[part 13 of 22: package /Cluster]
AUTOSAR XML (schema 4-3-0)
package /Cluster  (continued)
  9 x lin cluster, all with baudrate=19200, protocol-name=LIN, protocol-version=2.0:  (continued)
    E3V_SAM_LIN3
      lin physical channel CHNL: comm-connectors=CN_E3V_SAM_LIN3
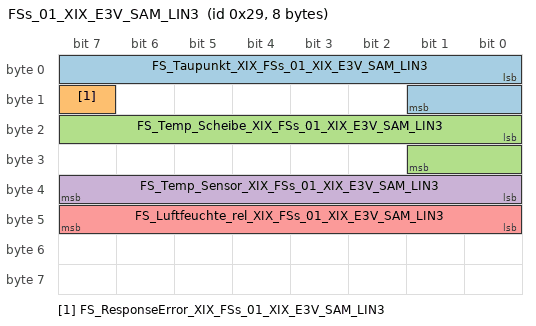
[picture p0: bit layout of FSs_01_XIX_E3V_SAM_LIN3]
        frame FSs_01_XIX_E3V_SAM_LIN3: id 0x29, to SAM, frame-length=8, lin-checksum=ENHANCED
          pdu FSs_01_XIX_E3V_SAM_LIN3: length=8, unused-bit-pattern=0
            signal FS_Taupunkt_XIX_FSs_01_XIX_E3V_SAM_LIN3: start 0, 10 bit, little-endian, data-type-policy=OVERRIDE, i-signal-type=PRIMITIVE, init-value=0, base-type=BT_FS_Taupunkt, invalid-value=Invalid_FS_Taupunkt_XIX_FSs_01_XIX_E3V_SAM_LIN3:1023, compu {0=Cx0_nicht_verfuegbar (CM_FS_Taupunkt_Cx0_nicht_verfuegbar) (nicht verfuegbar), phys=raw*0.1-39.6 for raw 1..1000, 1023=Cx3ff_Fehler (CM_FS_Taupunkt_Cx3ff_Fehler); unit Unit_DegreCelsi}, range phys -39.5..60.4 Unit_DegreCelsi, raw 0..1023, unit=Unit_DegreCelsi, transfer-property=PENDING, to SAM(timeout 3.5 s)  # berechneter Taupunkt
            signal FS_ResponseError_XIX_FSs_01_XIX_E3V_SAM_LIN3: start 15, 1 bit, little-endian, data-type-policy=OVERRIDE, i-signal-type=PRIMITIVE, init-value=0, base-type=BT_FS_ResponseError, invalid-value=Invalid_FS_ResponseError_XIX_FSs_01_XIX_E3V_SAM_LIN3:1, compu {0=Cx0_normal (CM_FS_ResponseError_Cx0_normal), 1=Cx1_Fehler (CM_FS_ResponseError_Cx1_Fehler)}, range raw 0..1, transfer-property=PENDING, to SAM(timeout 3.5 s)  # siehe LIN2.0-Specification (Darf nicht über ein Fehlergueltigkeitsbit abgesichtert werden!)
            signal FS_Temp_Scheibe_XIX_FSs_01_XIX_E3V_SAM_LIN3: start 16, 10 bit, little-endian, data-type-policy=OVERRIDE, i-signal-type=PRIMITIVE, init-value=0, base-type=BT_FS_Temp_Scheibe, invalid-value=Invalid_FS_Temp_Scheibe_XIX_FSs_01_XIX_E3V_SAM_LIN3:1023, compu {0=Cx0_nicht_verfuegbar (CM_FS_Temp_Scheibe_Cx0_nicht_verfuegbar) (nicht verfuegbar), phys=raw*0.1-39.6 for raw 1..1000, 1023=Cx3ff_Fehler (CM_FS_Temp_Scheibe_Cx3ff_Fehler); unit Unit_DegreCelsi}, range phys -39.5..60.4 Unit_DegreCelsi, raw 0..1023, unit=Unit_DegreCelsi, transfer-property=PENDING, to SAM(timeout 3.5 s)  # gemessene Frontscheibentemperatur
            signal FS_Temp_Sensor_XIX_FSs_01_XIX_E3V_SAM_LIN3: start 32, 8 bit, little-endian, data-type-policy=OVERRIDE, i-signal-type=PRIMITIVE, init-value=0, base-type=BT_FS_Temp_Sensor, invalid-value=Invalid_FS_Temp_Sensor_XIX_FSs_01_XIX_E3V_SAM_LIN3:255, compu {0=Cx0_nicht_verfuegbar (CM_FS_Temp_Sensor_Cx0_nicht_verfuegbar) (nicht verfuegbar), phys=raw*0.5-40 for raw 1..254, 255=Cxff_Fehler (CM_FS_Temp_Sensor_Cxff_Fehler); unit Unit_DegreCelsi}, range phys -39.5..87 Unit_DegreCelsi, raw 0..255, unit=Unit_DegreCelsi, transfer-property=PENDING, to SAM(timeout 3.5 s)  # gemessene Sensortemperatur
            signal FS_Luftfeuchte_rel_XIX_FSs_01_XIX_E3V_SAM_LIN3: start 40, 8 bit, little-endian, data-type-policy=OVERRIDE, i-signal-type=PRIMITIVE, init-value=0, base-type=BT_FS_Luftfeuchte_rel, invalid-value=Invalid_FS_Luftfeuchte_rel_XIX_FSs_01_XIX_E3V_SAM_LIN3:255, compu {0=Cx0_nicht_verfuegbar (CM_FS_Luftfeuchte_rel_Cx0_nicht_verfuegbar) (nicht verfuegbar), phys=raw*0.5-0.5 for raw 1..201, 255=Cxff_Fehler (CM_FS_Luftfeuchte_rel_Cxff_Fehler); unit Unit_PerCent}, range phys 0..100 Unit_PerCent, raw 0..255, unit=Unit_PerCent, transfer-property=PENDING, to SAM(timeout 3.5 s)  # gemessene relative Luftfeuchte
        frame LINDae_01_XIX_E3V_SAM_LIN3: id 0x1A, from SAM, frame-length=8, lin-checksum=ENHANCED
          pdu LINDae_01_XIX_E3V_SAM_LIN3: length=8, unused-bit-pattern=0
            signal LIM_P_Mode_XIX_LINDae_01_XIX_E3V_SAM_LIN3: start 3, 1 bit, little-endian, data-type-policy=OVERRIDE, i-signal-type=PRIMITIVE, init-value=0, base-type=BT_LIM_P_Mode, compu {0=Cx0_P_Mode_inaktiv (CM_LIM_P_Mode_Cx0_P_Mode_inaktiv), 1=Cx1_P_Mode_aktiv (CM_LIM_P_Mode_Cx1_P_Mode_aktiv)}, range raw 0..1, transfer-property=PENDING  # P-Mode für LIN-Dachkonsole. Bei aktivem P-Mode sind alle Bedien- und Innenlichtfunktionen der Dachkonsole unterdrückt.
            signal IL_Dachkonsole_Dimmzeit_XIX_LINDae_01_XIX_E3V_SAM_LIN3: start 4, 4 bit, little-endian, data-type-policy=OVERRIDE, i-signal-type=PRIMITIVE, init-value=0, base-type=BT_IL_Dachkonsole_Dimmzeit, compu {phys=raw for raw 0..15; unit Unit_None}, range phys 0..15 Unit_None, raw 0..15, unit=Unit_None, transfer-property=PENDING  # Gibt die Zeit an, in der die Zielhelligkeit des Ausgangs gedimmt erreicht werden soll. Diese sind als Multiplikator der Zeitbasis 250 ms oder 50 ms aufzufassen.
            signal IL_Dachkonsole_Zielhelligkeit_XIX_LINDae_01_XIX_E3V_SAM_LIN3: start 8, 7 bit, little-endian, data-type-policy=OVERRIDE, i-signal-type=PRIMITIVE, init-value=126, base-type=BT_IL_Dachkonsole_Zielhelligkeit, invalid-value=Invalid_IL_Dachkonsole_Zielhelligkeit_XIX_LINDae_01_XIX_E3V_SAM_LIN3:127, compu {phys=raw for raw 0..100, 126=Cx7e_Init (CM_IL_Dachkonsole_Zielhelligkeit_Cx7e_Init), 127=Cx7f_Fehler (CM_IL_Dachkonsole_Zielhelligkeit_Cx7f_Fehler); unit Unit_PerCent}, range phys 0..100 Unit_PerCent, raw 0..127, unit=Unit_PerCent, transfer-property=PENDING  # Gibt den Helligkeits-Sollwert in Prozent an. Zulässig sind Werte zwischen 0 und 100.
            signal IL_Dachkonsole_Zeitbasis_XIX_LINDae_01_XIX_E3V_SAM_LIN3: start 15, 1 bit, little-endian, data-type-policy=OVERRIDE, i-signal-type=PRIMITIVE, init-value=0, base-type=BT_IL_Dachkonsole_Zeitbasis, compu {0=Cx0_Zeitbasis_50_ms (CM_IL_Dachkonsole_Zeitbasis_Cx0_Zeitbasis_50_ms), 1=Cx1_Zeitbasis_250_ms (CM_IL_Dachkonsole_Zeitbasis_Cx1_Zeitbasis_250_ms)}, range raw 0..1, transfer-property=PENDING  # Schaltet zwischen den beiden Zeitbasen für die Dimmung der Innenleuchten um.
            signal IL_Dachkonsole_Adressat_XIX_LINDae_01_XIX_E3V_SAM_LIN3: start 16, 6 bit, little-endian, data-type-policy=OVERRIDE, i-signal-type=PRIMITIVE, init-value=0, base-type=BT_IL_Dachkonsole_Adressat, compu {phys=raw for raw 0..63; unit Unit_None}, range phys 0..63 Unit_None, raw 0..63, unit=Unit_None, transfer-property=PENDING  # Das Signal ist bitcodiert und gibt an, welche Leuchte Empfänger der Helligkeits- und Dimmzeit ist und die gesendeten Informationen umsetzt. Durch die Bitcodierung können null bis sechs Leuchten in einer Botschaft adressiert werden.
            signal bCall_active_XIX_LINDae_01_XIX_E3V_SAM_LIN3: start 22, 1 bit, little-endian, data-type-policy=OVERRIDE, i-signal-type=PRIMITIVE, base-type=BT_bCall_active, compu {0=Cx0_bcall_inactive (CM_bCall_active_Cx0_bcall_inactive), 1=Cx1_bcall_active (CM_bCall_active_Cx1_bcall_active)}, range raw 0..1, transfer-property=PENDING  # 1: Breakdown call is active 0: BreakdownCall is inactive
            signal iCall_active_XIX_LINDae_01_XIX_E3V_SAM_LIN3: start 23, 1 bit, little-endian, data-type-policy=OVERRIDE, i-signal-type=PRIMITIVE, init-value=0, base-type=BT_iCall_active, compu {0=Cx0_inaktiv (CM_iCall_active_Cx0_inaktiv), 1=Cx1_aktiv (CM_iCall_active_Cx1_aktiv)}, range raw 0..1, transfer-property=PENDING  # Statusrückmeldung von OCU über Infocall aktiv/inaktiv
            signal Tuerkontakt_Innenlicht_Status_XIX_LINDae_01_XIX_E3V_SAM_LIN3: start 24, 1 bit, little-endian, data-type-policy=OVERRIDE, i-signal-type=PRIMITIVE, init-value=1, base-type=BT_Tuerkontakt_Innenlicht_Status, compu {0=Cx0_Tuerkontakt_nicht_gesetzt (CM_Tuerkontakt_Innenlicht_Status_Cx0_Tuerkontakt_nicht_gesetzt), 1=Cx1_Tuerkontakt_gesetzt (CM_Tuerkontakt_Innenlicht_Status_Cx1_Tuerkontakt_gesetzt)}, range raw 0..1, transfer-property=PENDING  # Gibt den im BCM gespeicherten Wert über den Kundenwunsch der Türkontakt-Lichtfunktion an. Kann über Dachkonsole oder Personalisierung geändert werden.
            signal MF_Innenraumbel_XIX_LINDae_01_XIX_E3V_SAM_LIN3: start 25, 1 bit, little-endian, data-type-policy=OVERRIDE, i-signal-type=PRIMITIVE, init-value=0, base-type=BT_MF_Innenraumbel, compu {0=Cx0_inaktiv (CM_MF_Innenraumbel_Cx0_inaktiv), 1=Cx1_aktiv (CM_MF_Innenraumbel_Cx1_aktiv)}, range raw 0..1, transfer-property=PENDING  # sämtliche Beleuchtungen akitivieren (Fussraum, Tür u.a.)
            signal MF_Innenraumbel_Unterdrueck_XIX_LINDae_01_XIX_E3V_SAM_LIN3: start 26, 1 bit, little-endian, data-type-policy=OVERRIDE, i-signal-type=PRIMITIVE, init-value=0, base-type=BT_MF_Innenraumbel_Unterdrueck, compu {0=Cx0_inaktiv (CM_MF_Innenraumbel_Unterdrueck_Cx0_inaktiv), 1=Cx1_aktiv (CM_MF_Innenraumbel_Unterdrueck_Cx1_aktiv)}, range raw 0..1, transfer-property=PENDING  # Unterdrückung des Innenlichts/Fussraumbeleuchtung, sowie Schließblinken
            signal SI_QRS_Mode_XIX_LINDae_01_XIX_E3V_SAM_LIN3: start 27, 1 bit, little-endian, data-type-policy=OVERRIDE, i-signal-type=PRIMITIVE, init-value=0, base-type=BT_SI_QRS_Mode, compu {0=Cx0_QRS_Messmodus_nicht_aktiv (CM_SI_QRS_Mode_Cx0_QRS_Messmodus_nicht_aktiv), 1=Cx1_QRS_Messmodus_aktiv (CM_SI_QRS_Mode_Cx1_QRS_Messmodus_aktiv)}, range raw 0..1, transfer-property=PENDING  # Messmodus Quick-Ruhestrom
            signal SI_T_Mode_XIX_LINDae_01_XIX_E3V_SAM_LIN3: start 28, 1 bit, little-endian, data-type-policy=OVERRIDE, i-signal-type=PRIMITIVE, init-value=0, base-type=BT_SI_T_Mode, compu {0=Cx0_Transportmodus_nicht_aktiv (CM_SI_T_Mode_Cx0_Transportmodus_nicht_aktiv), 1=Cx1_Transportmodus_aktiv (CM_SI_T_Mode_Cx1_Transportmodus_aktiv)}, range raw 0..1, transfer-property=PENDING  # 0x0: Transportmodus nicht aktiv 0x1: Transportmodus aktiv
            signal NVEM_Abschaltstufe_XIX_LINDae_01_XIX_E3V_SAM_LIN3: start 29, 2 bit, little-endian, data-type-policy=OVERRIDE, i-signal-type=PRIMITIVE, base-type=BT_NVEM_Abschaltstufe, compu {0=Cx0_Stufe_0_keine_Einschraenkung (CM_NVEM_Abschaltstufe_Cx0_Stufe_0_keine_Einschraenkung), 1=Cx1_Stufe_1 (CM_NVEM_Abschaltstufe_Cx1_Stufe_1), 2=Cx2_Stufe_2 (CM_NVEM_Abschaltstufe_Cx2_Stufe_2), 3=Cx3_Stufe_3 (CM_NVEM_Abschaltstufe_Cx3_Stufe_3)}, range raw 0..3, transfer-property=PENDING  # Abschaltstufe aus dem Ruheenergiemanagement Maßnahmen des Empfängers werden im QLAH Ruhestrommanagement definiert
            signal LINDae_Dummy_4_7_XIX_LINDae_01_XIX_E3V_SAM_LIN3: start 31, 1 bit, little-endian, data-type-policy=OVERRIDE, i-signal-type=PRIMITIVE, init-value=0, base-type=BT_LINDae_Dummy_4_7, compu {phys=raw for raw 0..1; unit Unit_None}, range phys 0..1 Unit_None, raw 0..1, unit=Unit_None, transfer-property=PENDING  # Signal muss dauerhaft mit dem Wert '0' gesendet werden, um Rückwärtskompatibilität beim Empfänger zu gewährleisten.
            signal MD1_Position_XIX_LINDae_01_XIX_E3V_SAM_LIN3: start 32, 7 bit, little-endian, data-type-policy=OVERRIDE, i-signal-type=PRIMITIVE, init-value=126, base-type=BT_MD1_Position, compu {phys=raw for raw 0..100, 126=Cx7e_Init (CM_MD1_Position_Cx7e_Init), 127=Cx7f_nicht_normiert (CM_MD1_Position_Cx7f_nicht_normiert); unit Unit_PerCent}, range phys 0..100 Unit_PerCent, raw 0..127, unit=Unit_PerCent, transfer-property=PENDING  # Aktuelle Öffnungsweite Schiebedach.
            signal MD1_Lage_XIX_LINDae_01_XIX_E3V_SAM_LIN3: start 39, 1 bit, little-endian, data-type-policy=OVERRIDE, i-signal-type=PRIMITIVE, init-value=0, base-type=BT_MD1_Lage, compu {0=Cx0_Ausstelllage (CM_MD1_Lage_Cx0_Ausstelllage), 1=Cx1_Schiebelage (CM_MD1_Lage_Cx1_Schiebelage)}, range raw 0..1, transfer-property=PENDING  # Lage Schiebedachstellung 1 (Signal wird 1:1 vom BCM2 geroutet; ursprünglicher Sender: SAD = LIN-Slave vom BCM2)
            signal DI_KL_58xd_XIX_LINDae_01_XIX_E3V_SAM_LIN3: start 40, 8 bit, little-endian, data-type-policy=OVERRIDE, i-signal-type=PRIMITIVE, init-value=254, base-type=BT_DI_KL_58xd, invalid-value=Invalid_DI_KL_58xd_XIX_LINDae_01_XIX_E3V_SAM_LIN3:255, compu {phys=raw for raw 0..253, 254=Cxfe_Init (CM_DI_KL_58xd_Cxfe_Init), 255=Cxff_Fehler (CM_DI_KL_58xd_Cxff_Fehler)}, range phys 0..253, raw 0..255, transfer-property=PENDING  # Klemme 58xd Display- und Funktionsbeleuchtung Mit der Klemme 58xd wird die Helligkeit der Display- und der Funktionsbeleuchtungen der Schalter gesteuert. Im Detail beschrieben im 'Funktionslastenheft Dimmung MQB'.
            signal DI_KL_58xs_XIX_LINDae_01_XIX_E3V_SAM_LIN3: start 48, 7 bit, little-endian, data-type-policy=OVERRIDE, i-signal-type=PRIMITIVE, init-value=126, base-type=BT_DI_KL_58xs, invalid-value=Invalid_DI_KL_58xs_XIX_LINDae_01_XIX_E3V_SAM_LIN3:127, compu {phys=raw for raw 0..100, 126=Cx7e_Init (CM_DI_KL_58xs_Cx7e_Init), 127=Cx7f_Fehler (CM_DI_KL_58xs_Cx7f_Fehler); unit Unit_PerCent}, range phys 0..100 Unit_PerCent, raw 0..127, unit=Unit_PerCent, transfer-property=PENDING  # Suchbeleuchtung Schalter EIN-AUS-Schaltalgorithmus der allgemeinen Schaltersuchbeleuchtung. Im Detail beschrieben im 'Funktionslastenheft Dimmung MQB'.
            signal IL_Klemme_30G_aktiv_XIX_LINDae_01_XIX_E3V_SAM_LIN3: start 55, 1 bit, little-endian, data-type-policy=OVERRIDE, i-signal-type=PRIMITIVE, init-value=0, base-type=BT_IL_Klemme_30G_aktiv, compu {0=Cx0_Kl_30G_abgeschaltet (CM_IL_Klemme_30G_aktiv_Cx0_Kl_30G_abgeschaltet), 1=Cx1_eingeschaltet (CM_IL_Klemme_30G_aktiv_Cx1_eingeschaltet)}, range raw 0..1, transfer-property=PENDING  # Synchrones Abschalten
            signal DI_KL_58xt_XIX_LINDae_01_XIX_E3V_SAM_LIN3: start 56, 7 bit, little-endian, data-type-policy=OVERRIDE, i-signal-type=PRIMITIVE, init-value=126, base-type=BT_DI_KL_58xt, invalid-value=Invalid_DI_KL_58xt_XIX_LINDae_01_XIX_E3V_SAM_LIN3:127, compu {phys=raw for raw 0..100, 126=Cx7e_Init (CM_DI_KL_58xt_Cx7e_Init), 127=Cx7f_Fehler (CM_DI_KL_58xt_Cx7f_Fehler); unit Unit_PerCent}, range phys 0..100 Unit_PerCent, raw 0..127, unit=Unit_PerCent, transfer-property=PENDING  # Timergesteuerte Suchbeleuchtung Der EIN-AUS-Schaltalgorithmus für die vor- und nachlaufende Schaltersuchbeleuchtungen beim Ein- & Aussteigen; z.B.: Start/Stop-Taster. Im Detail beschrieben im 'Funktionslastenheft Dimmung MQB'.
            signal Klemme_15_XIX_LINDae_01_XIX_E3V_SAM_LIN3: start 63, 1 bit, little-endian, data-type-policy=OVERRIDE, i-signal-type=PRIMITIVE, init-value=0, base-type=BT_Klemme_15, compu {0=Cx0_Aus (CM_Klemme_15_Cx0_Aus), 1=Cx1_Ein (CM_Klemme_15_Cx1_Ein)}, range raw 0..1, transfer-property=PENDING
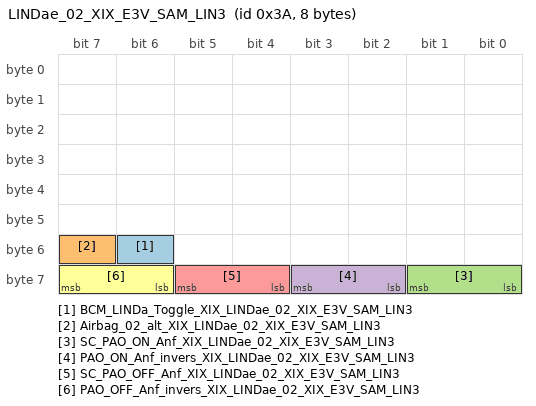
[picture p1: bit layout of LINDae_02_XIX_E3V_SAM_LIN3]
        frame LINDae_02_XIX_E3V_SAM_LIN3: id 0x3A, from SAM, frame-length=8, lin-checksum=ENHANCED
          pdu LINDae_02_XIX_E3V_SAM_LIN3: length=8, unused-bit-pattern=0
            signal BCM_LINDa_Toggle_XIX_LINDae_02_XIX_E3V_SAM_LIN3: start 54, 1 bit, little-endian, data-type-policy=OVERRIDE, i-signal-type=PRIMITIVE, base-type=BT_BCM_LINDa_Toggle, compu {phys=raw for raw 0..1; unit Unit_None}, range phys 0..1 Unit_None, raw 0..1, unit=Unit_None, transfer-property=PENDING  # Togglebit zur Kommunikationsabsicherung (ASIL A). Wert wird mit jedem Senden der Botschaft getoggelt.
            signal Airbag_02_alt_XIX_LINDae_02_XIX_E3V_SAM_LIN3: start 55, 1 bit, little-endian, data-type-policy=OVERRIDE, i-signal-type=PRIMITIVE, init-value=1, base-type=BT_Airbag_02_alt, compu {0=Cx0_aktuell (CM_Airbag_02_alt_Cx0_aktuell), 1=Cx1_veraltet (CM_Airbag_02_alt_Cx1_veraltet)}, range raw 0..1, transfer-property=PENDING
            signal SC_PAO_ON_Anf_XIX_LINDae_02_XIX_E3V_SAM_LIN3: start 56, 2 bit, little-endian, data-type-policy=OVERRIDE, i-signal-type=PRIMITIVE, init-value=0, base-type=BT_SC_PAO_ON_Anf, compu {0=Cx0_LED_aus (CM_SC_PAO_ON_Anf_Cx0_LED_aus) (LED aus), 1=Cx1_LED_an (CM_SC_PAO_ON_Anf_Cx1_LED_an) (LED an), 2=Cx2_LED_blinken (CM_SC_PAO_ON_Anf_Cx2_LED_blinken) (LED blinken), 3=Cx3_reserviert (CM_SC_PAO_ON_Anf_Cx3_reserviert)}, range raw 0..3, transfer-property=PENDING  # Sollwert für LED "ON" in Anzeige Passenger Airbag On/Off
            signal PAO_ON_Anf_invers_XIX_LINDae_02_XIX_E3V_SAM_LIN3: start 58, 2 bit, little-endian, data-type-policy=OVERRIDE, i-signal-type=PRIMITIVE, init-value=3, base-type=BT_PAO_ON_Anf_invers, compu {0=Cx0_reserviert (CM_PAO_ON_Anf_invers_Cx0_reserviert), 1=Cx1_LED_blinken (CM_PAO_ON_Anf_invers_Cx1_LED_blinken), 2=Cx2_LED_an (CM_PAO_ON_Anf_invers_Cx2_LED_an), 3=Cx3_LED_aus (CM_PAO_ON_Anf_invers_Cx3_LED_aus)}, range raw 0..3, transfer-property=PENDING  # Inverssignal Sollwert für LED "ON" in Anzeige Passenger Airbag On/Off
            signal SC_PAO_OFF_Anf_XIX_LINDae_02_XIX_E3V_SAM_LIN3: start 60, 2 bit, little-endian, data-type-policy=OVERRIDE, i-signal-type=PRIMITIVE, init-value=0, base-type=BT_SC_PAO_OFF_Anf, compu {0=Cx0_LED_aus (CM_SC_PAO_OFF_Anf_Cx0_LED_aus) (LED aus), 1=Cx1_LED_an (CM_SC_PAO_OFF_Anf_Cx1_LED_an) (LED an), 2=Cx2_LED_blinken (CM_SC_PAO_OFF_Anf_Cx2_LED_blinken) (LED blinken), 3=Cx3_reserviert (CM_SC_PAO_OFF_Anf_Cx3_reserviert)}, range raw 0..3, transfer-property=PENDING  # Sollwert für LED "OFF" in Anzeige Passenger Airbag On/Off
            signal PAO_OFF_Anf_invers_XIX_LINDae_02_XIX_E3V_SAM_LIN3: start 62, 2 bit, little-endian, data-type-policy=OVERRIDE, i-signal-type=PRIMITIVE, init-value=3, base-type=BT_PAO_OFF_Anf_invers, compu {0=Cx0_reserviert (CM_PAO_OFF_Anf_invers_Cx0_reserviert), 1=Cx1_LED_blinken (CM_PAO_OFF_Anf_invers_Cx1_LED_blinken), 2=Cx2_LED_an (CM_PAO_OFF_Anf_invers_Cx2_LED_an), 3=Cx3_LED_aus (CM_PAO_OFF_Anf_invers_Cx3_LED_aus)}, range raw 0..3, transfer-property=PENDING  # Inverssignal Sollwert für LED "OFF" in Anzeige Passenger Airbag On/Off
        frame LINDas_01_XIX_E3V_SAM_LIN3: id 0xF, to SAM, frame-length=8, lin-checksum=ENHANCED
          pdu LINDas_01_XIX_E3V_SAM_LIN3: length=8, unused-bit-pattern=0
            signal LINDa_reserveByte1_XIX_LINDas_01_XIX_E3V_SAM_LIN3: start 0, 8 bit, little-endian, data-type-policy=OVERRIDE, i-signal-type=PRIMITIVE, init-value=0, base-type=BT_LINDa_reserveByte1, transfer-property=PENDING  # Zweck: Befüllen der reservierten Bitpositionen mit 0
            signal LINDa_reserveByte2_XIX_LINDas_01_XIX_E3V_SAM_LIN3: start 8, 8 bit, little-endian, data-type-policy=OVERRIDE, i-signal-type=PRIMITIVE, init-value=0, base-type=BT_LINDa_reserveByte2, transfer-property=PENDING  # Zweck: Befüllen der reservierten Bitpositionen mit 0
            signal LINDa_reserveByte3_XIX_LINDas_01_XIX_E3V_SAM_LIN3: start 16, 4 bit, little-endian, data-type-policy=OVERRIDE, i-signal-type=PRIMITIVE, init-value=0, base-type=BT_LINDa_reserveByte3, transfer-property=PENDING  # Zweck: Befüllen der reservierten Bitpositionen mit 0
            signal LINDa_HL_Touch_Event_XIX_LINDas_01_XIX_E3V_SAM_LIN3: start 20, 4 bit, little-endian, data-type-policy=OVERRIDE, i-signal-type=PRIMITIVE, init-value=0, base-type=BT_LINDa_HL_Touch_Event, invalid-value=Invalid_LINDa_HL_Touch_Event_XIX_LINDas_01_XIX_E3V_SAM_LIN3:15, compu {0=Cx0_nicht_betaetigt (CM_LINDa_HL_Touch_Event_Cx0_nicht_betaetigt), 1=Cx1_Tippen (CM_LINDa_HL_Touch_Event_Cx1_Tippen), 2=Cx2_Wischen_Slide (CM_LINDa_HL_Touch_Event_Cx2_Wischen_Slide), 3=Cx3_Geste (CM_LINDa_HL_Touch_Event_Cx3_Geste), 4=Cx4_Doppeltippen (CM_LINDa_HL_Touch_Event_Cx4_Doppeltippen), 5=Cx5_Longpress_1 (CM_LINDa_HL_Touch_Event_Cx5_Longpress_1), 6=Cx6_Longpress_2 (CM_LINDa_HL_Touch_Event_Cx6_Longpress_2), 7=Cx7_Longpress_3 (CM_LINDa_HL_Touch_Event_Cx7_Longpress_3), 8=Cx8_Press (CM_LINDa_HL_Touch_Event_Cx8_Press), 9=Cx9_Strongpress (CM_LINDa_HL_Touch_Event_Cx9_Strongpress), 10=Cxa_reserviert (CM_LINDa_HL_Touch_Event_Cxa_reserviert), 11=Cxb_reserviert (CM_LINDa_HL_Touch_Event_Cxb_reserviert), 12=Cxc_reserviert (CM_LINDa_HL_Touch_Event_Cxc_reserviert), 13=Cxd_reserviert (CM_LINDa_HL_Touch_Event_Cxd_reserviert), 14=Cxe_Taktgeber_Inkrement (CM_LINDa_HL_Touch_Event_Cxe_Taktgeber_Inkrement), 15=Cxf_Fehler (CM_LINDa_HL_Touch_Event_Cxf_Fehler)}, range raw 0..15, transfer-property=PENDING, to SAM  # Touch_Events für Informationen einer Funktionsauslösung auf dem LINDa, welches dann für bspw. ein akustisches Signal zentral umgesetzt werden können.
            signal LINDa_HR_Touch_Event_XIX_LINDas_01_XIX_E3V_SAM_LIN3: start 24, 4 bit, little-endian, data-type-policy=OVERRIDE, i-signal-type=PRIMITIVE, init-value=0, base-type=BT_LINDa_HR_Touch_Event, invalid-value=Invalid_LINDa_HR_Touch_Event_XIX_LINDas_01_XIX_E3V_SAM_LIN3:15, compu {0=Cx0_nicht_betaetigt (CM_LINDa_HR_Touch_Event_Cx0_nicht_betaetigt), 1=Cx1_Tippen (CM_LINDa_HR_Touch_Event_Cx1_Tippen), 2=Cx2_Wischen_Slide (CM_LINDa_HR_Touch_Event_Cx2_Wischen_Slide), 3=Cx3_Geste (CM_LINDa_HR_Touch_Event_Cx3_Geste), 4=Cx4_Doppeltippen (CM_LINDa_HR_Touch_Event_Cx4_Doppeltippen), 5=Cx5_Longpress_1 (CM_LINDa_HR_Touch_Event_Cx5_Longpress_1), 6=Cx6_Longpress_2 (CM_LINDa_HR_Touch_Event_Cx6_Longpress_2), 7=Cx7_Longpress_3 (CM_LINDa_HR_Touch_Event_Cx7_Longpress_3), 8=Cx8_Press (CM_LINDa_HR_Touch_Event_Cx8_Press), 9=Cx9_Strongpress (CM_LINDa_HR_Touch_Event_Cx9_Strongpress), 10=Cxa_reserviert (CM_LINDa_HR_Touch_Event_Cxa_reserviert), 11=Cxb_reserviert (CM_LINDa_HR_Touch_Event_Cxb_reserviert), 12=Cxc_reserviert (CM_LINDa_HR_Touch_Event_Cxc_reserviert), 13=Cxd_reserviert (CM_LINDa_HR_Touch_Event_Cxd_reserviert), 14=Cxe_Taktgeber_Inkrement (CM_LINDa_HR_Touch_Event_Cxe_Taktgeber_Inkrement), 15=Cxf_Fehler (CM_LINDa_HR_Touch_Event_Cxf_Fehler)}, range raw 0..15, transfer-property=PENDING, to SAM  # Touch_Events für Informationen einer Funktionsauslösung auf dem LINDa, welches dann für bspw. ein akustisches Signal zentral umgesetzt werden können.
            signal LINDa_HL_SR3_Touch_Event_XIX_LINDas_01_XIX_E3V_SAM_LIN3: start 28, 4 bit, little-endian, data-type-policy=OVERRIDE, i-signal-type=PRIMITIVE, init-value=0, base-type=BT_LINDa_HL_SR3_Touch_Event, invalid-value=Invalid_LINDa_HL_SR3_Touch_Event_XIX_LINDas_01_XIX_E3V_SAM_LIN3:15, compu {0=Cx0_nicht_betaetigt (CM_LINDa_HL_SR3_Touch_Event_Cx0_nicht_betaetigt), 1=Cx1_Tippen (CM_LINDa_HL_SR3_Touch_Event_Cx1_Tippen), 2=Cx2_Wischen_Slide (CM_LINDa_HL_SR3_Touch_Event_Cx2_Wischen_Slide), 3=Cx3_Geste (CM_LINDa_HL_SR3_Touch_Event_Cx3_Geste), 4=Cx4_Doppeltippen (CM_LINDa_HL_SR3_Touch_Event_Cx4_Doppeltippen), 5=Cx5_Longpress_1 (CM_LINDa_HL_SR3_Touch_Event_Cx5_Longpress_1), 6=Cx6_Longpress_2 (CM_LINDa_HL_SR3_Touch_Event_Cx6_Longpress_2), 7=Cx7_Longpress_3 (CM_LINDa_HL_SR3_Touch_Event_Cx7_Longpress_3), 8=Cx8_Press (CM_LINDa_HL_SR3_Touch_Event_Cx8_Press), 9=Cx9_Strongpress (CM_LINDa_HL_SR3_Touch_Event_Cx9_Strongpress), 10=Cxa_reserviert (CM_LINDa_HL_SR3_Touch_Event_Cxa_reserviert), 11=Cxb_reserviert (CM_LINDa_HL_SR3_Touch_Event_Cxb_reserviert), 12=Cxc_reserviert (CM_LINDa_HL_SR3_Touch_Event_Cxc_reserviert), 13=Cxd_reserviert (CM_LINDa_HL_SR3_Touch_Event_Cxd_reserviert), 14=Cxe_Taktgeber_Inkrement (CM_LINDa_HL_SR3_Touch_Event_Cxe_Taktgeber_Inkrement), 15=Cxf_Fehler (CM_LINDa_HL_SR3_Touch_Event_Cxf_Fehler)}, range raw 0..15, transfer-property=PENDING, to SAM  # Touch_Events für Informationen einer Funktionsauslösung auf dem LINDa (hinten links SR3) , welches dann für bspw. ein akustisches Signal zentral umgesetzt werden können.
            signal LINDa_HR_SR3_Touch_Event_XIX_LINDas_01_XIX_E3V_SAM_LIN3: start 32, 4 bit, little-endian, data-type-policy=OVERRIDE, i-signal-type=PRIMITIVE, init-value=0, base-type=BT_LINDa_HR_SR3_Touch_Event, invalid-value=Invalid_LINDa_HR_SR3_Touch_Event_XIX_LINDas_01_XIX_E3V_SAM_LIN3:15, compu {0=Cx0_nicht_betaetigt (CM_LINDa_HR_SR3_Touch_Event_Cx0_nicht_betaetigt), 1=Cx1_Tippen (CM_LINDa_HR_SR3_Touch_Event_Cx1_Tippen), 2=Cx2_Wischen_Slide (CM_LINDa_HR_SR3_Touch_Event_Cx2_Wischen_Slide), 3=Cx3_Geste (CM_LINDa_HR_SR3_Touch_Event_Cx3_Geste), 4=Cx4_Doppeltippen (CM_LINDa_HR_SR3_Touch_Event_Cx4_Doppeltippen), 5=Cx5_Longpress_1 (CM_LINDa_HR_SR3_Touch_Event_Cx5_Longpress_1), 6=Cx6_Longpress_2 (CM_LINDa_HR_SR3_Touch_Event_Cx6_Longpress_2), 7=Cx7_Longpress_3 (CM_LINDa_HR_SR3_Touch_Event_Cx7_Longpress_3), 8=Cx8_Press (CM_LINDa_HR_SR3_Touch_Event_Cx8_Press), 9=Cx9_Strongpress (CM_LINDa_HR_SR3_Touch_Event_Cx9_Strongpress), 10=Cxa_reserviert (CM_LINDa_HR_SR3_Touch_Event_Cxa_reserviert), 11=Cxb_reserviert (CM_LINDa_HR_SR3_Touch_Event_Cxb_reserviert), 12=Cxc_reserviert (CM_LINDa_HR_SR3_Touch_Event_Cxc_reserviert), 13=Cxd_reserviert (CM_LINDa_HR_SR3_Touch_Event_Cxd_reserviert), 14=Cxe_Taktgeber_Inkrement (CM_LINDa_HR_SR3_Touch_Event_Cxe_Taktgeber_Inkrement), 15=Cxf_Fehler (CM_LINDa_HR_SR3_Touch_Event_Cxf_Fehler)}, range raw 0..15, transfer-property=PENDING, to SAM  # Touch_Events für Informationen einer Funktionsauslösung auf dem LINDa (hinten rechts SR3), welches dann für bspw. ein akustisches Signal zentral umgesetzt werden können.
            signal LINDa_reserveByte5_4_XIX_LINDas_01_XIX_E3V_SAM_LIN3: start 36, 2 bit, little-endian, data-type-policy=OVERRIDE, i-signal-type=PRIMITIVE, init-value=0, base-type=BT_LINDa_reserveByte5_4, transfer-property=PENDING  # Zweck: Befüllen der reservierten Bitpositionen mit 0
            signal Leselicht_hi_li_SR3_LED_defekt_XIX_LINDas_01_XIX_E3V_SAM_LIN3: start 38, 1 bit, little-endian, data-type-policy=OVERRIDE, i-signal-type=PRIMITIVE, init-value=0, base-type=BT_Leselicht_hi_li_SR3_LED_defekt, compu {0=Cx0_Leselicht_hi_li_SR3_iO (CM_Leselicht_hi_li_SR3_LED_defekt_Cx0_Leselicht_hi_li_SR3_iO), 1=Cx1_Leselicht_hi_li_SR3_defekt (CM_Leselicht_hi_li_SR3_LED_defekt_Cx1_Leselicht_hi_li_SR3_defekt)}, range raw 0..1, transfer-property=PENDING, to SAM(timeout 3.5 s)  # Funktionszustand Leselicht-LED der dritten Sitzreihe hinten links
            signal Leselicht_hi_li_SR3_Taste_defekt_XIX_LINDas_01_XIX_E3V_SAM_LIN3: start 39, 1 bit, little-endian, data-type-policy=OVERRIDE, i-signal-type=PRIMITIVE, init-value=0, base-type=BT_Leselicht_hi_li_SR3_Taste_defekt, compu {0=Cx0_Leselicht_hi_li_SR3_Taste_iO (CM_Leselicht_hi_li_SR3_Taste_defekt_Cx0_Leselicht_hi_li_SR3_Taste_iO), 1=Cx1_Leselicht_hi_li_SR3_Taste_defekt (CM_Leselicht_hi_li_SR3_Taste_defekt_Cx1_Leselicht_hi_li_SR3_Taste_defekt)}, range raw 0..1, transfer-property=PENDING, to SAM(timeout 3.5 s)  # Funktionszustand Leselicht-Taste der dritten Sitzreihe hinten links
            signal Leselicht_hi_re_SR3_LED_defekt_XIX_LINDas_01_XIX_E3V_SAM_LIN3: start 40, 1 bit, little-endian, data-type-policy=OVERRIDE, i-signal-type=PRIMITIVE, init-value=0, base-type=BT_Leselicht_hi_re_SR3_LED_defekt, compu {0=Cx0_Leselicht_hi_re_SR3_iO (CM_Leselicht_hi_re_SR3_LED_defekt_Cx0_Leselicht_hi_re_SR3_iO), 1=Cx1_Leselicht_hi_re_SR3_defekt (CM_Leselicht_hi_re_SR3_LED_defekt_Cx1_Leselicht_hi_re_SR3_defekt)}, range raw 0..1, transfer-property=PENDING, to SAM(timeout 3.5 s)  # Funktionszustand Leselicht-LED der dritten Sitzreihe hinten rechts
            signal Leselicht_hi_re_SR3_Taste_defekt_XIX_LINDas_01_XIX_E3V_SAM_LIN3: start 41, 1 bit, little-endian, data-type-policy=OVERRIDE, i-signal-type=PRIMITIVE, init-value=0, base-type=BT_Leselicht_hi_re_SR3_Taste_defekt, compu {0=Cx0_Leselicht_hi_re_SR3_Taste_iO (CM_Leselicht_hi_re_SR3_Taste_defekt_Cx0_Leselicht_hi_re_SR3_Taste_iO), 1=Cx1_Leselicht_hi_re_SR3_Taste_defekt (CM_Leselicht_hi_re_SR3_Taste_defekt_Cx1_Leselicht_hi_re_SR3_Taste_defekt)}, range raw 0..1, transfer-property=PENDING, to SAM(timeout 3.5 s)  # Funktionszustand Leselicht-Taste der dritten Sitzreihe hinten rechts
            signal LINDa_Touch_Event_XIX_LINDas_01_XIX_E3V_SAM_LIN3: start 42, 4 bit, little-endian, data-type-policy=OVERRIDE, i-signal-type=PRIMITIVE, init-value=0, base-type=BT_LINDa_Touch_Event, invalid-value=Invalid_LINDa_Touch_Event_XIX_LINDas_01_XIX_E3V_SAM_LIN3:15, compu {0=Cx0_nicht_betaetigt (CM_LINDa_Touch_Event_Cx0_nicht_betaetigt), 1=Cx1_Tippen (CM_LINDa_Touch_Event_Cx1_Tippen), 2=Cx2_Wischen_Slide (CM_LINDa_Touch_Event_Cx2_Wischen_Slide), 3=Cx3_Geste (CM_LINDa_Touch_Event_Cx3_Geste), 4=Cx4_Doppeltippen (CM_LINDa_Touch_Event_Cx4_Doppeltippen), 5=Cx5_Longpress_1 (CM_LINDa_Touch_Event_Cx5_Longpress_1), 6=Cx6_Longpress_2 (CM_LINDa_Touch_Event_Cx6_Longpress_2), 7=Cx7_Longpress_3 (CM_LINDa_Touch_Event_Cx7_Longpress_3), 8=Cx8_Press (CM_LINDa_Touch_Event_Cx8_Press), 9=Cx9_Strongpress (CM_LINDa_Touch_Event_Cx9_Strongpress), 10=Cxa_reserviert (CM_LINDa_Touch_Event_Cxa_reserviert), 11=Cxb_reserviert (CM_LINDa_Touch_Event_Cxb_reserviert), 12=Cxc_reserviert (CM_LINDa_Touch_Event_Cxc_reserviert), 13=Cxd_reserviert (CM_LINDa_Touch_Event_Cxd_reserviert), 14=Cxe_Taktgeber_Inkrement (CM_LINDa_Touch_Event_Cxe_Taktgeber_Inkrement), 15=Cxf_Fehler (CM_LINDa_Touch_Event_Cxf_Fehler)}, range raw 0..15, transfer-property=PENDING, to SAM  # Touch_Events für Informationen einer Funktionsauslösung auf dem LINDa, welches dann für bspw. ein akustisches Signal zentral umgesetzt werden können.
            signal Tuerkontakt_Innenlicht_Taste_XIX_LINDas_01_XIX_E3V_SAM_LIN3: start 46, 1 bit, little-endian, data-type-policy=OVERRIDE, i-signal-type=PRIMITIVE, init-value=0, base-type=BT_Tuerkontakt_Innenlicht_Taste, compu {0=Cx0_Taste_unbetaetigt (CM_Tuerkontakt_Innenlicht_Taste_Cx0_Taste_unbetaetigt), 1=Cx1_Taste_betaetigt (CM_Tuerkontakt_Innenlicht_Taste_Cx1_Taste_betaetigt)}, range raw 0..1, transfer-property=PENDING, to SAM(timeout 3.5 s)  # Taste zum Ändern des Türkontakt-Lichtfunktionszustandes.
            signal LIM_iCall_Taster_XIX_LINDas_01_XIX_E3V_SAM_LIN3: start 47, 1 bit, little-endian, data-type-policy=OVERRIDE, i-signal-type=PRIMITIVE, init-value=0, base-type=BT_LIM_iCall_Taster, compu {0=Cx0_nicht_betaetigt (CM_LIM_iCall_Taster_Cx0_nicht_betaetigt), 1=Cx1_betaetigt (CM_LIM_iCall_Taster_Cx1_betaetigt)}, range raw 0..1, transfer-property=PENDING, to SAM  # Betätigungsstatus des Info Call Tasters im Dachmodul
            signal LIM_S_SAD_Vo_XIX_LINDas_01_XIX_E3V_SAM_LIN3: start 48, 4 bit, little-endian, data-type-policy=OVERRIDE, i-signal-type=PRIMITIVE, init-value=0, base-type=BT_LIM_S_SAD_Vo, compu {0=Cx0_nicht_betaetigt (CM_LIM_S_SAD_Vo_Cx0_nicht_betaetigt), 1=Cx1_man_sl_zu (CM_LIM_S_SAD_Vo_Cx1_man_sl_zu), 2=Cx2_auto_sl_zu (CM_LIM_S_SAD_Vo_Cx2_auto_sl_zu), 3=Cx3_man_sl_auf (CM_LIM_S_SAD_Vo_Cx3_man_sl_auf), 4=Cx4_auto_sl_auf (CM_LIM_S_SAD_Vo_Cx4_auto_sl_auf), 5=Cx5_man_al_auf (CM_LIM_S_SAD_Vo_Cx5_man_al_auf), 6=Cx6_auto_al_auf (CM_LIM_S_SAD_Vo_Cx6_auto_al_auf), 7=Cx7_man_al_zu (CM_LIM_S_SAD_Vo_Cx7_man_al_zu), 8=Cx8_auto_al_zu (CM_LIM_S_SAD_Vo_Cx8_auto_al_zu), 9=Cx9_stop (CM_LIM_S_SAD_Vo_Cx9_stop), 10=Cxa_Toggle_Taster_AL_betaetigt (CM_LIM_S_SAD_Vo_Cxa_Toggle_Taster_AL_betaetigt), 14=Cxe_fehler_schalter_haengt (CM_LIM_S_SAD_Vo_Cxe_fehler_schalter_haengt), 15=Cxf_fehler_schalter_unplausibel (CM_LIM_S_SAD_Vo_Cxf_fehler_schalter_unplausibel)}, range raw 0..15, transfer-property=PENDING, to SAM  # Schalterfeld LIM für SAD vorne
            signal LINDa_S_Rollo_vo_XIX_LINDas_01_XIX_E3V_SAM_LIN3: start 52, 3 bit, little-endian, data-type-policy=OVERRIDE, i-signal-type=PRIMITIVE, init-value=0, base-type=BT_LINDa_S_Rollo_vo, compu {0=Cx0_nicht_betaetigt (CM_LINDa_S_Rollo_vo_Cx0_nicht_betaetigt), 1=Cx1_man_betaetigung_nach_fzg_vorne (CM_LINDa_S_Rollo_vo_Cx1_man_betaetigung_nach_fzg_vorne), 2=Cx2_auto_betaetigung_nach_fzg_vorne (CM_LINDa_S_Rollo_vo_Cx2_auto_betaetigung_nach_fzg_vorne), 3=Cx3_man_betaetigung_nach_fzg_hinten (CM_LINDa_S_Rollo_vo_Cx3_man_betaetigung_nach_fzg_hinten), 4=Cx4_auto_betaetigung_nach_fzg_hinten (CM_LINDa_S_Rollo_vo_Cx4_auto_betaetigung_nach_fzg_hinten), 5=Cx5_stopp (CM_LINDa_S_Rollo_vo_Cx5_stopp), 6=Cx6_fehler_bedienteil_haengt (CM_LINDa_S_Rollo_vo_Cx6_fehler_bedienteil_haengt), 7=Cx7_fehler_bedienteil_unplausibel (CM_LINDa_S_Rollo_vo_Cx7_fehler_bedienteil_unplausibel)}, range raw 0..7, transfer-property=PENDING, to SAM(timeout 3.5 s)  # Zur Ansteuerung des Panorama-(Schiebe-)Dach Sonnenrollos. Die uneinheitliche Verbauposition des Sonnenrollos in verschiedenen Fahrzeughüten bedingt ein Signal, in dem nur die Fahrtrichtung des Rollos vorgegeben ist, aber nicht öffnen/schließen.
            signal LIM_bCall_Taster_XIX_LINDas_01_XIX_E3V_SAM_LIN3: start 55, 1 bit, little-endian, data-type-policy=OVERRIDE, i-signal-type=PRIMITIVE, init-value=0, base-type=BT_LIM_bCall_Taster, compu {0=Cx0_nicht_betaetigt (CM_LIM_bCall_Taster_Cx0_nicht_betaetigt), 1=Cx1_betaetigt (CM_LIM_bCall_Taster_Cx1_betaetigt)}, range raw 0..1, transfer-property=PENDING, to SAM  # Statusinformation des Service Call Tasters im Dachmodul
            signal Leselicht_hi_li_LED_defekt_XIX_LINDas_01_XIX_E3V_SAM_LIN3: start 56, 1 bit, little-endian, data-type-policy=OVERRIDE, i-signal-type=PRIMITIVE, init-value=0, base-type=BT_Leselicht_hi_li_LED_defekt, compu {0=Cx0_Leselicht_hi_li_iO (CM_Leselicht_hi_li_LED_defekt_Cx0_Leselicht_hi_li_iO), 1=Cx1_Leselicht_hi_li_defekt (CM_Leselicht_hi_li_LED_defekt_Cx1_Leselicht_hi_li_defekt)}, range raw 0..1, transfer-property=PENDING, to SAM(timeout 3.5 s)  # Funktionszustand Leselicht-LED hinten links
            signal Leselicht_hi_li_Taste_defekt_XIX_LINDas_01_XIX_E3V_SAM_LIN3: start 57, 1 bit, little-endian, data-type-policy=OVERRIDE, i-signal-type=PRIMITIVE, init-value=0, base-type=BT_Leselicht_hi_li_Taste_defekt, compu {0=Cx0_Leselicht_hi_li_Taste_iO (CM_Leselicht_hi_li_Taste_defekt_Cx0_Leselicht_hi_li_Taste_iO), 1=Cx1_Leselicht_hi_li_Taste_defekt (CM_Leselicht_hi_li_Taste_defekt_Cx1_Leselicht_hi_li_Taste_defekt)}, range raw 0..1, transfer-property=PENDING, to SAM(timeout 3.5 s)  # Funktionszustand Leselicht-Taste hinten links
            signal Leselicht_hi_re_LED_defekt_XIX_LINDas_01_XIX_E3V_SAM_LIN3: start 58, 1 bit, little-endian, data-type-policy=OVERRIDE, i-signal-type=PRIMITIVE, init-value=0, base-type=BT_Leselicht_hi_re_LED_defekt, compu {0=Cx0_Leselicht_hi_re_iO (CM_Leselicht_hi_re_LED_defekt_Cx0_Leselicht_hi_re_iO), 1=Cx1_Leselicht_hi_re_defekt (CM_Leselicht_hi_re_LED_defekt_Cx1_Leselicht_hi_re_defekt)}, range raw 0..1, transfer-property=PENDING, to SAM(timeout 3.5 s)  # Funktionszustand Leselicht-LED hinten rechts
            signal Leselicht_hi_re_Taste_defekt_XIX_LINDas_01_XIX_E3V_SAM_LIN3: start 59, 1 bit, little-endian, data-type-policy=OVERRIDE, i-signal-type=PRIMITIVE, init-value=0, base-type=BT_Leselicht_hi_re_Taste_defekt, compu {0=Cx0_Leselicht_hi_re_Taste_iO (CM_Leselicht_hi_re_Taste_defekt_Cx0_Leselicht_hi_re_Taste_iO), 1=Cx1_Leselicht_hi_re_Taste_defekt (CM_Leselicht_hi_re_Taste_defekt_Cx1_Leselicht_hi_re_Taste_defekt)}, range raw 0..1, transfer-property=PENDING, to SAM(timeout 3.5 s)  # Funktionszustand Leselicht-Taste hinten rechts
            signal Leselicht_vo_defekt_XIX_LINDas_01_XIX_E3V_SAM_LIN3: start 60, 1 bit, little-endian, data-type-policy=OVERRIDE, i-signal-type=PRIMITIVE, init-value=0, base-type=BT_Leselicht_vo_defekt, compu {0=Cx0_Leselicht_iO (CM_Leselicht_vo_defekt_Cx0_Leselicht_iO), 1=Cx1_Leselicht_defekt (CM_Leselicht_vo_defekt_Cx1_Leselicht_defekt)}, range raw 0..1, transfer-property=PENDING, to SAM(timeout 3.5 s)  # Funktionszustand vorderes Leselicht (Fahrer/Beifahrer)
            signal LIM_Tasten_Innenlicht_V_def_XIX_LINDas_01_XIX_E3V_SAM_LIN3: start 61, 1 bit, little-endian, data-type-policy=OVERRIDE, i-signal-type=PRIMITIVE, init-value=0, base-type=BT_LIM_Tasten_Innenlicht_V_def, invalid-value=Invalid_LIM_Tasten_Innenlicht_V_def_XIX_LINDas_01_XIX_E3V_SAM_LIN3:1, compu {0=Cx0_normal (CM_LIM_Tasten_Innenlicht_V_def_Cx0_normal), 1=Cx1_Fehler (CM_LIM_Tasten_Innenlicht_V_def_Cx1_Fehler)}, range raw 0..1, transfer-property=PENDING, to SAM(timeout 3.5 s)  # Tasten vorne für Innenlicht vorne defekt
            signal LINDa_defekt_XIX_LINDas_01_XIX_E3V_SAM_LIN3: start 62, 1 bit, little-endian, data-type-policy=OVERRIDE, i-signal-type=PRIMITIVE, init-value=0, base-type=BT_LINDa_defekt, invalid-value=Invalid_LINDa_defekt_XIX_LINDas_01_XIX_E3V_SAM_LIN3:1, compu {0=Cx0_normal (CM_LINDa_defekt_Cx0_normal), 1=Cx1_Fehler (CM_LINDa_defekt_Cx1_Fehler)}, range raw 0..1, transfer-property=PENDING, to SAM(timeout 3.5 s)  # Dachkonsole defekt
            signal LINDa_ResponseError_XIX_LINDas_01_XIX_E3V_SAM_LIN3: start 63, 1 bit, little-endian, data-type-policy=OVERRIDE, i-signal-type=PRIMITIVE, init-value=0, base-type=BT_LINDa_ResponseError, invalid-value=Invalid_LINDa_ResponseError_XIX_LINDas_01_XIX_E3V_SAM_LIN3:1, compu {0=Cx0_normal (CM_LINDa_ResponseError_Cx0_normal), 1=Cx1_Fehler (CM_LINDa_ResponseError_Cx1_Fehler)}, range raw 0..1, transfer-property=PENDING, to SAM(timeout 3.5 s)  # siehe LIN2.0-Specification (Darf nicht über ein Fehlergueltigkeitsbit abgesichtert werden!)
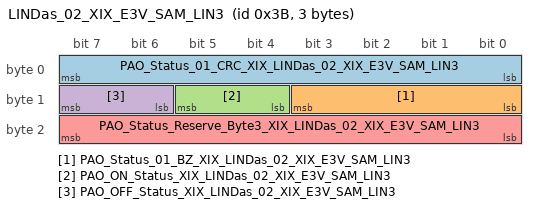
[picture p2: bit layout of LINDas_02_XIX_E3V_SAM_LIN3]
        frame LINDas_02_XIX_E3V_SAM_LIN3: id 0x3B, to SAM, frame-length=3, lin-checksum=ENHANCED
          pdu LINDas_02_XIX_E3V_SAM_LIN3: length=3, unused-bit-pattern=0
            signal PAO_Status_01_CRC_XIX_LINDas_02_XIX_E3V_SAM_LIN3: start 0, 8 bit, little-endian, data-type-policy=OVERRIDE, i-signal-type=PRIMITIVE, base-type=BT_PAO_Status_01_CRC, compu {phys=raw for raw 0..255}, range phys 0..255, raw 0..255, transfer-property=PENDING  # Für MLB: Berechnung siehe Lastenheft "Kommunikationsabsicherung für FlexRay und CAN" Ab MQB und MLBevo: Berechnung siehe Lastenheft "End-to-End Kommunikationsabsicherung" Endwerte siehe Begleitdokument "S-PDU Kennungsfolgen"
            signal PAO_Status_01_BZ_XIX_LINDas_02_XIX_E3V_SAM_LIN3: start 8, 4 bit, little-endian, data-type-policy=OVERRIDE, i-signal-type=PRIMITIVE, base-type=BT_PAO_Status_01_BZ, compu {phys=raw for raw 0..15}, range phys 0..15, raw 0..15, transfer-property=PENDING  # 4bit Botschaftszähler, wird mit jeder Sendebotschaft inkrementiert
            signal PAO_ON_Status_XIX_LINDas_02_XIX_E3V_SAM_LIN3: start 12, 2 bit, little-endian, data-type-policy=OVERRIDE, i-signal-type=PRIMITIVE, init-value=0, base-type=BT_PAO_ON_Status, compu {0=Cx0_LED_aus (CM_PAO_ON_Status_Cx0_LED_aus), 1=Cx1_LED_an (CM_PAO_ON_Status_Cx1_LED_an), 2=Cx2_LED_blinkt (CM_PAO_ON_Status_Cx2_LED_blinkt), 3=Cx3_LED_defekt (CM_PAO_ON_Status_Cx3_LED_defekt)}, range raw 0..3, transfer-property=PENDING  # Istwert für LED "ON" in Anzeige Passenger Airbag On/Off
            signal PAO_OFF_Status_XIX_LINDas_02_XIX_E3V_SAM_LIN3: start 14, 2 bit, little-endian, data-type-policy=OVERRIDE, i-signal-type=PRIMITIVE, init-value=0, base-type=BT_PAO_OFF_Status, compu {0=Cx0_LED_aus (CM_PAO_OFF_Status_Cx0_LED_aus), 1=Cx1_LED_an (CM_PAO_OFF_Status_Cx1_LED_an), 2=Cx2_LED_blinkt (CM_PAO_OFF_Status_Cx2_LED_blinkt), 3=Cx3_LED_defekt (CM_PAO_OFF_Status_Cx3_LED_defekt)}, range raw 0..3, transfer-property=PENDING  # Istwert für LED "OFF" in Anzeige Passenger Airbag On/Off
            signal PAO_Status_Reserve_Byte3_XIX_LINDas_02_XIX_E3V_SAM_LIN3: start 16, 8 bit, little-endian, data-type-policy=OVERRIDE, i-signal-type=PRIMITIVE, init-value=0, base-type=BT_PAO_Status_Reserve_Byte3, transfer-property=PENDING  # Zweck: Befüllen der reservierten Bitpositionen mit 0 (wg. LIN-Teilnehmer)
        frame MasterReq_XIX_E3V_SAM_LIN3: id 0x3C, from SAM, frame-length=8, lin-checksum=CLASSIC
          n pdu MasterReq_XIX_E3V_SAM_LIN3: length=8
        frame SlaveResp_XIX_E3V_SAM_LIN3: id 0x3D, to SAM, frame-length=8, lin-checksum=CLASSIC
          n pdu SlaveResp_XIX_E3V_SAM_LIN3: length=8
        pdu triggering PT_E3V_SAM_LIN3_XIX_TPCHType_LIN_Diagnose_XIX_0x0_XIX_0x1E_XIX_Physical: pdu=DCM_E3V_SAM_LIN3_XIX_TPCHType_LIN_Diagnose_XIX_0x0_XIX_0x1E_XIX_Physical, from SAM
        pdu triggering PT_E3V_SAM_LIN3_XIX_TPCHType_LIN_Diagnose_XIX_0x0_XIX_0x5E_XIX_Physical: pdu=DCM_E3V_SAM_LIN3_XIX_TPCHType_LIN_Diagnose_XIX_0x0_XIX_0x5E_XIX_Physical, from SAM
        pdu triggering PT_E3V_SAM_LIN3_XIX_TPCHType_LIN_Diagnose_XIX_0x1E_XIX_0x0_XIX_Physical: pdu=DCM_E3V_SAM_LIN3_XIX_TPCHType_LIN_Diagnose_XIX_0x1E_XIX_0x0_XIX_Physical, to SAM
        pdu triggering PT_E3V_SAM_LIN3_XIX_TPCHType_LIN_Diagnose_XIX_0x5E_XIX_0x0_XIX_Physical: pdu=DCM_E3V_SAM_LIN3_XIX_TPCHType_LIN_Diagnose_XIX_0x5E_XIX_0x0_XIX_Physical, to SAM
        lin schedule table DiagRequest: resume-position=CONTINUE-AT-IT-POSITION, run-mode=RUN-ONCE, application-entry{delay=0.01, position-in-table=0, frame-triggering=CHNL/FT_MasterReq}
        lin schedule table DiagResponse: resume-position=CONTINUE-AT-IT-POSITION, run-mode=RUN-ONCE, application-entry{delay=0.01, position-in-table=0, frame-triggering=CHNL/FT_SlaveResp}
        lin schedule table st_main: resume-position=CONTINUE-AT-IT-POSITION, run-mode=RUN-CONTINUOUS
          table-entrys:
            delay=0.02, position-in-table=0, frame-triggering=FT_LINDae_01
            delay=0.02, position-in-table=1, frame-triggering=FT_LINDas_01
            delay=0.02, position-in-table=2, frame-triggering=FT_LINDae_01
            delay=0.01, position-in-table=3, frame-triggering=FT_LINDas_01
            delay=0.01, position-in-table=4, frame-triggering=CHNL/FT_FSs_01
            delay=0.02, position-in-table=5, frame-triggering=FT_LINDae_01
            delay=0.02, position-in-table=6, frame-triggering=FT_LINDas_01
            delay=0.02, position-in-table=7, frame-triggering=FT_LINDae_01
            delay=0.01, position-in-table=8, frame-triggering=FT_LINDas_01
            delay=0.01, position-in-table=9, frame-triggering=FT_LINDae_02
            delay=0.02, position-in-table=10, frame-triggering=FT_LINDae_01
            delay=0.02, position-in-table=11, frame-triggering=FT_LINDas_01
            delay=0.02, position-in-table=12, frame-triggering=FT_LINDae_01
            delay=0.01, position-in-table=13, frame-triggering=FT_LINDas_01
            delay=0.01, position-in-table=14, frame-triggering=FT_LINDas_02
    E3V_SAM_LIN5
      lin physical channel CHNL: comm-connectors=CN_E3V_SAM_LIN5
        frame MasterReq_XIX_E3V_SAM_LIN5: id 0x3C, from SAM, frame-length=8, lin-checksum=CLASSIC
          n pdu MasterReq_XIX_E3V_SAM_LIN5: length=8
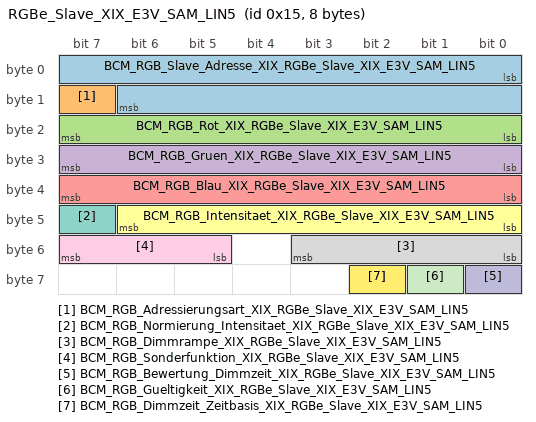
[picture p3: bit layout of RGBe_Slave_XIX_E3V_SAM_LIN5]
        frame RGBe_Slave_XIX_E3V_SAM_LIN5: id 0x15, from SAM, frame-length=8, lin-checksum=ENHANCED
          pdu RGBe_Slave_XIX_E3V_SAM_LIN5: length=8, unused-bit-pattern=0
            signal BCM_RGB_Slave_Adresse_XIX_RGBe_Slave_XIX_E3V_SAM_LIN5: start 0, 15 bit, little-endian, data-type-policy=OVERRIDE, i-signal-type=PRIMITIVE, base-type=BT_BCM_RGB_Slave_Adresse, compu {phys=raw for raw 0..32767; unit Unit_None}, range phys 0..32767 Unit_None, raw 0..32767, unit=Unit_None, transfer-property=PENDING  # Auswahl der Adresse für die RGB-Slaves (Hinweis: Adressierungsart beachten)
            signal BCM_RGB_Adressierungsart_XIX_RGBe_Slave_XIX_E3V_SAM_LIN5: start 15, 1 bit, little-endian, data-type-policy=OVERRIDE, i-signal-type=PRIMITIVE, base-type=BT_BCM_RGB_Adressierungsart, compu {0=Cx0_Einzeladresse (CM_BCM_RGB_Adressierungsart_Cx0_Einzeladresse), 1=Cx1_Gruppenadresse (CM_BCM_RGB_Adressierungsart_Cx1_Gruppenadresse)}, range raw 0..1, transfer-property=PENDING  # Auswahl der Adressierungsart für die RGB-Slaves: 0 = Einzeladadresse (Wertecodierung) 1 = Gruppenadresse
            signal BCM_RGB_Rot_XIX_RGBe_Slave_XIX_E3V_SAM_LIN5: start 16, 8 bit, little-endian, data-type-policy=OVERRIDE, i-signal-type=PRIMITIVE, base-type=BT_BCM_RGB_Rot, compu {phys=raw for raw 0..255}, range phys 0..255, raw 0..255, transfer-property=PENDING  # Farbanteil "Rot"
            signal BCM_RGB_Gruen_XIX_RGBe_Slave_XIX_E3V_SAM_LIN5: start 24, 8 bit, little-endian, data-type-policy=OVERRIDE, i-signal-type=PRIMITIVE, base-type=BT_BCM_RGB_Gruen, compu {phys=raw for raw 0..255}, range phys 0..255, raw 0..255, transfer-property=PENDING  # Farbanteil "Grün"
            signal BCM_RGB_Blau_XIX_RGBe_Slave_XIX_E3V_SAM_LIN5: start 32, 8 bit, little-endian, data-type-policy=OVERRIDE, i-signal-type=PRIMITIVE, base-type=BT_BCM_RGB_Blau, compu {phys=raw for raw 0..255}, range phys 0..255, raw 0..255, transfer-property=PENDING  # Farbanteil "Blau"
            signal BCM_RGB_Intensitaet_XIX_RGBe_Slave_XIX_E3V_SAM_LIN5: start 40, 7 bit, little-endian, data-type-policy=OVERRIDE, i-signal-type=PRIMITIVE, init-value=126, base-type=BT_BCM_RGB_Intensitaet, invalid-value=Invalid_BCM_RGB_Intensitaet_XIX_RGBe_Slave_XIX_E3V_SAM_LIN5:127, compu {phys=raw for raw 0..100, 126=Cx7e_Init (CM_BCM_RGB_Intensitaet_Cx7e_Init), 127=Cx7f_Fehler (CM_BCM_RGB_Intensitaet_Cx7f_Fehler); unit Unit_PerCent}, range phys 0..100 Unit_PerCent, raw 0..127, unit=Unit_PerCent, transfer-property=PENDING  # Intensität für RGB-Slave
            signal BCM_RGB_Normierung_Intensitaet_XIX_RGBe_Slave_XIX_E3V_SAM_LIN5: start 47, 1 bit, little-endian, data-type-policy=OVERRIDE, i-signal-type=PRIMITIVE, base-type=BT_BCM_RGB_Normierung_Intensitaet, compu {0=Cx0_ohne_Normierung (CM_BCM_RGB_Normierung_Intensitaet_Cx0_ohne_Normierung) (ohne Normierung), 1=Cx1_Normierung_der_Intensitaet (CM_BCM_RGB_Normierung_Intensitaet_Cx1_Normierung_der_Intensitaet) (Normierung der Intensität)}, range raw 0..1, transfer-property=PENDING  # Normierung der Intensität für die RGB-Slaves: 0 = keine Normierung 1 = Normierung
            signal BCM_RGB_Dimmrampe_XIX_RGBe_Slave_XIX_E3V_SAM_LIN5: start 48, 4 bit, little-endian, data-type-policy=OVERRIDE, i-signal-type=PRIMITIVE, base-type=BT_BCM_RGB_Dimmrampe, compu {phys=raw*0.25 for raw 0..15; unit Unit_Secon}, range phys 0..3.75 Unit_Secon, raw 0..15, unit=Unit_Secon, transfer-property=PENDING  # Vorgabe "Dimmzeit" für RGB-Slave
            signal BCM_RGB_Sonderfunktion_XIX_RGBe_Slave_XIX_E3V_SAM_LIN5: start 53, 3 bit, little-endian, data-type-policy=OVERRIDE, i-signal-type=PRIMITIVE, init-value=0, base-type=BT_BCM_RGB_Sonderfunktion, compu {0=Cx0_keine_Sonderfunktion (CM_BCM_RGB_Sonderfunktion_Cx0_keine_Sonderfunktion) (keine Sonderfunktion), 1=Cx1_Crash (CM_BCM_RGB_Sonderfunktion_Cx1_Crash), 2=Cx2_Showroommodus (CM_BCM_RGB_Sonderfunktion_Cx2_Showroommodus), 3=Cx3_Stellgliedtest (CM_BCM_RGB_Sonderfunktion_Cx3_Stellgliedtest), 4=Cx4_Vorhalt_z_B_FAS_Warnung (CM_BCM_RGB_Sonderfunktion_Cx4_Vorhalt_z_B_FAS_Warnung) (Vorhalt (z.B. FAS-Warnung)), 5=Cx5_Vorhalt (CM_BCM_RGB_Sonderfunktion_Cx5_Vorhalt), 6=Cx6_Lauflicht_Rueckwaerts (CM_BCM_RGB_Sonderfunktion_Cx6_Lauflicht_Rueckwaerts), 7=Cx7_Lauflicht_Vorwaerts (CM_BCM_RGB_Sonderfunktion_Cx7_Lauflicht_Vorwaerts)}, range raw 0..7, transfer-property=PENDING  # Aktivierung "Sonderfunktionen" im RGB-Slave
            signal BCM_RGB_Bewertung_Dimmzeit_XIX_RGBe_Slave_XIX_E3V_SAM_LIN5: start 56, 1 bit, little-endian, data-type-policy=OVERRIDE, i-signal-type=PRIMITIVE, base-type=BT_BCM_RGB_Bewertung_Dimmzeit, compu {0=Cx0_Dimmzeit_absolut (CM_BCM_RGB_Bewertung_Dimmzeit_Cx0_Dimmzeit_absolut), 1=Cx1_Dimmzeit_relativ (CM_BCM_RGB_Bewertung_Dimmzeit_Cx1_Dimmzeit_relativ)}, range raw 0..1, transfer-property=PENDING  # Interpretation der Dimmzeit im Slave: 0 - absolute Dimmzeit (von 0% auf 100%) 1 - relative Dimmzeit (von Ist- auf die Soll-Helligkeit)
            signal BCM_RGB_Gueltigkeit_XIX_RGBe_Slave_XIX_E3V_SAM_LIN5: start 57, 1 bit, little-endian, data-type-policy=OVERRIDE, i-signal-type=PRIMITIVE, base-type=BT_BCM_RGB_Gueltigkeit, compu {0=Cx0_ungueltig (CM_BCM_RGB_Gueltigkeit_Cx0_ungueltig), 1=Cx1_gueltig (CM_BCM_RGB_Gueltigkeit_Cx1_gueltig)}, range raw 0..1, transfer-property=PENDING  # Qualifizierungsinformation (notwendig bei der Übertragung "relativer" Dimmzeiten) 0 - Signale werden vom LIN-Slave ignoriert 1 - Signale sind vom LIN-Slave umzusetzen
            signal BCM_RGB_Dimmzeit_Zeitbasis_XIX_RGBe_Slave_XIX_E3V_SAM_LIN5: start 58, 1 bit, little-endian, data-type-policy=OVERRIDE, i-signal-type=PRIMITIVE, init-value=0, base-type=BT_BCM_RGB_Dimmzeit_Zeitbasis, compu {0=Cx0_Zeitbasis_50ms (CM_BCM_RGB_Dimmzeit_Zeitbasis_Cx0_Zeitbasis_50ms), 1=Cx1_Zeitbasis_250ms (CM_BCM_RGB_Dimmzeit_Zeitbasis_Cx1_Zeitbasis_250ms)}, range raw 0..1, transfer-property=PENDING  # Umschaltung der Zeitbasis für die Berechnung der Dimmzeit zwischen 250ms (Altwert, log. Signalwert: 1) und 50ms (log. Signalwert: 0)
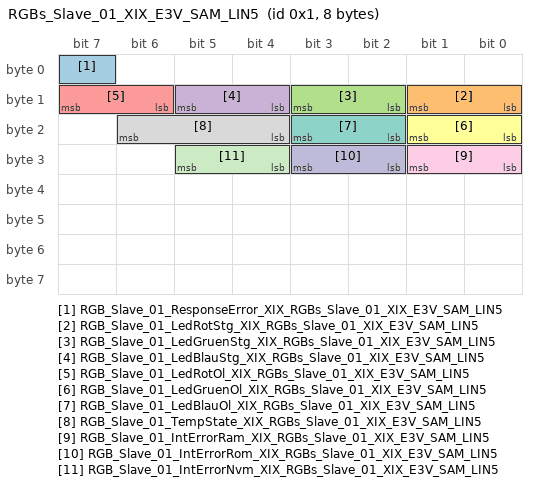
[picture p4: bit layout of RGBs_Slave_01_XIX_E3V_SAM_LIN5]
        frame RGBs_Slave_01_XIX_E3V_SAM_LIN5: id 0x1, to SAM, frame-length=8, lin-checksum=ENHANCED
          pdu RGBs_Slave_01_XIX_E3V_SAM_LIN5: length=8, unused-bit-pattern=0
            signal RGB_Slave_01_ResponseError_XIX_RGBs_Slave_01_XIX_E3V_SAM_LIN5: start 7, 1 bit, little-endian, data-type-policy=OVERRIDE, i-signal-type=PRIMITIVE, init-value=0, base-type=BT_RGB_Slave_01_ResponseError, invalid-value=Invalid_RGB_Slave_01_ResponseError_XIX_RGBs_Slave_01_XIX_E3V_SAM_LIN5:1, compu {0=Cx0_normal (CM_RGB_Slave_01_ResponseError_Cx0_normal), 1=Cx1_Fehler (CM_RGB_Slave_01_ResponseError_Cx1_Fehler)}, range raw 0..1, transfer-property=PENDING, to SAM(timeout 3.5 s)  # siehe LIN2.0-Specification (Darf nicht über ein Fehlergueltigkeitsbit abgesichtert werden!)
            signal RGB_Slave_01_LedRotStg_XIX_RGBs_Slave_01_XIX_E3V_SAM_LIN5: start 8, 2 bit, little-endian, data-type-policy=OVERRIDE, i-signal-type=PRIMITIVE, init-value=0, base-type=BT_RGB_Slave_01_LedRotStg, invalid-value=Invalid_RGB_Slave_01_LedRotStg_XIX_RGBs_Slave_01_XIX_E3V_SAM_LIN5:3, compu {0=Cx0_Init (CM_RGB_Slave_01_LedRotStg_Cx0_Init), 1=Cx1_nicht_erlaubt (CM_RGB_Slave_01_LedRotStg_Cx1_nicht_erlaubt), 2=Cx2_kein_Fehler (CM_RGB_Slave_01_LedRotStg_Cx2_kein_Fehler), 3=Cx3_Fehler (CM_RGB_Slave_01_LedRotStg_Cx3_Fehler)}, range raw 0..3, transfer-property=PENDING, to SAM(timeout 3.5 s)  # Short To Ground für Rote LED
            signal RGB_Slave_01_LedGruenStg_XIX_RGBs_Slave_01_XIX_E3V_SAM_LIN5: start 10, 2 bit, little-endian, data-type-policy=OVERRIDE, i-signal-type=PRIMITIVE, init-value=0, base-type=BT_RGB_Slave_01_LedGruenStg, invalid-value=Invalid_RGB_Slave_01_LedGruenStg_XIX_RGBs_Slave_01_XIX_E3V_SAM_LIN5:3, compu {0=Cx0_Init (CM_RGB_Slave_01_LedGruenStg_Cx0_Init), 1=Cx1_nicht_erlaubt (CM_RGB_Slave_01_LedGruenStg_Cx1_nicht_erlaubt), 2=Cx2_kein_Fehler (CM_RGB_Slave_01_LedGruenStg_Cx2_kein_Fehler), 3=Cx3_Fehler (CM_RGB_Slave_01_LedGruenStg_Cx3_Fehler)}, range raw 0..3, transfer-property=PENDING, to SAM(timeout 3.5 s)  # Short To Ground für Grüne LED
            signal RGB_Slave_01_LedBlauStg_XIX_RGBs_Slave_01_XIX_E3V_SAM_LIN5: start 12, 2 bit, little-endian, data-type-policy=OVERRIDE, i-signal-type=PRIMITIVE, init-value=0, base-type=BT_RGB_Slave_01_LedBlauStg, invalid-value=Invalid_RGB_Slave_01_LedBlauStg_XIX_RGBs_Slave_01_XIX_E3V_SAM_LIN5:3, compu {0=Cx0_Init (CM_RGB_Slave_01_LedBlauStg_Cx0_Init), 1=Cx1_nicht_erlaubt (CM_RGB_Slave_01_LedBlauStg_Cx1_nicht_erlaubt), 2=Cx2_kein_Fehler (CM_RGB_Slave_01_LedBlauStg_Cx2_kein_Fehler), 3=Cx3_Fehler (CM_RGB_Slave_01_LedBlauStg_Cx3_Fehler)}, range raw 0..3, transfer-property=PENDING, to SAM(timeout 3.5 s)  # Short To Ground für Blaue LED
            signal RGB_Slave_01_LedRotOl_XIX_RGBs_Slave_01_XIX_E3V_SAM_LIN5: start 14, 2 bit, little-endian, data-type-policy=OVERRIDE, i-signal-type=PRIMITIVE, init-value=0, base-type=BT_RGB_Slave_01_LedRotOl, invalid-value=Invalid_RGB_Slave_01_LedRotOl_XIX_RGBs_Slave_01_XIX_E3V_SAM_LIN5:3, compu {0=Cx0_Init (CM_RGB_Slave_01_LedRotOl_Cx0_Init), 1=Cx1_nicht_erlaubt (CM_RGB_Slave_01_LedRotOl_Cx1_nicht_erlaubt), 2=Cx2_kein_Fehler (CM_RGB_Slave_01_LedRotOl_Cx2_kein_Fehler), 3=Cx3_Fehler (CM_RGB_Slave_01_LedRotOl_Cx3_Fehler)}, range raw 0..3, transfer-property=PENDING, to SAM(timeout 3.5 s)  # OpenLoad für Rote LED
            signal RGB_Slave_01_LedGruenOl_XIX_RGBs_Slave_01_XIX_E3V_SAM_LIN5: start 16, 2 bit, little-endian, data-type-policy=OVERRIDE, i-signal-type=PRIMITIVE, init-value=0, base-type=BT_RGB_Slave_01_LedGruenOl, invalid-value=Invalid_RGB_Slave_01_LedGruenOl_XIX_RGBs_Slave_01_XIX_E3V_SAM_LIN5:3, compu {0=Cx0_Init (CM_RGB_Slave_01_LedGruenOl_Cx0_Init), 1=Cx1_nicht_erlaubt (CM_RGB_Slave_01_LedGruenOl_Cx1_nicht_erlaubt), 2=Cx2_kein_Fehler (CM_RGB_Slave_01_LedGruenOl_Cx2_kein_Fehler), 3=Cx3_Fehler (CM_RGB_Slave_01_LedGruenOl_Cx3_Fehler)}, range raw 0..3, transfer-property=PENDING, to SAM(timeout 3.5 s)  # OpenLoad für Rote LED
            signal RGB_Slave_01_LedBlauOl_XIX_RGBs_Slave_01_XIX_E3V_SAM_LIN5: start 18, 2 bit, little-endian, data-type-policy=OVERRIDE, i-signal-type=PRIMITIVE, init-value=0, base-type=BT_RGB_Slave_01_LedBlauOl, invalid-value=Invalid_RGB_Slave_01_LedBlauOl_XIX_RGBs_Slave_01_XIX_E3V_SAM_LIN5:3, compu {0=Cx0_Init (CM_RGB_Slave_01_LedBlauOl_Cx0_Init), 1=Cx1_nicht_erlaubt (CM_RGB_Slave_01_LedBlauOl_Cx1_nicht_erlaubt), 2=Cx2_kein_Fehler (CM_RGB_Slave_01_LedBlauOl_Cx2_kein_Fehler), 3=Cx3_Fehler (CM_RGB_Slave_01_LedBlauOl_Cx3_Fehler)}, range raw 0..3, transfer-property=PENDING, to SAM(timeout 3.5 s)  # OpenLoad für Blaue LED
            signal RGB_Slave_01_TempState_XIX_RGBs_Slave_01_XIX_E3V_SAM_LIN5: start 20, 3 bit, little-endian, data-type-policy=OVERRIDE, i-signal-type=PRIMITIVE, base-type=BT_RGB_Slave_01_TempState, compu {0=Cx0_keine_Temperaturregelung (CM_RGB_Slave_01_TempState_Cx0_keine_Temperaturregelung), 1=Cx1_Regelstufe_1 (CM_RGB_Slave_01_TempState_Cx1_Regelstufe_1), 2=Cx2_Regelstufe_2 (CM_RGB_Slave_01_TempState_Cx2_Regelstufe_2), 3=Cx3_Regelstufe_3 (CM_RGB_Slave_01_TempState_Cx3_Regelstufe_3), 4=Cx4_Regelstufe_4 (CM_RGB_Slave_01_TempState_Cx4_Regelstufe_4), 5=Cx5_Regelstufe_5 (CM_RGB_Slave_01_TempState_Cx5_Regelstufe_5), 6=Cx6_Regelstufe_6 (CM_RGB_Slave_01_TempState_Cx6_Regelstufe_6), 7=Cx7_Regelstufe_7 (CM_RGB_Slave_01_TempState_Cx7_Regelstufe_7)}, range raw 0..7, transfer-property=PENDING, to SAM(timeout 3.5 s)  # Status Temperaturregelung
            signal RGB_Slave_01_IntErrorRam_XIX_RGBs_Slave_01_XIX_E3V_SAM_LIN5: start 24, 2 bit, little-endian, data-type-policy=OVERRIDE, i-signal-type=PRIMITIVE, init-value=0, base-type=BT_RGB_Slave_01_IntErrorRam, invalid-value=Invalid_RGB_Slave_01_IntErrorRam_XIX_RGBs_Slave_01_XIX_E3V_SAM_LIN5:3, compu {0=Cx0_Init (CM_RGB_Slave_01_IntErrorRam_Cx0_Init), 1=Cx1_nicht_erlaubt (CM_RGB_Slave_01_IntErrorRam_Cx1_nicht_erlaubt), 2=Cx2_kein_Fehler (CM_RGB_Slave_01_IntErrorRam_Cx2_kein_Fehler), 3=Cx3_Fehler (CM_RGB_Slave_01_IntErrorRam_Cx3_Fehler)}, range raw 0..3, transfer-property=PENDING, to SAM(timeout 3.5 s)  # Fehler im RAM
            signal RGB_Slave_01_IntErrorRom_XIX_RGBs_Slave_01_XIX_E3V_SAM_LIN5: start 26, 2 bit, little-endian, data-type-policy=OVERRIDE, i-signal-type=PRIMITIVE, init-value=0, base-type=BT_RGB_Slave_01_IntErrorRom, invalid-value=Invalid_RGB_Slave_01_IntErrorRom_XIX_RGBs_Slave_01_XIX_E3V_SAM_LIN5:3, compu {0=Cx0_Init (CM_RGB_Slave_01_IntErrorRom_Cx0_Init), 1=Cx1_nicht_erlaubt (CM_RGB_Slave_01_IntErrorRom_Cx1_nicht_erlaubt), 2=Cx2_kein_Fehler (CM_RGB_Slave_01_IntErrorRom_Cx2_kein_Fehler), 3=Cx3_Fehler (CM_RGB_Slave_01_IntErrorRom_Cx3_Fehler)}, range raw 0..3, transfer-property=PENDING, to SAM(timeout 3.5 s)  # Fehler im ROM
            signal RGB_Slave_01_IntErrorNvm_XIX_RGBs_Slave_01_XIX_E3V_SAM_LIN5: start 28, 2 bit, little-endian, data-type-policy=OVERRIDE, i-signal-type=PRIMITIVE, init-value=0, base-type=BT_RGB_Slave_01_IntErrorNvm, invalid-value=Invalid_RGB_Slave_01_IntErrorNvm_XIX_RGBs_Slave_01_XIX_E3V_SAM_LIN5:3, compu {0=Cx0_Init (CM_RGB_Slave_01_IntErrorNvm_Cx0_Init), 1=Cx1_nicht_erlaubt (CM_RGB_Slave_01_IntErrorNvm_Cx1_nicht_erlaubt), 2=Cx2_kein_Fehler (CM_RGB_Slave_01_IntErrorNvm_Cx2_kein_Fehler), 3=Cx3_Fehler (CM_RGB_Slave_01_IntErrorNvm_Cx3_Fehler)}, range raw 0..3, transfer-property=PENDING, to SAM(timeout 3.5 s)  # Fehler im NVM
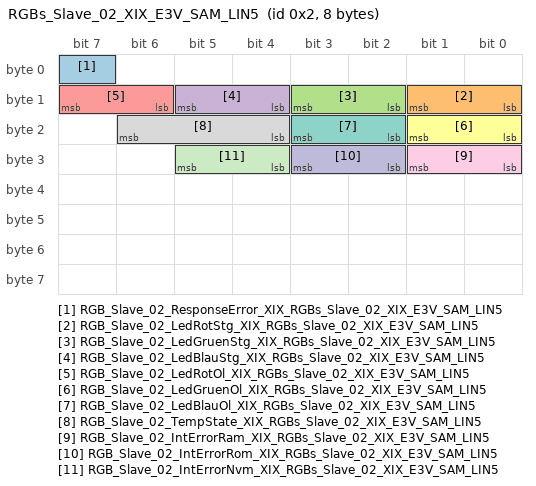
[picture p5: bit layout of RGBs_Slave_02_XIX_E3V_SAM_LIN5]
        frame RGBs_Slave_02_XIX_E3V_SAM_LIN5: id 0x2, to SAM, frame-length=8, lin-checksum=ENHANCED
          pdu RGBs_Slave_02_XIX_E3V_SAM_LIN5: length=8, unused-bit-pattern=0
            signal RGB_Slave_02_ResponseError_XIX_RGBs_Slave_02_XIX_E3V_SAM_LIN5: start 7, 1 bit, little-endian, data-type-policy=OVERRIDE, i-signal-type=PRIMITIVE, init-value=0, base-type=BT_RGB_Slave_02_ResponseError, invalid-value=Invalid_RGB_Slave_02_ResponseError_XIX_RGBs_Slave_02_XIX_E3V_SAM_LIN5:1, compu {0=Cx0_normal (CM_RGB_Slave_02_ResponseError_Cx0_normal), 1=Cx1_Fehler (CM_RGB_Slave_02_ResponseError_Cx1_Fehler)}, range raw 0..1, transfer-property=PENDING, to SAM(timeout 3.5 s)  # siehe LIN2.0-Specification (Darf nicht über ein Fehlergueltigkeitsbit abgesichtert werden!)
            signal RGB_Slave_02_LedRotStg_XIX_RGBs_Slave_02_XIX_E3V_SAM_LIN5: start 8, 2 bit, little-endian, data-type-policy=OVERRIDE, i-signal-type=PRIMITIVE, init-value=0, base-type=BT_RGB_Slave_02_LedRotStg, invalid-value=Invalid_RGB_Slave_02_LedRotStg_XIX_RGBs_Slave_02_XIX_E3V_SAM_LIN5:3, compu {0=Cx0_Init (CM_RGB_Slave_02_LedRotStg_Cx0_Init), 1=Cx1_nicht_erlaubt (CM_RGB_Slave_02_LedRotStg_Cx1_nicht_erlaubt), 2=Cx2_kein_Fehler (CM_RGB_Slave_02_LedRotStg_Cx2_kein_Fehler), 3=Cx3_Fehler (CM_RGB_Slave_02_LedRotStg_Cx3_Fehler)}, range raw 0..3, transfer-property=PENDING, to SAM(timeout 3.5 s)  # Short To Ground für Rote LED
            signal RGB_Slave_02_LedGruenStg_XIX_RGBs_Slave_02_XIX_E3V_SAM_LIN5: start 10, 2 bit, little-endian, data-type-policy=OVERRIDE, i-signal-type=PRIMITIVE, init-value=0, base-type=BT_RGB_Slave_02_LedGruenStg, invalid-value=Invalid_RGB_Slave_02_LedGruenStg_XIX_RGBs_Slave_02_XIX_E3V_SAM_LIN5:3, compu {0=Cx0_Init (CM_RGB_Slave_02_LedGruenStg_Cx0_Init), 1=Cx1_nicht_erlaubt (CM_RGB_Slave_02_LedGruenStg_Cx1_nicht_erlaubt), 2=Cx2_kein_Fehler (CM_RGB_Slave_02_LedGruenStg_Cx2_kein_Fehler), 3=Cx3_Fehler (CM_RGB_Slave_02_LedGruenStg_Cx3_Fehler)}, range raw 0..3, transfer-property=PENDING, to SAM(timeout 3.5 s)  # Short To Ground für Grüne LED
            signal RGB_Slave_02_LedBlauStg_XIX_RGBs_Slave_02_XIX_E3V_SAM_LIN5: start 12, 2 bit, little-endian, data-type-policy=OVERRIDE, i-signal-type=PRIMITIVE, init-value=0, base-type=BT_RGB_Slave_02_LedBlauStg, invalid-value=Invalid_RGB_Slave_02_LedBlauStg_XIX_RGBs_Slave_02_XIX_E3V_SAM_LIN5:3, compu {0=Cx0_Init (CM_RGB_Slave_02_LedBlauStg_Cx0_Init), 1=Cx1_nicht_erlaubt (CM_RGB_Slave_02_LedBlauStg_Cx1_nicht_erlaubt), 2=Cx2_kein_Fehler (CM_RGB_Slave_02_LedBlauStg_Cx2_kein_Fehler), 3=Cx3_Fehler (CM_RGB_Slave_02_LedBlauStg_Cx3_Fehler)}, range raw 0..3, transfer-property=PENDING, to SAM(timeout 3.5 s)  # Short To Ground für Blaue LED
            signal RGB_Slave_02_LedRotOl_XIX_RGBs_Slave_02_XIX_E3V_SAM_LIN5: start 14, 2 bit, little-endian, data-type-policy=OVERRIDE, i-signal-type=PRIMITIVE, init-value=0, base-type=BT_RGB_Slave_02_LedRotOl, invalid-value=Invalid_RGB_Slave_02_LedRotOl_XIX_RGBs_Slave_02_XIX_E3V_SAM_LIN5:3, compu {0=Cx0_Init (CM_RGB_Slave_02_LedRotOl_Cx0_Init), 1=Cx1_nicht_erlaubt (CM_RGB_Slave_02_LedRotOl_Cx1_nicht_erlaubt), 2=Cx2_kein_Fehler (CM_RGB_Slave_02_LedRotOl_Cx2_kein_Fehler), 3=Cx3_Fehler (CM_RGB_Slave_02_LedRotOl_Cx3_Fehler)}, range raw 0..3, transfer-property=PENDING, to SAM(timeout 3.5 s)  # OpenLoad für Rote LED
            signal RGB_Slave_02_LedGruenOl_XIX_RGBs_Slave_02_XIX_E3V_SAM_LIN5: start 16, 2 bit, little-endian, data-type-policy=OVERRIDE, i-signal-type=PRIMITIVE, init-value=0, base-type=BT_RGB_Slave_02_LedGruenOl, invalid-value=Invalid_RGB_Slave_02_LedGruenOl_XIX_RGBs_Slave_02_XIX_E3V_SAM_LIN5:3, compu {0=Cx0_Init (CM_RGB_Slave_02_LedGruenOl_Cx0_Init), 1=Cx1_nicht_erlaubt (CM_RGB_Slave_02_LedGruenOl_Cx1_nicht_erlaubt), 2=Cx2_kein_Fehler (CM_RGB_Slave_02_LedGruenOl_Cx2_kein_Fehler), 3=Cx3_Fehler (CM_RGB_Slave_02_LedGruenOl_Cx3_Fehler)}, range raw 0..3, transfer-property=PENDING, to SAM(timeout 3.5 s)  # OpenLoad für Rote LED
            signal RGB_Slave_02_LedBlauOl_XIX_RGBs_Slave_02_XIX_E3V_SAM_LIN5: start 18, 2 bit, little-endian, data-type-policy=OVERRIDE, i-signal-type=PRIMITIVE, init-value=0, base-type=BT_RGB_Slave_02_LedBlauOl, invalid-value=Invalid_RGB_Slave_02_LedBlauOl_XIX_RGBs_Slave_02_XIX_E3V_SAM_LIN5:3, compu {0=Cx0_Init (CM_RGB_Slave_02_LedBlauOl_Cx0_Init), 1=Cx1_nicht_erlaubt (CM_RGB_Slave_02_LedBlauOl_Cx1_nicht_erlaubt), 2=Cx2_kein_Fehler (CM_RGB_Slave_02_LedBlauOl_Cx2_kein_Fehler), 3=Cx3_Fehler (CM_RGB_Slave_02_LedBlauOl_Cx3_Fehler)}, range raw 0..3, transfer-property=PENDING, to SAM(timeout 3.5 s)  # OpenLoad für Blaue LED
            signal RGB_Slave_02_TempState_XIX_RGBs_Slave_02_XIX_E3V_SAM_LIN5: start 20, 3 bit, little-endian, data-type-policy=OVERRIDE, i-signal-type=PRIMITIVE, base-type=BT_RGB_Slave_02_TempState, compu {0=Cx0_keine_Temperaturregelung (CM_RGB_Slave_02_TempState_Cx0_keine_Temperaturregelung), 1=Cx1_Regelstufe_1 (CM_RGB_Slave_02_TempState_Cx1_Regelstufe_1), 2=Cx2_Regelstufe_2 (CM_RGB_Slave_02_TempState_Cx2_Regelstufe_2), 3=Cx3_Regelstufe_3 (CM_RGB_Slave_02_TempState_Cx3_Regelstufe_3), 4=Cx4_Regelstufe_4 (CM_RGB_Slave_02_TempState_Cx4_Regelstufe_4), 5=Cx5_Regelstufe_5 (CM_RGB_Slave_02_TempState_Cx5_Regelstufe_5), 6=Cx6_Regelstufe_6 (CM_RGB_Slave_02_TempState_Cx6_Regelstufe_6), 7=Cx7_Regelstufe_7 (CM_RGB_Slave_02_TempState_Cx7_Regelstufe_7)}, range raw 0..7, transfer-property=PENDING, to SAM(timeout 3.5 s)  # Status Temperaturregelung
            signal RGB_Slave_02_IntErrorRam_XIX_RGBs_Slave_02_XIX_E3V_SAM_LIN5: start 24, 2 bit, little-endian, data-type-policy=OVERRIDE, i-signal-type=PRIMITIVE, init-value=0, base-type=BT_RGB_Slave_02_IntErrorRam, invalid-value=Invalid_RGB_Slave_02_IntErrorRam_XIX_RGBs_Slave_02_XIX_E3V_SAM_LIN5:3, compu {0=Cx0_Init (CM_RGB_Slave_02_IntErrorRam_Cx0_Init), 1=Cx1_nicht_erlaubt (CM_RGB_Slave_02_IntErrorRam_Cx1_nicht_erlaubt), 2=Cx2_kein_Fehler (CM_RGB_Slave_02_IntErrorRam_Cx2_kein_Fehler), 3=Cx3_Fehler (CM_RGB_Slave_02_IntErrorRam_Cx3_Fehler)}, range raw 0..3, transfer-property=PENDING, to SAM(timeout 3.5 s)  # Fehler im RAM
            signal RGB_Slave_02_IntErrorRom_XIX_RGBs_Slave_02_XIX_E3V_SAM_LIN5: start 26, 2 bit, little-endian, data-type-policy=OVERRIDE, i-signal-type=PRIMITIVE, init-value=0, base-type=BT_RGB_Slave_02_IntErrorRom, invalid-value=Invalid_RGB_Slave_02_IntErrorRom_XIX_RGBs_Slave_02_XIX_E3V_SAM_LIN5:3, compu {0=Cx0_Init (CM_RGB_Slave_02_IntErrorRom_Cx0_Init), 1=Cx1_nicht_erlaubt (CM_RGB_Slave_02_IntErrorRom_Cx1_nicht_erlaubt), 2=Cx2_kein_Fehler (CM_RGB_Slave_02_IntErrorRom_Cx2_kein_Fehler), 3=Cx3_Fehler (CM_RGB_Slave_02_IntErrorRom_Cx3_Fehler)}, range raw 0..3, transfer-property=PENDING, to SAM(timeout 3.5 s)  # Fehler im ROM
            signal RGB_Slave_02_IntErrorNvm_XIX_RGBs_Slave_02_XIX_E3V_SAM_LIN5: start 28, 2 bit, little-endian, data-type-policy=OVERRIDE, i-signal-type=PRIMITIVE, init-value=0, base-type=BT_RGB_Slave_02_IntErrorNvm, invalid-value=Invalid_RGB_Slave_02_IntErrorNvm_XIX_RGBs_Slave_02_XIX_E3V_SAM_LIN5:3, compu {0=Cx0_Init (CM_RGB_Slave_02_IntErrorNvm_Cx0_Init), 1=Cx1_nicht_erlaubt (CM_RGB_Slave_02_IntErrorNvm_Cx1_nicht_erlaubt), 2=Cx2_kein_Fehler (CM_RGB_Slave_02_IntErrorNvm_Cx2_kein_Fehler), 3=Cx3_Fehler (CM_RGB_Slave_02_IntErrorNvm_Cx3_Fehler)}, range raw 0..3, transfer-property=PENDING, to SAM(timeout 3.5 s)  # Fehler im NVM
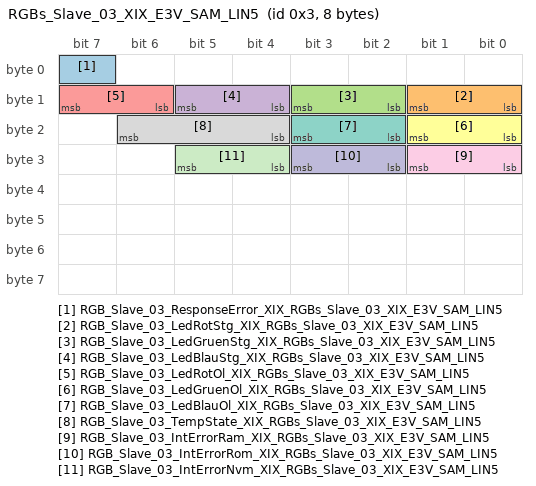
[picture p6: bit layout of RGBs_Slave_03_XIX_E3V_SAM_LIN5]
        frame RGBs_Slave_03_XIX_E3V_SAM_LIN5: id 0x3, to SAM, frame-length=8, lin-checksum=ENHANCED
          pdu RGBs_Slave_03_XIX_E3V_SAM_LIN5: length=8, unused-bit-pattern=0
            signal RGB_Slave_03_ResponseError_XIX_RGBs_Slave_03_XIX_E3V_SAM_LIN5: start 7, 1 bit, little-endian, data-type-policy=OVERRIDE, i-signal-type=PRIMITIVE, init-value=0, base-type=BT_RGB_Slave_03_ResponseError, invalid-value=Invalid_RGB_Slave_03_ResponseError_XIX_RGBs_Slave_03_XIX_E3V_SAM_LIN5:1, compu {0=Cx0_normal (CM_RGB_Slave_03_ResponseError_Cx0_normal), 1=Cx1_Fehler (CM_RGB_Slave_03_ResponseError_Cx1_Fehler)}, range raw 0..1, transfer-property=PENDING, to SAM(timeout 3.5 s)  # siehe LIN2.0-Specification (Darf nicht über ein Fehlergueltigkeitsbit abgesichtert werden!)
            signal RGB_Slave_03_LedRotStg_XIX_RGBs_Slave_03_XIX_E3V_SAM_LIN5: start 8, 2 bit, little-endian, data-type-policy=OVERRIDE, i-signal-type=PRIMITIVE, init-value=0, base-type=BT_RGB_Slave_03_LedRotStg, invalid-value=Invalid_RGB_Slave_03_LedRotStg_XIX_RGBs_Slave_03_XIX_E3V_SAM_LIN5:3, compu {0=Cx0_Init (CM_RGB_Slave_03_LedRotStg_Cx0_Init), 1=Cx1_nicht_erlaubt (CM_RGB_Slave_03_LedRotStg_Cx1_nicht_erlaubt), 2=Cx2_kein_Fehler (CM_RGB_Slave_03_LedRotStg_Cx2_kein_Fehler), 3=Cx3_Fehler (CM_RGB_Slave_03_LedRotStg_Cx3_Fehler)}, range raw 0..3, transfer-property=PENDING, to SAM(timeout 3.5 s)  # Short To Ground für Rote LED
            signal RGB_Slave_03_LedGruenStg_XIX_RGBs_Slave_03_XIX_E3V_SAM_LIN5: start 10, 2 bit, little-endian, data-type-policy=OVERRIDE, i-signal-type=PRIMITIVE, init-value=0, base-type=BT_RGB_Slave_03_LedGruenStg, invalid-value=Invalid_RGB_Slave_03_LedGruenStg_XIX_RGBs_Slave_03_XIX_E3V_SAM_LIN5:3, compu {0=Cx0_Init (CM_RGB_Slave_03_LedGruenStg_Cx0_Init), 1=Cx1_nicht_erlaubt (CM_RGB_Slave_03_LedGruenStg_Cx1_nicht_erlaubt), 2=Cx2_kein_Fehler (CM_RGB_Slave_03_LedGruenStg_Cx2_kein_Fehler), 3=Cx3_Fehler (CM_RGB_Slave_03_LedGruenStg_Cx3_Fehler)}, range raw 0..3, transfer-property=PENDING, to SAM(timeout 3.5 s)  # Short To Ground für Grüne LED
            signal RGB_Slave_03_LedBlauStg_XIX_RGBs_Slave_03_XIX_E3V_SAM_LIN5: start 12, 2 bit, little-endian, data-type-policy=OVERRIDE, i-signal-type=PRIMITIVE, init-value=0, base-type=BT_RGB_Slave_03_LedBlauStg, invalid-value=Invalid_RGB_Slave_03_LedBlauStg_XIX_RGBs_Slave_03_XIX_E3V_SAM_LIN5:3, compu {0=Cx0_Init (CM_RGB_Slave_03_LedBlauStg_Cx0_Init), 1=Cx1_nicht_erlaubt (CM_RGB_Slave_03_LedBlauStg_Cx1_nicht_erlaubt), 2=Cx2_kein_Fehler (CM_RGB_Slave_03_LedBlauStg_Cx2_kein_Fehler), 3=Cx3_Fehler (CM_RGB_Slave_03_LedBlauStg_Cx3_Fehler)}, range raw 0..3, transfer-property=PENDING, to SAM(timeout 3.5 s)  # Short To Ground für Blaue LED
            signal RGB_Slave_03_LedRotOl_XIX_RGBs_Slave_03_XIX_E3V_SAM_LIN5: start 14, 2 bit, little-endian, data-type-policy=OVERRIDE, i-signal-type=PRIMITIVE, init-value=0, base-type=BT_RGB_Slave_03_LedRotOl, invalid-value=Invalid_RGB_Slave_03_LedRotOl_XIX_RGBs_Slave_03_XIX_E3V_SAM_LIN5:3, compu {0=Cx0_Init (CM_RGB_Slave_03_LedRotOl_Cx0_Init), 1=Cx1_nicht_erlaubt (CM_RGB_Slave_03_LedRotOl_Cx1_nicht_erlaubt), 2=Cx2_kein_Fehler (CM_RGB_Slave_03_LedRotOl_Cx2_kein_Fehler), 3=Cx3_Fehler (CM_RGB_Slave_03_LedRotOl_Cx3_Fehler)}, range raw 0..3, transfer-property=PENDING, to SAM(timeout 3.5 s)  # OpenLoad für Rote LED
            signal RGB_Slave_03_LedGruenOl_XIX_RGBs_Slave_03_XIX_E3V_SAM_LIN5: start 16, 2 bit, little-endian, data-type-policy=OVERRIDE, i-signal-type=PRIMITIVE, init-value=0, base-type=BT_RGB_Slave_03_LedGruenOl, invalid-value=Invalid_RGB_Slave_03_LedGruenOl_XIX_RGBs_Slave_03_XIX_E3V_SAM_LIN5:3, compu {0=Cx0_Init (CM_RGB_Slave_03_LedGruenOl_Cx0_Init), 1=Cx1_nicht_erlaubt (CM_RGB_Slave_03_LedGruenOl_Cx1_nicht_erlaubt), 2=Cx2_kein_Fehler (CM_RGB_Slave_03_LedGruenOl_Cx2_kein_Fehler), 3=Cx3_Fehler (CM_RGB_Slave_03_LedGruenOl_Cx3_Fehler)}, range raw 0..3, transfer-property=PENDING, to SAM(timeout 3.5 s)  # OpenLoad für Rote LED
            signal RGB_Slave_03_LedBlauOl_XIX_RGBs_Slave_03_XIX_E3V_SAM_LIN5: start 18, 2 bit, little-endian, data-type-policy=OVERRIDE, i-signal-type=PRIMITIVE, init-value=0, base-type=BT_RGB_Slave_03_LedBlauOl, invalid-value=Invalid_RGB_Slave_03_LedBlauOl_XIX_RGBs_Slave_03_XIX_E3V_SAM_LIN5:3, compu {0=Cx0_Init (CM_RGB_Slave_03_LedBlauOl_Cx0_Init), 1=Cx1_nicht_erlaubt (CM_RGB_Slave_03_LedBlauOl_Cx1_nicht_erlaubt), 2=Cx2_kein_Fehler (CM_RGB_Slave_03_LedBlauOl_Cx2_kein_Fehler), 3=Cx3_Fehler (CM_RGB_Slave_03_LedBlauOl_Cx3_Fehler)}, range raw 0..3, transfer-property=PENDING, to SAM(timeout 3.5 s)  # OpenLoad für Blaue LED
            signal RGB_Slave_03_TempState_XIX_RGBs_Slave_03_XIX_E3V_SAM_LIN5: start 20, 3 bit, little-endian, data-type-policy=OVERRIDE, i-signal-type=PRIMITIVE, base-type=BT_RGB_Slave_03_TempState, compu {0=Cx0_keine_Temperaturregelung (CM_RGB_Slave_03_TempState_Cx0_keine_Temperaturregelung), 1=Cx1_Regelstufe_1 (CM_RGB_Slave_03_TempState_Cx1_Regelstufe_1), 2=Cx2_Regelstufe_2 (CM_RGB_Slave_03_TempState_Cx2_Regelstufe_2), 3=Cx3_Regelstufe_3 (CM_RGB_Slave_03_TempState_Cx3_Regelstufe_3), 4=Cx4_Regelstufe_4 (CM_RGB_Slave_03_TempState_Cx4_Regelstufe_4), 5=Cx5_Regelstufe_5 (CM_RGB_Slave_03_TempState_Cx5_Regelstufe_5), 6=Cx6_Regelstufe_6 (CM_RGB_Slave_03_TempState_Cx6_Regelstufe_6), 7=Cx7_Regelstufe_7 (CM_RGB_Slave_03_TempState_Cx7_Regelstufe_7)}, range raw 0..7, transfer-property=PENDING, to SAM(timeout 3.5 s)  # Status Temperaturregelung
            signal RGB_Slave_03_IntErrorRam_XIX_RGBs_Slave_03_XIX_E3V_SAM_LIN5: start 24, 2 bit, little-endian, data-type-policy=OVERRIDE, i-signal-type=PRIMITIVE, init-value=0, base-type=BT_RGB_Slave_03_IntErrorRam, invalid-value=Invalid_RGB_Slave_03_IntErrorRam_XIX_RGBs_Slave_03_XIX_E3V_SAM_LIN5:3, compu {0=Cx0_Init (CM_RGB_Slave_03_IntErrorRam_Cx0_Init), 1=Cx1_nicht_erlaubt (CM_RGB_Slave_03_IntErrorRam_Cx1_nicht_erlaubt), 2=Cx2_kein_Fehler (CM_RGB_Slave_03_IntErrorRam_Cx2_kein_Fehler), 3=Cx3_Fehler (CM_RGB_Slave_03_IntErrorRam_Cx3_Fehler)}, range raw 0..3, transfer-property=PENDING, to SAM(timeout 3.5 s)  # Fehler im RAM
            signal RGB_Slave_03_IntErrorRom_XIX_RGBs_Slave_03_XIX_E3V_SAM_LIN5: start 26, 2 bit, little-endian, data-type-policy=OVERRIDE, i-signal-type=PRIMITIVE, init-value=0, base-type=BT_RGB_Slave_03_IntErrorRom, invalid-value=Invalid_RGB_Slave_03_IntErrorRom_XIX_RGBs_Slave_03_XIX_E3V_SAM_LIN5:3, compu {0=Cx0_Init (CM_RGB_Slave_03_IntErrorRom_Cx0_Init), 1=Cx1_nicht_erlaubt (CM_RGB_Slave_03_IntErrorRom_Cx1_nicht_erlaubt), 2=Cx2_kein_Fehler (CM_RGB_Slave_03_IntErrorRom_Cx2_kein_Fehler), 3=Cx3_Fehler (CM_RGB_Slave_03_IntErrorRom_Cx3_Fehler)}, range raw 0..3, transfer-property=PENDING, to SAM(timeout 3.5 s)  # Fehler im ROM
            signal RGB_Slave_03_IntErrorNvm_XIX_RGBs_Slave_03_XIX_E3V_SAM_LIN5: start 28, 2 bit, little-endian, data-type-policy=OVERRIDE, i-signal-type=PRIMITIVE, init-value=0, base-type=BT_RGB_Slave_03_IntErrorNvm, invalid-value=Invalid_RGB_Slave_03_IntErrorNvm_XIX_RGBs_Slave_03_XIX_E3V_SAM_LIN5:3, compu {0=Cx0_Init (CM_RGB_Slave_03_IntErrorNvm_Cx0_Init), 1=Cx1_nicht_erlaubt (CM_RGB_Slave_03_IntErrorNvm_Cx1_nicht_erlaubt), 2=Cx2_kein_Fehler (CM_RGB_Slave_03_IntErrorNvm_Cx2_kein_Fehler), 3=Cx3_Fehler (CM_RGB_Slave_03_IntErrorNvm_Cx3_Fehler)}, range raw 0..3, transfer-property=PENDING, to SAM(timeout 3.5 s)  # Fehler im NVM
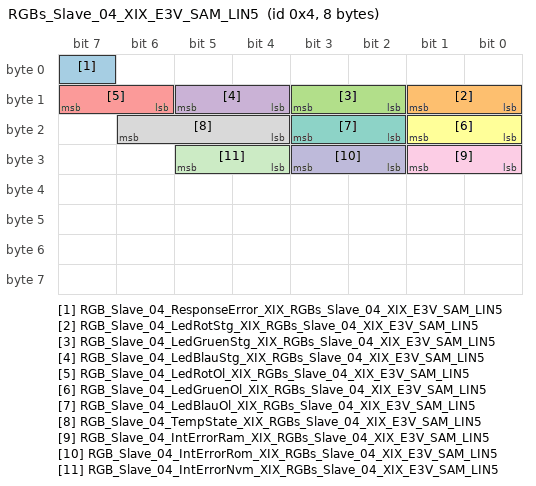
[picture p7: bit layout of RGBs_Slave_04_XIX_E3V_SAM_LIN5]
        frame RGBs_Slave_04_XIX_E3V_SAM_LIN5: id 0x4, to SAM, frame-length=8, lin-checksum=ENHANCED
          pdu RGBs_Slave_04_XIX_E3V_SAM_LIN5: length=8, unused-bit-pattern=0
            signal RGB_Slave_04_ResponseError_XIX_RGBs_Slave_04_XIX_E3V_SAM_LIN5: start 7, 1 bit, little-endian, data-type-policy=OVERRIDE, i-signal-type=PRIMITIVE, init-value=0, base-type=BT_RGB_Slave_04_ResponseError, invalid-value=Invalid_RGB_Slave_04_ResponseError_XIX_RGBs_Slave_04_XIX_E3V_SAM_LIN5:1, compu {0=Cx0_normal (CM_RGB_Slave_04_ResponseError_Cx0_normal), 1=Cx1_Fehler (CM_RGB_Slave_04_ResponseError_Cx1_Fehler)}, range raw 0..1, transfer-property=PENDING, to SAM(timeout 3.5 s)  # siehe LIN2.0-Specification (Darf nicht über ein Fehlergueltigkeitsbit abgesichtert werden!)
            signal RGB_Slave_04_LedRotStg_XIX_RGBs_Slave_04_XIX_E3V_SAM_LIN5: start 8, 2 bit, little-endian, data-type-policy=OVERRIDE, i-signal-type=PRIMITIVE, init-value=0, base-type=BT_RGB_Slave_04_LedRotStg, invalid-value=Invalid_RGB_Slave_04_LedRotStg_XIX_RGBs_Slave_04_XIX_E3V_SAM_LIN5:3, compu {0=Cx0_Init (CM_RGB_Slave_04_LedRotStg_Cx0_Init), 1=Cx1_nicht_erlaubt (CM_RGB_Slave_04_LedRotStg_Cx1_nicht_erlaubt), 2=Cx2_kein_Fehler (CM_RGB_Slave_04_LedRotStg_Cx2_kein_Fehler), 3=Cx3_Fehler (CM_RGB_Slave_04_LedRotStg_Cx3_Fehler)}, range raw 0..3, transfer-property=PENDING, to SAM(timeout 3.5 s)  # Short To Ground für Rote LED
            signal RGB_Slave_04_LedGruenStg_XIX_RGBs_Slave_04_XIX_E3V_SAM_LIN5: start 10, 2 bit, little-endian, data-type-policy=OVERRIDE, i-signal-type=PRIMITIVE, init-value=0, base-type=BT_RGB_Slave_04_LedGruenStg, invalid-value=Invalid_RGB_Slave_04_LedGruenStg_XIX_RGBs_Slave_04_XIX_E3V_SAM_LIN5:3, compu {0=Cx0_Init (CM_RGB_Slave_04_LedGruenStg_Cx0_Init), 1=Cx1_nicht_erlaubt (CM_RGB_Slave_04_LedGruenStg_Cx1_nicht_erlaubt), 2=Cx2_kein_Fehler (CM_RGB_Slave_04_LedGruenStg_Cx2_kein_Fehler), 3=Cx3_Fehler (CM_RGB_Slave_04_LedGruenStg_Cx3_Fehler)}, range raw 0..3, transfer-property=PENDING, to SAM(timeout 3.5 s)  # Short To Ground für Grüne LED
            signal RGB_Slave_04_LedBlauStg_XIX_RGBs_Slave_04_XIX_E3V_SAM_LIN5: start 12, 2 bit, little-endian, data-type-policy=OVERRIDE, i-signal-type=PRIMITIVE, init-value=0, base-type=BT_RGB_Slave_04_LedBlauStg, invalid-value=Invalid_RGB_Slave_04_LedBlauStg_XIX_RGBs_Slave_04_XIX_E3V_SAM_LIN5:3, compu {0=Cx0_Init (CM_RGB_Slave_04_LedBlauStg_Cx0_Init), 1=Cx1_nicht_erlaubt (CM_RGB_Slave_04_LedBlauStg_Cx1_nicht_erlaubt), 2=Cx2_kein_Fehler (CM_RGB_Slave_04_LedBlauStg_Cx2_kein_Fehler), 3=Cx3_Fehler (CM_RGB_Slave_04_LedBlauStg_Cx3_Fehler)}, range raw 0..3, transfer-property=PENDING, to SAM(timeout 3.5 s)  # Short To Ground für Blaue LED
            signal RGB_Slave_04_LedRotOl_XIX_RGBs_Slave_04_XIX_E3V_SAM_LIN5: start 14, 2 bit, little-endian, data-type-policy=OVERRIDE, i-signal-type=PRIMITIVE, init-value=0, base-type=BT_RGB_Slave_04_LedRotOl, invalid-value=Invalid_RGB_Slave_04_LedRotOl_XIX_RGBs_Slave_04_XIX_E3V_SAM_LIN5:3, compu {0=Cx0_Init (CM_RGB_Slave_04_LedRotOl_Cx0_Init), 1=Cx1_nicht_erlaubt (CM_RGB_Slave_04_LedRotOl_Cx1_nicht_erlaubt), 2=Cx2_kein_Fehler (CM_RGB_Slave_04_LedRotOl_Cx2_kein_Fehler), 3=Cx3_Fehler (CM_RGB_Slave_04_LedRotOl_Cx3_Fehler)}, range raw 0..3, transfer-property=PENDING, to SAM(timeout 3.5 s)  # OpenLoad für Rote LED
            signal RGB_Slave_04_LedGruenOl_XIX_RGBs_Slave_04_XIX_E3V_SAM_LIN5: start 16, 2 bit, little-endian, data-type-policy=OVERRIDE, i-signal-type=PRIMITIVE, init-value=0, base-type=BT_RGB_Slave_04_LedGruenOl, invalid-value=Invalid_RGB_Slave_04_LedGruenOl_XIX_RGBs_Slave_04_XIX_E3V_SAM_LIN5:3, compu {0=Cx0_Init (CM_RGB_Slave_04_LedGruenOl_Cx0_Init), 1=Cx1_nicht_erlaubt (CM_RGB_Slave_04_LedGruenOl_Cx1_nicht_erlaubt), 2=Cx2_kein_Fehler (CM_RGB_Slave_04_LedGruenOl_Cx2_kein_Fehler), 3=Cx3_Fehler (CM_RGB_Slave_04_LedGruenOl_Cx3_Fehler)}, range raw 0..3, transfer-property=PENDING, to SAM(timeout 3.5 s)  # OpenLoad für Rote LED
            signal RGB_Slave_04_LedBlauOl_XIX_RGBs_Slave_04_XIX_E3V_SAM_LIN5: start 18, 2 bit, little-endian, data-type-policy=OVERRIDE, i-signal-type=PRIMITIVE, init-value=0, base-type=BT_RGB_Slave_04_LedBlauOl, invalid-value=Invalid_RGB_Slave_04_LedBlauOl_XIX_RGBs_Slave_04_XIX_E3V_SAM_LIN5:3, compu {0=Cx0_Init (CM_RGB_Slave_04_LedBlauOl_Cx0_Init), 1=Cx1_nicht_erlaubt (CM_RGB_Slave_04_LedBlauOl_Cx1_nicht_erlaubt), 2=Cx2_kein_Fehler (CM_RGB_Slave_04_LedBlauOl_Cx2_kein_Fehler), 3=Cx3_Fehler (CM_RGB_Slave_04_LedBlauOl_Cx3_Fehler)}, range raw 0..3, transfer-property=PENDING, to SAM(timeout 3.5 s)  # OpenLoad für Blaue LED
            signal RGB_Slave_04_TempState_XIX_RGBs_Slave_04_XIX_E3V_SAM_LIN5: start 20, 3 bit, little-endian, data-type-policy=OVERRIDE, i-signal-type=PRIMITIVE, base-type=BT_RGB_Slave_04_TempState, compu {0=Cx0_keine_Temperaturregelung (CM_RGB_Slave_04_TempState_Cx0_keine_Temperaturregelung), 1=Cx1_Regelstufe_1 (CM_RGB_Slave_04_TempState_Cx1_Regelstufe_1), 2=Cx2_Regelstufe_2 (CM_RGB_Slave_04_TempState_Cx2_Regelstufe_2), 3=Cx3_Regelstufe_3 (CM_RGB_Slave_04_TempState_Cx3_Regelstufe_3), 4=Cx4_Regelstufe_4 (CM_RGB_Slave_04_TempState_Cx4_Regelstufe_4), 5=Cx5_Regelstufe_5 (CM_RGB_Slave_04_TempState_Cx5_Regelstufe_5), 6=Cx6_Regelstufe_6 (CM_RGB_Slave_04_TempState_Cx6_Regelstufe_6), 7=Cx7_Regelstufe_7 (CM_RGB_Slave_04_TempState_Cx7_Regelstufe_7)}, range raw 0..7, transfer-property=PENDING, to SAM(timeout 3.5 s)  # Status Temperaturregelung
            signal RGB_Slave_04_IntErrorRam_XIX_RGBs_Slave_04_XIX_E3V_SAM_LIN5: start 24, 2 bit, little-endian, data-type-policy=OVERRIDE, i-signal-type=PRIMITIVE, init-value=0, base-type=BT_RGB_Slave_04_IntErrorRam, invalid-value=Invalid_RGB_Slave_04_IntErrorRam_XIX_RGBs_Slave_04_XIX_E3V_SAM_LIN5:3, compu {0=Cx0_Init (CM_RGB_Slave_04_IntErrorRam_Cx0_Init), 1=Cx1_nicht_erlaubt (CM_RGB_Slave_04_IntErrorRam_Cx1_nicht_erlaubt), 2=Cx2_kein_Fehler (CM_RGB_Slave_04_IntErrorRam_Cx2_kein_Fehler), 3=Cx3_Fehler (CM_RGB_Slave_04_IntErrorRam_Cx3_Fehler)}, range raw 0..3, transfer-property=PENDING, to SAM(timeout 3.5 s)  # Fehler im RAM
            signal RGB_Slave_04_IntErrorRom_XIX_RGBs_Slave_04_XIX_E3V_SAM_LIN5: start 26, 2 bit, little-endian, data-type-policy=OVERRIDE, i-signal-type=PRIMITIVE, init-value=0, base-type=BT_RGB_Slave_04_IntErrorRom, invalid-value=Invalid_RGB_Slave_04_IntErrorRom_XIX_RGBs_Slave_04_XIX_E3V_SAM_LIN5:3, compu {0=Cx0_Init (CM_RGB_Slave_04_IntErrorRom_Cx0_Init), 1=Cx1_nicht_erlaubt (CM_RGB_Slave_04_IntErrorRom_Cx1_nicht_erlaubt), 2=Cx2_kein_Fehler (CM_RGB_Slave_04_IntErrorRom_Cx2_kein_Fehler), 3=Cx3_Fehler (CM_RGB_Slave_04_IntErrorRom_Cx3_Fehler)}, range raw 0..3, transfer-property=PENDING, to SAM(timeout 3.5 s)  # Fehler im ROM
            signal RGB_Slave_04_IntErrorNvm_XIX_RGBs_Slave_04_XIX_E3V_SAM_LIN5: start 28, 2 bit, little-endian, data-type-policy=OVERRIDE, i-signal-type=PRIMITIVE, init-value=0, base-type=BT_RGB_Slave_04_IntErrorNvm, invalid-value=Invalid_RGB_Slave_04_IntErrorNvm_XIX_RGBs_Slave_04_XIX_E3V_SAM_LIN5:3, compu {0=Cx0_Init (CM_RGB_Slave_04_IntErrorNvm_Cx0_Init), 1=Cx1_nicht_erlaubt (CM_RGB_Slave_04_IntErrorNvm_Cx1_nicht_erlaubt), 2=Cx2_kein_Fehler (CM_RGB_Slave_04_IntErrorNvm_Cx2_kein_Fehler), 3=Cx3_Fehler (CM_RGB_Slave_04_IntErrorNvm_Cx3_Fehler)}, range raw 0..3, transfer-property=PENDING, to SAM(timeout 3.5 s)  # Fehler im NVM
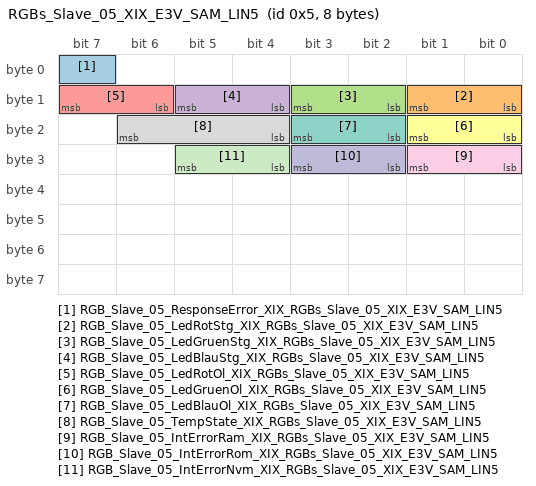
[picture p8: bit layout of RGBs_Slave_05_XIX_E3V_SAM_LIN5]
        frame RGBs_Slave_05_XIX_E3V_SAM_LIN5: id 0x5, to SAM, frame-length=8, lin-checksum=ENHANCED
          pdu RGBs_Slave_05_XIX_E3V_SAM_LIN5: length=8, unused-bit-pattern=0
            signal RGB_Slave_05_ResponseError_XIX_RGBs_Slave_05_XIX_E3V_SAM_LIN5: start 7, 1 bit, little-endian, data-type-policy=OVERRIDE, i-signal-type=PRIMITIVE, init-value=0, base-type=BT_RGB_Slave_05_ResponseError, invalid-value=Invalid_RGB_Slave_05_ResponseError_XIX_RGBs_Slave_05_XIX_E3V_SAM_LIN5:1, compu {0=Cx0_normal (CM_RGB_Slave_05_ResponseError_Cx0_normal), 1=Cx1_Fehler (CM_RGB_Slave_05_ResponseError_Cx1_Fehler)}, range raw 0..1, transfer-property=PENDING, to SAM(timeout 3.5 s)  # siehe LIN2.0-Specification (Darf nicht über ein Fehlergueltigkeitsbit abgesichtert werden!)
            signal RGB_Slave_05_LedRotStg_XIX_RGBs_Slave_05_XIX_E3V_SAM_LIN5: start 8, 2 bit, little-endian, data-type-policy=OVERRIDE, i-signal-type=PRIMITIVE, init-value=0, base-type=BT_RGB_Slave_05_LedRotStg, invalid-value=Invalid_RGB_Slave_05_LedRotStg_XIX_RGBs_Slave_05_XIX_E3V_SAM_LIN5:3, compu {0=Cx0_Init (CM_RGB_Slave_05_LedRotStg_Cx0_Init), 1=Cx1_nicht_erlaubt (CM_RGB_Slave_05_LedRotStg_Cx1_nicht_erlaubt), 2=Cx2_kein_Fehler (CM_RGB_Slave_05_LedRotStg_Cx2_kein_Fehler), 3=Cx3_Fehler (CM_RGB_Slave_05_LedRotStg_Cx3_Fehler)}, range raw 0..3, transfer-property=PENDING, to SAM(timeout 3.5 s)  # Short To Ground für Rote LED
            signal RGB_Slave_05_LedGruenStg_XIX_RGBs_Slave_05_XIX_E3V_SAM_LIN5: start 10, 2 bit, little-endian, data-type-policy=OVERRIDE, i-signal-type=PRIMITIVE, init-value=0, base-type=BT_RGB_Slave_05_LedGruenStg, invalid-value=Invalid_RGB_Slave_05_LedGruenStg_XIX_RGBs_Slave_05_XIX_E3V_SAM_LIN5:3, compu {0=Cx0_Init (CM_RGB_Slave_05_LedGruenStg_Cx0_Init), 1=Cx1_nicht_erlaubt (CM_RGB_Slave_05_LedGruenStg_Cx1_nicht_erlaubt), 2=Cx2_kein_Fehler (CM_RGB_Slave_05_LedGruenStg_Cx2_kein_Fehler), 3=Cx3_Fehler (CM_RGB_Slave_05_LedGruenStg_Cx3_Fehler)}, range raw 0..3, transfer-property=PENDING, to SAM(timeout 3.5 s)  # Short To Ground für Grüne LED
            signal RGB_Slave_05_LedBlauStg_XIX_RGBs_Slave_05_XIX_E3V_SAM_LIN5: start 12, 2 bit, little-endian, data-type-policy=OVERRIDE, i-signal-type=PRIMITIVE, init-value=0, base-type=BT_RGB_Slave_05_LedBlauStg, invalid-value=Invalid_RGB_Slave_05_LedBlauStg_XIX_RGBs_Slave_05_XIX_E3V_SAM_LIN5:3, compu {0=Cx0_Init (CM_RGB_Slave_05_LedBlauStg_Cx0_Init), 1=Cx1_nicht_erlaubt (CM_RGB_Slave_05_LedBlauStg_Cx1_nicht_erlaubt), 2=Cx2_kein_Fehler (CM_RGB_Slave_05_LedBlauStg_Cx2_kein_Fehler), 3=Cx3_Fehler (CM_RGB_Slave_05_LedBlauStg_Cx3_Fehler)}, range raw 0..3, transfer-property=PENDING, to SAM(timeout 3.5 s)  # Short To Ground für Blaue LED
            signal RGB_Slave_05_LedRotOl_XIX_RGBs_Slave_05_XIX_E3V_SAM_LIN5: start 14, 2 bit, little-endian, data-type-policy=OVERRIDE, i-signal-type=PRIMITIVE, init-value=0, base-type=BT_RGB_Slave_05_LedRotOl, invalid-value=Invalid_RGB_Slave_05_LedRotOl_XIX_RGBs_Slave_05_XIX_E3V_SAM_LIN5:3, compu {0=Cx0_Init (CM_RGB_Slave_05_LedRotOl_Cx0_Init), 1=Cx1_nicht_erlaubt (CM_RGB_Slave_05_LedRotOl_Cx1_nicht_erlaubt), 2=Cx2_kein_Fehler (CM_RGB_Slave_05_LedRotOl_Cx2_kein_Fehler), 3=Cx3_Fehler (CM_RGB_Slave_05_LedRotOl_Cx3_Fehler)}, range raw 0..3, transfer-property=PENDING, to SAM(timeout 3.5 s)  # OpenLoad für Rote LED
            signal RGB_Slave_05_LedGruenOl_XIX_RGBs_Slave_05_XIX_E3V_SAM_LIN5: start 16, 2 bit, little-endian, data-type-policy=OVERRIDE, i-signal-type=PRIMITIVE, init-value=0, base-type=BT_RGB_Slave_05_LedGruenOl, invalid-value=Invalid_RGB_Slave_05_LedGruenOl_XIX_RGBs_Slave_05_XIX_E3V_SAM_LIN5:3, compu {0=Cx0_Init (CM_RGB_Slave_05_LedGruenOl_Cx0_Init), 1=Cx1_nicht_erlaubt (CM_RGB_Slave_05_LedGruenOl_Cx1_nicht_erlaubt), 2=Cx2_kein_Fehler (CM_RGB_Slave_05_LedGruenOl_Cx2_kein_Fehler), 3=Cx3_Fehler (CM_RGB_Slave_05_LedGruenOl_Cx3_Fehler)}, range raw 0..3, transfer-property=PENDING, to SAM(timeout 3.5 s)  # OpenLoad für Rote LED
            signal RGB_Slave_05_LedBlauOl_XIX_RGBs_Slave_05_XIX_E3V_SAM_LIN5: start 18, 2 bit, little-endian, data-type-policy=OVERRIDE, i-signal-type=PRIMITIVE, init-value=0, base-type=BT_RGB_Slave_05_LedBlauOl, invalid-value=Invalid_RGB_Slave_05_LedBlauOl_XIX_RGBs_Slave_05_XIX_E3V_SAM_LIN5:3, compu {0=Cx0_Init (CM_RGB_Slave_05_LedBlauOl_Cx0_Init), 1=Cx1_nicht_erlaubt (CM_RGB_Slave_05_LedBlauOl_Cx1_nicht_erlaubt), 2=Cx2_kein_Fehler (CM_RGB_Slave_05_LedBlauOl_Cx2_kein_Fehler), 3=Cx3_Fehler (CM_RGB_Slave_05_LedBlauOl_Cx3_Fehler)}, range raw 0..3, transfer-property=PENDING, to SAM(timeout 3.5 s)  # OpenLoad für Blaue LED
            signal RGB_Slave_05_TempState_XIX_RGBs_Slave_05_XIX_E3V_SAM_LIN5: start 20, 3 bit, little-endian, data-type-policy=OVERRIDE, i-signal-type=PRIMITIVE, base-type=BT_RGB_Slave_05_TempState, compu {0=Cx0_keine_Temperaturregelung (CM_RGB_Slave_05_TempState_Cx0_keine_Temperaturregelung), 1=Cx1_Regelstufe_1 (CM_RGB_Slave_05_TempState_Cx1_Regelstufe_1), 2=Cx2_Regelstufe_2 (CM_RGB_Slave_05_TempState_Cx2_Regelstufe_2), 3=Cx3_Regelstufe_3 (CM_RGB_Slave_05_TempState_Cx3_Regelstufe_3), 4=Cx4_Regelstufe_4 (CM_RGB_Slave_05_TempState_Cx4_Regelstufe_4), 5=Cx5_Regelstufe_5 (CM_RGB_Slave_05_TempState_Cx5_Regelstufe_5), 6=Cx6_Regelstufe_6 (CM_RGB_Slave_05_TempState_Cx6_Regelstufe_6), 7=Cx7_Regelstufe_7 (CM_RGB_Slave_05_TempState_Cx7_Regelstufe_7)}, range raw 0..7, transfer-property=PENDING, to SAM(timeout 3.5 s)  # Status Temperaturregelung
            signal RGB_Slave_05_IntErrorRam_XIX_RGBs_Slave_05_XIX_E3V_SAM_LIN5: start 24, 2 bit, little-endian, data-type-policy=OVERRIDE, i-signal-type=PRIMITIVE, init-value=0, base-type=BT_RGB_Slave_05_IntErrorRam, invalid-value=Invalid_RGB_Slave_05_IntErrorRam_XIX_RGBs_Slave_05_XIX_E3V_SAM_LIN5:3, compu {0=Cx0_Init (CM_RGB_Slave_05_IntErrorRam_Cx0_Init), 1=Cx1_nicht_erlaubt (CM_RGB_Slave_05_IntErrorRam_Cx1_nicht_erlaubt), 2=Cx2_kein_Fehler (CM_RGB_Slave_05_IntErrorRam_Cx2_kein_Fehler), 3=Cx3_Fehler (CM_RGB_Slave_05_IntErrorRam_Cx3_Fehler)}, range raw 0..3, transfer-property=PENDING, to SAM(timeout 3.5 s)  # Fehler im RAM
            signal RGB_Slave_05_IntErrorRom_XIX_RGBs_Slave_05_XIX_E3V_SAM_LIN5: start 26, 2 bit, little-endian, data-type-policy=OVERRIDE, i-signal-type=PRIMITIVE, init-value=0, base-type=BT_RGB_Slave_05_IntErrorRom, invalid-value=Invalid_RGB_Slave_05_IntErrorRom_XIX_RGBs_Slave_05_XIX_E3V_SAM_LIN5:3, compu {0=Cx0_Init (CM_RGB_Slave_05_IntErrorRom_Cx0_Init), 1=Cx1_nicht_erlaubt (CM_RGB_Slave_05_IntErrorRom_Cx1_nicht_erlaubt), 2=Cx2_kein_Fehler (CM_RGB_Slave_05_IntErrorRom_Cx2_kein_Fehler), 3=Cx3_Fehler (CM_RGB_Slave_05_IntErrorRom_Cx3_Fehler)}, range raw 0..3, transfer-property=PENDING, to SAM(timeout 3.5 s)  # Fehler im ROM
            signal RGB_Slave_05_IntErrorNvm_XIX_RGBs_Slave_05_XIX_E3V_SAM_LIN5: start 28, 2 bit, little-endian, data-type-policy=OVERRIDE, i-signal-type=PRIMITIVE, init-value=0, base-type=BT_RGB_Slave_05_IntErrorNvm, invalid-value=Invalid_RGB_Slave_05_IntErrorNvm_XIX_RGBs_Slave_05_XIX_E3V_SAM_LIN5:3, compu {0=Cx0_Init (CM_RGB_Slave_05_IntErrorNvm_Cx0_Init), 1=Cx1_nicht_erlaubt (CM_RGB_Slave_05_IntErrorNvm_Cx1_nicht_erlaubt), 2=Cx2_kein_Fehler (CM_RGB_Slave_05_IntErrorNvm_Cx2_kein_Fehler), 3=Cx3_Fehler (CM_RGB_Slave_05_IntErrorNvm_Cx3_Fehler)}, range raw 0..3, transfer-property=PENDING, to SAM(timeout 3.5 s)  # Fehler im NVM
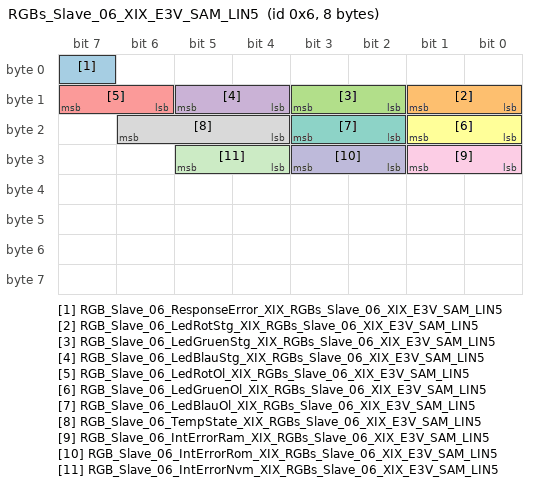
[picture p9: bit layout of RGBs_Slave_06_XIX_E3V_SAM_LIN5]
        frame RGBs_Slave_06_XIX_E3V_SAM_LIN5: id 0x6, to SAM, frame-length=8, lin-checksum=ENHANCED
          pdu RGBs_Slave_06_XIX_E3V_SAM_LIN5: length=8, unused-bit-pattern=0
            signal RGB_Slave_06_ResponseError_XIX_RGBs_Slave_06_XIX_E3V_SAM_LIN5: start 7, 1 bit, little-endian, data-type-policy=OVERRIDE, i-signal-type=PRIMITIVE, init-value=0, base-type=BT_RGB_Slave_06_ResponseError, invalid-value=Invalid_RGB_Slave_06_ResponseError_XIX_RGBs_Slave_06_XIX_E3V_SAM_LIN5:1, compu {0=Cx0_normal (CM_RGB_Slave_06_ResponseError_Cx0_normal), 1=Cx1_Fehler (CM_RGB_Slave_06_ResponseError_Cx1_Fehler)}, range raw 0..1, transfer-property=PENDING, to SAM(timeout 3.5 s)  # siehe LIN2.0-Specification (Darf nicht über ein Fehlergueltigkeitsbit abgesichtert werden!)
            signal RGB_Slave_06_LedRotStg_XIX_RGBs_Slave_06_XIX_E3V_SAM_LIN5: start 8, 2 bit, little-endian, data-type-policy=OVERRIDE, i-signal-type=PRIMITIVE, init-value=0, base-type=BT_RGB_Slave_06_LedRotStg, invalid-value=Invalid_RGB_Slave_06_LedRotStg_XIX_RGBs_Slave_06_XIX_E3V_SAM_LIN5:3, compu {0=Cx0_Init (CM_RGB_Slave_06_LedRotStg_Cx0_Init), 1=Cx1_nicht_erlaubt (CM_RGB_Slave_06_LedRotStg_Cx1_nicht_erlaubt), 2=Cx2_kein_Fehler (CM_RGB_Slave_06_LedRotStg_Cx2_kein_Fehler), 3=Cx3_Fehler (CM_RGB_Slave_06_LedRotStg_Cx3_Fehler)}, range raw 0..3, transfer-property=PENDING, to SAM(timeout 3.5 s)  # Short To Ground für Rote LED
            signal RGB_Slave_06_LedGruenStg_XIX_RGBs_Slave_06_XIX_E3V_SAM_LIN5: start 10, 2 bit, little-endian, data-type-policy=OVERRIDE, i-signal-type=PRIMITIVE, init-value=0, base-type=BT_RGB_Slave_06_LedGruenStg, invalid-value=Invalid_RGB_Slave_06_LedGruenStg_XIX_RGBs_Slave_06_XIX_E3V_SAM_LIN5:3, compu {0=Cx0_Init (CM_RGB_Slave_06_LedGruenStg_Cx0_Init), 1=Cx1_nicht_erlaubt (CM_RGB_Slave_06_LedGruenStg_Cx1_nicht_erlaubt), 2=Cx2_kein_Fehler (CM_RGB_Slave_06_LedGruenStg_Cx2_kein_Fehler), 3=Cx3_Fehler (CM_RGB_Slave_06_LedGruenStg_Cx3_Fehler)}, range raw 0..3, transfer-property=PENDING, to SAM(timeout 3.5 s)  # Short To Ground für Grüne LED
            signal RGB_Slave_06_LedBlauStg_XIX_RGBs_Slave_06_XIX_E3V_SAM_LIN5: start 12, 2 bit, little-endian, data-type-policy=OVERRIDE, i-signal-type=PRIMITIVE, init-value=0, base-type=BT_RGB_Slave_06_LedBlauStg, invalid-value=Invalid_RGB_Slave_06_LedBlauStg_XIX_RGBs_Slave_06_XIX_E3V_SAM_LIN5:3, compu {0=Cx0_Init (CM_RGB_Slave_06_LedBlauStg_Cx0_Init), 1=Cx1_nicht_erlaubt (CM_RGB_Slave_06_LedBlauStg_Cx1_nicht_erlaubt), 2=Cx2_kein_Fehler (CM_RGB_Slave_06_LedBlauStg_Cx2_kein_Fehler), 3=Cx3_Fehler (CM_RGB_Slave_06_LedBlauStg_Cx3_Fehler)}, range raw 0..3, transfer-property=PENDING, to SAM(timeout 3.5 s)  # Short To Ground für Blaue LED
            signal RGB_Slave_06_LedRotOl_XIX_RGBs_Slave_06_XIX_E3V_SAM_LIN5: start 14, 2 bit, little-endian, data-type-policy=OVERRIDE, i-signal-type=PRIMITIVE, init-value=0, base-type=BT_RGB_Slave_06_LedRotOl, invalid-value=Invalid_RGB_Slave_06_LedRotOl_XIX_RGBs_Slave_06_XIX_E3V_SAM_LIN5:3, compu {0=Cx0_Init (CM_RGB_Slave_06_LedRotOl_Cx0_Init), 1=Cx1_nicht_erlaubt (CM_RGB_Slave_06_LedRotOl_Cx1_nicht_erlaubt), 2=Cx2_kein_Fehler (CM_RGB_Slave_06_LedRotOl_Cx2_kein_Fehler), 3=Cx3_Fehler (CM_RGB_Slave_06_LedRotOl_Cx3_Fehler)}, range raw 0..3, transfer-property=PENDING, to SAM(timeout 3.5 s)  # OpenLoad für Rote LED
            signal RGB_Slave_06_LedGruenOl_XIX_RGBs_Slave_06_XIX_E3V_SAM_LIN5: start 16, 2 bit, little-endian, data-type-policy=OVERRIDE, i-signal-type=PRIMITIVE, init-value=0, base-type=BT_RGB_Slave_06_LedGruenOl, invalid-value=Invalid_RGB_Slave_06_LedGruenOl_XIX_RGBs_Slave_06_XIX_E3V_SAM_LIN5:3, compu {0=Cx0_Init (CM_RGB_Slave_06_LedGruenOl_Cx0_Init), 1=Cx1_nicht_erlaubt (CM_RGB_Slave_06_LedGruenOl_Cx1_nicht_erlaubt), 2=Cx2_kein_Fehler (CM_RGB_Slave_06_LedGruenOl_Cx2_kein_Fehler), 3=Cx3_Fehler (CM_RGB_Slave_06_LedGruenOl_Cx3_Fehler)}, range raw 0..3, transfer-property=PENDING, to SAM(timeout 3.5 s)  # OpenLoad für Rote LED
            signal RGB_Slave_06_LedBlauOl_XIX_RGBs_Slave_06_XIX_E3V_SAM_LIN5: start 18, 2 bit, little-endian, data-type-policy=OVERRIDE, i-signal-type=PRIMITIVE, init-value=0, base-type=BT_RGB_Slave_06_LedBlauOl, invalid-value=Invalid_RGB_Slave_06_LedBlauOl_XIX_RGBs_Slave_06_XIX_E3V_SAM_LIN5:3, compu {0=Cx0_Init (CM_RGB_Slave_06_LedBlauOl_Cx0_Init), 1=Cx1_nicht_erlaubt (CM_RGB_Slave_06_LedBlauOl_Cx1_nicht_erlaubt), 2=Cx2_kein_Fehler (CM_RGB_Slave_06_LedBlauOl_Cx2_kein_Fehler), 3=Cx3_Fehler (CM_RGB_Slave_06_LedBlauOl_Cx3_Fehler)}, range raw 0..3, transfer-property=PENDING, to SAM(timeout 3.5 s)  # OpenLoad für Blaue LED
            signal RGB_Slave_06_TempState_XIX_RGBs_Slave_06_XIX_E3V_SAM_LIN5: start 20, 3 bit, little-endian, data-type-policy=OVERRIDE, i-signal-type=PRIMITIVE, base-type=BT_RGB_Slave_06_TempState, compu {0=Cx0_keine_Temperaturregelung (CM_RGB_Slave_06_TempState_Cx0_keine_Temperaturregelung), 1=Cx1_Regelstufe_1 (CM_RGB_Slave_06_TempState_Cx1_Regelstufe_1), 2=Cx2_Regelstufe_2 (CM_RGB_Slave_06_TempState_Cx2_Regelstufe_2), 3=Cx3_Regelstufe_3 (CM_RGB_Slave_06_TempState_Cx3_Regelstufe_3), 4=Cx4_Regelstufe_4 (CM_RGB_Slave_06_TempState_Cx4_Regelstufe_4), 5=Cx5_Regelstufe_5 (CM_RGB_Slave_06_TempState_Cx5_Regelstufe_5), 6=Cx6_Regelstufe_6 (CM_RGB_Slave_06_TempState_Cx6_Regelstufe_6), 7=Cx7_Regelstufe_7 (CM_RGB_Slave_06_TempState_Cx7_Regelstufe_7)}, range raw 0..7, transfer-property=PENDING, to SAM(timeout 3.5 s)  # Status Temperaturregelung
            signal RGB_Slave_06_IntErrorRam_XIX_RGBs_Slave_06_XIX_E3V_SAM_LIN5: start 24, 2 bit, little-endian, data-type-policy=OVERRIDE, i-signal-type=PRIMITIVE, init-value=0, base-type=BT_RGB_Slave_06_IntErrorRam, invalid-value=Invalid_RGB_Slave_06_IntErrorRam_XIX_RGBs_Slave_06_XIX_E3V_SAM_LIN5:3, compu {0=Cx0_Init (CM_RGB_Slave_06_IntErrorRam_Cx0_Init), 1=Cx1_nicht_erlaubt (CM_RGB_Slave_06_IntErrorRam_Cx1_nicht_erlaubt), 2=Cx2_kein_Fehler (CM_RGB_Slave_06_IntErrorRam_Cx2_kein_Fehler), 3=Cx3_Fehler (CM_RGB_Slave_06_IntErrorRam_Cx3_Fehler)}, range raw 0..3, transfer-property=PENDING, to SAM(timeout 3.5 s)  # Fehler im RAM
            signal RGB_Slave_06_IntErrorRom_XIX_RGBs_Slave_06_XIX_E3V_SAM_LIN5: start 26, 2 bit, little-endian, data-type-policy=OVERRIDE, i-signal-type=PRIMITIVE, init-value=0, base-type=BT_RGB_Slave_06_IntErrorRom, invalid-value=Invalid_RGB_Slave_06_IntErrorRom_XIX_RGBs_Slave_06_XIX_E3V_SAM_LIN5:3, compu {0=Cx0_Init (CM_RGB_Slave_06_IntErrorRom_Cx0_Init), 1=Cx1_nicht_erlaubt (CM_RGB_Slave_06_IntErrorRom_Cx1_nicht_erlaubt), 2=Cx2_kein_Fehler (CM_RGB_Slave_06_IntErrorRom_Cx2_kein_Fehler), 3=Cx3_Fehler (CM_RGB_Slave_06_IntErrorRom_Cx3_Fehler)}, range raw 0..3, transfer-property=PENDING, to SAM(timeout 3.5 s)  # Fehler im ROM
            signal RGB_Slave_06_IntErrorNvm_XIX_RGBs_Slave_06_XIX_E3V_SAM_LIN5: start 28, 2 bit, little-endian, data-type-policy=OVERRIDE, i-signal-type=PRIMITIVE, init-value=0, base-type=BT_RGB_Slave_06_IntErrorNvm, invalid-value=Invalid_RGB_Slave_06_IntErrorNvm_XIX_RGBs_Slave_06_XIX_E3V_SAM_LIN5:3, compu {0=Cx0_Init (CM_RGB_Slave_06_IntErrorNvm_Cx0_Init), 1=Cx1_nicht_erlaubt (CM_RGB_Slave_06_IntErrorNvm_Cx1_nicht_erlaubt), 2=Cx2_kein_Fehler (CM_RGB_Slave_06_IntErrorNvm_Cx2_kein_Fehler), 3=Cx3_Fehler (CM_RGB_Slave_06_IntErrorNvm_Cx3_Fehler)}, range raw 0..3, transfer-property=PENDING, to SAM(timeout 3.5 s)  # Fehler im NVM
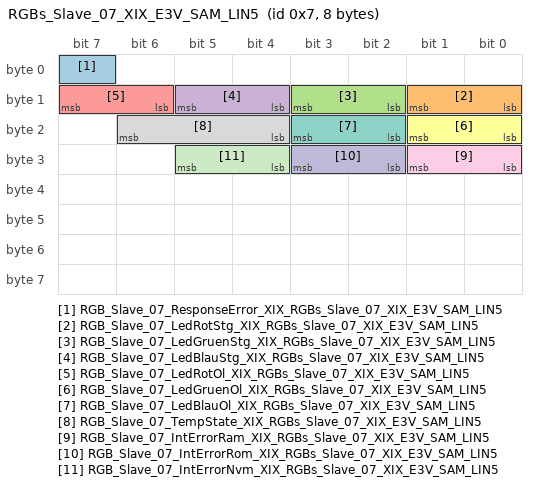
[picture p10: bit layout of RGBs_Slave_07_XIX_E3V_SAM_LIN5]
        frame RGBs_Slave_07_XIX_E3V_SAM_LIN5: id 0x7, to SAM, frame-length=8, lin-checksum=ENHANCED
          pdu RGBs_Slave_07_XIX_E3V_SAM_LIN5: length=8, unused-bit-pattern=0
            signal RGB_Slave_07_ResponseError_XIX_RGBs_Slave_07_XIX_E3V_SAM_LIN5: start 7, 1 bit, little-endian, data-type-policy=OVERRIDE, i-signal-type=PRIMITIVE, init-value=0, base-type=BT_RGB_Slave_07_ResponseError, invalid-value=Invalid_RGB_Slave_07_ResponseError_XIX_RGBs_Slave_07_XIX_E3V_SAM_LIN5:1, compu {0=Cx0_normal (CM_RGB_Slave_07_ResponseError_Cx0_normal), 1=Cx1_Fehler (CM_RGB_Slave_07_ResponseError_Cx1_Fehler)}, range raw 0..1, transfer-property=PENDING, to SAM(timeout 3.5 s)  # siehe LIN2.0-Specification (Darf nicht über ein Fehlergueltigkeitsbit abgesichtert werden!)
            signal RGB_Slave_07_LedRotStg_XIX_RGBs_Slave_07_XIX_E3V_SAM_LIN5: start 8, 2 bit, little-endian, data-type-policy=OVERRIDE, i-signal-type=PRIMITIVE, init-value=0, base-type=BT_RGB_Slave_07_LedRotStg, invalid-value=Invalid_RGB_Slave_07_LedRotStg_XIX_RGBs_Slave_07_XIX_E3V_SAM_LIN5:3, compu {0=Cx0_Init (CM_RGB_Slave_07_LedRotStg_Cx0_Init), 1=Cx1_nicht_erlaubt (CM_RGB_Slave_07_LedRotStg_Cx1_nicht_erlaubt), 2=Cx2_kein_Fehler (CM_RGB_Slave_07_LedRotStg_Cx2_kein_Fehler), 3=Cx3_Fehler (CM_RGB_Slave_07_LedRotStg_Cx3_Fehler)}, range raw 0..3, transfer-property=PENDING, to SAM(timeout 3.5 s)  # Short To Ground für Rote LED
            signal RGB_Slave_07_LedGruenStg_XIX_RGBs_Slave_07_XIX_E3V_SAM_LIN5: start 10, 2 bit, little-endian, data-type-policy=OVERRIDE, i-signal-type=PRIMITIVE, init-value=0, base-type=BT_RGB_Slave_07_LedGruenStg, invalid-value=Invalid_RGB_Slave_07_LedGruenStg_XIX_RGBs_Slave_07_XIX_E3V_SAM_LIN5:3, compu {0=Cx0_Init (CM_RGB_Slave_07_LedGruenStg_Cx0_Init), 1=Cx1_nicht_erlaubt (CM_RGB_Slave_07_LedGruenStg_Cx1_nicht_erlaubt), 2=Cx2_kein_Fehler (CM_RGB_Slave_07_LedGruenStg_Cx2_kein_Fehler), 3=Cx3_Fehler (CM_RGB_Slave_07_LedGruenStg_Cx3_Fehler)}, range raw 0..3, transfer-property=PENDING, to SAM(timeout 3.5 s)  # Short To Ground für Grüne LED
            signal RGB_Slave_07_LedBlauStg_XIX_RGBs_Slave_07_XIX_E3V_SAM_LIN5: start 12, 2 bit, little-endian, data-type-policy=OVERRIDE, i-signal-type=PRIMITIVE, init-value=0, base-type=BT_RGB_Slave_07_LedBlauStg, invalid-value=Invalid_RGB_Slave_07_LedBlauStg_XIX_RGBs_Slave_07_XIX_E3V_SAM_LIN5:3, compu {0=Cx0_Init (CM_RGB_Slave_07_LedBlauStg_Cx0_Init), 1=Cx1_nicht_erlaubt (CM_RGB_Slave_07_LedBlauStg_Cx1_nicht_erlaubt), 2=Cx2_kein_Fehler (CM_RGB_Slave_07_LedBlauStg_Cx2_kein_Fehler), 3=Cx3_Fehler (CM_RGB_Slave_07_LedBlauStg_Cx3_Fehler)}, range raw 0..3, transfer-property=PENDING, to SAM(timeout 3.5 s)  # Short To Ground für Blaue LED
            signal RGB_Slave_07_LedRotOl_XIX_RGBs_Slave_07_XIX_E3V_SAM_LIN5: start 14, 2 bit, little-endian, data-type-policy=OVERRIDE, i-signal-type=PRIMITIVE, init-value=0, base-type=BT_RGB_Slave_07_LedRotOl, invalid-value=Invalid_RGB_Slave_07_LedRotOl_XIX_RGBs_Slave_07_XIX_E3V_SAM_LIN5:3, compu {0=Cx0_Init (CM_RGB_Slave_07_LedRotOl_Cx0_Init), 1=Cx1_nicht_erlaubt (CM_RGB_Slave_07_LedRotOl_Cx1_nicht_erlaubt), 2=Cx2_kein_Fehler (CM_RGB_Slave_07_LedRotOl_Cx2_kein_Fehler), 3=Cx3_Fehler (CM_RGB_Slave_07_LedRotOl_Cx3_Fehler)}, range raw 0..3, transfer-property=PENDING, to SAM(timeout 3.5 s)  # OpenLoad für Rote LED
            signal RGB_Slave_07_LedGruenOl_XIX_RGBs_Slave_07_XIX_E3V_SAM_LIN5: start 16, 2 bit, little-endian, data-type-policy=OVERRIDE, i-signal-type=PRIMITIVE, init-value=0, base-type=BT_RGB_Slave_07_LedGruenOl, invalid-value=Invalid_RGB_Slave_07_LedGruenOl_XIX_RGBs_Slave_07_XIX_E3V_SAM_LIN5:3, compu {0=Cx0_Init (CM_RGB_Slave_07_LedGruenOl_Cx0_Init), 1=Cx1_nicht_erlaubt (CM_RGB_Slave_07_LedGruenOl_Cx1_nicht_erlaubt), 2=Cx2_kein_Fehler (CM_RGB_Slave_07_LedGruenOl_Cx2_kein_Fehler), 3=Cx3_Fehler (CM_RGB_Slave_07_LedGruenOl_Cx3_Fehler)}, range raw 0..3, transfer-property=PENDING, to SAM(timeout 3.5 s)  # OpenLoad für Rote LED
            signal RGB_Slave_07_LedBlauOl_XIX_RGBs_Slave_07_XIX_E3V_SAM_LIN5: start 18, 2 bit, little-endian, data-type-policy=OVERRIDE, i-signal-type=PRIMITIVE, init-value=0, base-type=BT_RGB_Slave_07_LedBlauOl, invalid-value=Invalid_RGB_Slave_07_LedBlauOl_XIX_RGBs_Slave_07_XIX_E3V_SAM_LIN5:3, compu {0=Cx0_Init (CM_RGB_Slave_07_LedBlauOl_Cx0_Init), 1=Cx1_nicht_erlaubt (CM_RGB_Slave_07_LedBlauOl_Cx1_nicht_erlaubt), 2=Cx2_kein_Fehler (CM_RGB_Slave_07_LedBlauOl_Cx2_kein_Fehler), 3=Cx3_Fehler (CM_RGB_Slave_07_LedBlauOl_Cx3_Fehler)}, range raw 0..3, transfer-property=PENDING, to SAM(timeout 3.5 s)  # OpenLoad für Blaue LED
            signal RGB_Slave_07_TempState_XIX_RGBs_Slave_07_XIX_E3V_SAM_LIN5: start 20, 3 bit, little-endian, data-type-policy=OVERRIDE, i-signal-type=PRIMITIVE, base-type=BT_RGB_Slave_07_TempState, compu {0=Cx0_keine_Temperaturregelung (CM_RGB_Slave_07_TempState_Cx0_keine_Temperaturregelung), 1=Cx1_Regelstufe_1 (CM_RGB_Slave_07_TempState_Cx1_Regelstufe_1), 2=Cx2_Regelstufe_2 (CM_RGB_Slave_07_TempState_Cx2_Regelstufe_2), 3=Cx3_Regelstufe_3 (CM_RGB_Slave_07_TempState_Cx3_Regelstufe_3), 4=Cx4_Regelstufe_4 (CM_RGB_Slave_07_TempState_Cx4_Regelstufe_4), 5=Cx5_Regelstufe_5 (CM_RGB_Slave_07_TempState_Cx5_Regelstufe_5), 6=Cx6_Regelstufe_6 (CM_RGB_Slave_07_TempState_Cx6_Regelstufe_6), 7=Cx7_Regelstufe_7 (CM_RGB_Slave_07_TempState_Cx7_Regelstufe_7)}, range raw 0..7, transfer-property=PENDING, to SAM(timeout 3.5 s)  # Status Temperaturregelung
            signal RGB_Slave_07_IntErrorRam_XIX_RGBs_Slave_07_XIX_E3V_SAM_LIN5: start 24, 2 bit, little-endian, data-type-policy=OVERRIDE, i-signal-type=PRIMITIVE, init-value=0, base-type=BT_RGB_Slave_07_IntErrorRam, invalid-value=Invalid_RGB_Slave_07_IntErrorRam_XIX_RGBs_Slave_07_XIX_E3V_SAM_LIN5:3, compu {0=Cx0_Init (CM_RGB_Slave_07_IntErrorRam_Cx0_Init), 1=Cx1_nicht_erlaubt (CM_RGB_Slave_07_IntErrorRam_Cx1_nicht_erlaubt), 2=Cx2_kein_Fehler (CM_RGB_Slave_07_IntErrorRam_Cx2_kein_Fehler), 3=Cx3_Fehler (CM_RGB_Slave_07_IntErrorRam_Cx3_Fehler)}, range raw 0..3, transfer-property=PENDING, to SAM(timeout 3.5 s)  # Fehler im RAM
            signal RGB_Slave_07_IntErrorRom_XIX_RGBs_Slave_07_XIX_E3V_SAM_LIN5: start 26, 2 bit, little-endian, data-type-policy=OVERRIDE, i-signal-type=PRIMITIVE, init-value=0, base-type=BT_RGB_Slave_07_IntErrorRom, invalid-value=Invalid_RGB_Slave_07_IntErrorRom_XIX_RGBs_Slave_07_XIX_E3V_SAM_LIN5:3, compu {0=Cx0_Init (CM_RGB_Slave_07_IntErrorRom_Cx0_Init), 1=Cx1_nicht_erlaubt (CM_RGB_Slave_07_IntErrorRom_Cx1_nicht_erlaubt), 2=Cx2_kein_Fehler (CM_RGB_Slave_07_IntErrorRom_Cx2_kein_Fehler), 3=Cx3_Fehler (CM_RGB_Slave_07_IntErrorRom_Cx3_Fehler)}, range raw 0..3, transfer-property=PENDING, to SAM(timeout 3.5 s)  # Fehler im ROM
            signal RGB_Slave_07_IntErrorNvm_XIX_RGBs_Slave_07_XIX_E3V_SAM_LIN5: start 28, 2 bit, little-endian, data-type-policy=OVERRIDE, i-signal-type=PRIMITIVE, init-value=0, base-type=BT_RGB_Slave_07_IntErrorNvm, invalid-value=Invalid_RGB_Slave_07_IntErrorNvm_XIX_RGBs_Slave_07_XIX_E3V_SAM_LIN5:3, compu {0=Cx0_Init (CM_RGB_Slave_07_IntErrorNvm_Cx0_Init), 1=Cx1_nicht_erlaubt (CM_RGB_Slave_07_IntErrorNvm_Cx1_nicht_erlaubt), 2=Cx2_kein_Fehler (CM_RGB_Slave_07_IntErrorNvm_Cx2_kein_Fehler), 3=Cx3_Fehler (CM_RGB_Slave_07_IntErrorNvm_Cx3_Fehler)}, range raw 0..3, transfer-property=PENDING, to SAM(timeout 3.5 s)  # Fehler im NVM
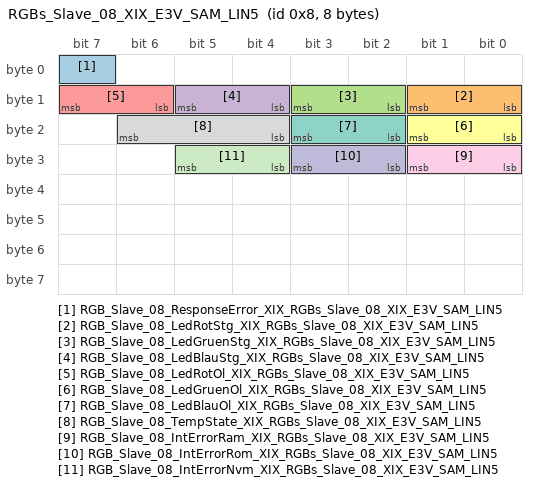
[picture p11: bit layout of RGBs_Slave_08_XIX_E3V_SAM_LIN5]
        frame RGBs_Slave_08_XIX_E3V_SAM_LIN5: id 0x8, to SAM, frame-length=8, lin-checksum=ENHANCED
          pdu RGBs_Slave_08_XIX_E3V_SAM_LIN5: length=8, unused-bit-pattern=0
            signal RGB_Slave_08_ResponseError_XIX_RGBs_Slave_08_XIX_E3V_SAM_LIN5: start 7, 1 bit, little-endian, data-type-policy=OVERRIDE, i-signal-type=PRIMITIVE, init-value=0, base-type=BT_RGB_Slave_08_ResponseError, invalid-value=Invalid_RGB_Slave_08_ResponseError_XIX_RGBs_Slave_08_XIX_E3V_SAM_LIN5:1, compu {0=Cx0_normal (CM_RGB_Slave_08_ResponseError_Cx0_normal), 1=Cx1_Fehler (CM_RGB_Slave_08_ResponseError_Cx1_Fehler)}, range raw 0..1, transfer-property=PENDING, to SAM(timeout 3.5 s)  # siehe LIN2.0-Specification (Darf nicht über ein Fehlergueltigkeitsbit abgesichtert werden!)
            signal RGB_Slave_08_LedRotStg_XIX_RGBs_Slave_08_XIX_E3V_SAM_LIN5: start 8, 2 bit, little-endian, data-type-policy=OVERRIDE, i-signal-type=PRIMITIVE, init-value=0, base-type=BT_RGB_Slave_08_LedRotStg, invalid-value=Invalid_RGB_Slave_08_LedRotStg_XIX_RGBs_Slave_08_XIX_E3V_SAM_LIN5:3, compu {0=Cx0_Init (CM_RGB_Slave_08_LedRotStg_Cx0_Init), 1=Cx1_nicht_erlaubt (CM_RGB_Slave_08_LedRotStg_Cx1_nicht_erlaubt), 2=Cx2_kein_Fehler (CM_RGB_Slave_08_LedRotStg_Cx2_kein_Fehler), 3=Cx3_Fehler (CM_RGB_Slave_08_LedRotStg_Cx3_Fehler)}, range raw 0..3, transfer-property=PENDING, to SAM(timeout 3.5 s)  # Short To Ground für Rote LED
            signal RGB_Slave_08_LedGruenStg_XIX_RGBs_Slave_08_XIX_E3V_SAM_LIN5: start 10, 2 bit, little-endian, data-type-policy=OVERRIDE, i-signal-type=PRIMITIVE, init-value=0, base-type=BT_RGB_Slave_08_LedGruenStg, invalid-value=Invalid_RGB_Slave_08_LedGruenStg_XIX_RGBs_Slave_08_XIX_E3V_SAM_LIN5:3, compu {0=Cx0_Init (CM_RGB_Slave_08_LedGruenStg_Cx0_Init), 1=Cx1_nicht_erlaubt (CM_RGB_Slave_08_LedGruenStg_Cx1_nicht_erlaubt), 2=Cx2_kein_Fehler (CM_RGB_Slave_08_LedGruenStg_Cx2_kein_Fehler), 3=Cx3_Fehler (CM_RGB_Slave_08_LedGruenStg_Cx3_Fehler)}, range raw 0..3, transfer-property=PENDING, to SAM(timeout 3.5 s)  # Short To Ground für Grüne LED
            signal RGB_Slave_08_LedBlauStg_XIX_RGBs_Slave_08_XIX_E3V_SAM_LIN5: start 12, 2 bit, little-endian, data-type-policy=OVERRIDE, i-signal-type=PRIMITIVE, init-value=0, base-type=BT_RGB_Slave_08_LedBlauStg, invalid-value=Invalid_RGB_Slave_08_LedBlauStg_XIX_RGBs_Slave_08_XIX_E3V_SAM_LIN5:3, compu {0=Cx0_Init (CM_RGB_Slave_08_LedBlauStg_Cx0_Init), 1=Cx1_nicht_erlaubt (CM_RGB_Slave_08_LedBlauStg_Cx1_nicht_erlaubt), 2=Cx2_kein_Fehler (CM_RGB_Slave_08_LedBlauStg_Cx2_kein_Fehler), 3=Cx3_Fehler (CM_RGB_Slave_08_LedBlauStg_Cx3_Fehler)}, range raw 0..3, transfer-property=PENDING, to SAM(timeout 3.5 s)  # Short To Ground für Blaue LED
            signal RGB_Slave_08_LedRotOl_XIX_RGBs_Slave_08_XIX_E3V_SAM_LIN5: start 14, 2 bit, little-endian, data-type-policy=OVERRIDE, i-signal-type=PRIMITIVE, init-value=0, base-type=BT_RGB_Slave_08_LedRotOl, invalid-value=Invalid_RGB_Slave_08_LedRotOl_XIX_RGBs_Slave_08_XIX_E3V_SAM_LIN5:3, compu {0=Cx0_Init (CM_RGB_Slave_08_LedRotOl_Cx0_Init), 1=Cx1_nicht_erlaubt (CM_RGB_Slave_08_LedRotOl_Cx1_nicht_erlaubt), 2=Cx2_kein_Fehler (CM_RGB_Slave_08_LedRotOl_Cx2_kein_Fehler), 3=Cx3_Fehler (CM_RGB_Slave_08_LedRotOl_Cx3_Fehler)}, range raw 0..3, transfer-property=PENDING, to SAM(timeout 3.5 s)  # OpenLoad für Rote LED
            signal RGB_Slave_08_LedGruenOl_XIX_RGBs_Slave_08_XIX_E3V_SAM_LIN5: start 16, 2 bit, little-endian, data-type-policy=OVERRIDE, i-signal-type=PRIMITIVE, init-value=0, base-type=BT_RGB_Slave_08_LedGruenOl, invalid-value=Invalid_RGB_Slave_08_LedGruenOl_XIX_RGBs_Slave_08_XIX_E3V_SAM_LIN5:3, compu {0=Cx0_Init (CM_RGB_Slave_08_LedGruenOl_Cx0_Init), 1=Cx1_nicht_erlaubt (CM_RGB_Slave_08_LedGruenOl_Cx1_nicht_erlaubt), 2=Cx2_kein_Fehler (CM_RGB_Slave_08_LedGruenOl_Cx2_kein_Fehler), 3=Cx3_Fehler (CM_RGB_Slave_08_LedGruenOl_Cx3_Fehler)}, range raw 0..3, transfer-property=PENDING, to SAM(timeout 3.5 s)  # OpenLoad für Rote LED
            signal RGB_Slave_08_LedBlauOl_XIX_RGBs_Slave_08_XIX_E3V_SAM_LIN5: start 18, 2 bit, little-endian, data-type-policy=OVERRIDE, i-signal-type=PRIMITIVE, init-value=0, base-type=BT_RGB_Slave_08_LedBlauOl, invalid-value=Invalid_RGB_Slave_08_LedBlauOl_XIX_RGBs_Slave_08_XIX_E3V_SAM_LIN5:3, compu {0=Cx0_Init (CM_RGB_Slave_08_LedBlauOl_Cx0_Init), 1=Cx1_nicht_erlaubt (CM_RGB_Slave_08_LedBlauOl_Cx1_nicht_erlaubt), 2=Cx2_kein_Fehler (CM_RGB_Slave_08_LedBlauOl_Cx2_kein_Fehler), 3=Cx3_Fehler (CM_RGB_Slave_08_LedBlauOl_Cx3_Fehler)}, range raw 0..3, transfer-property=PENDING, to SAM(timeout 3.5 s)  # OpenLoad für Blaue LED
            signal RGB_Slave_08_TempState_XIX_RGBs_Slave_08_XIX_E3V_SAM_LIN5: start 20, 3 bit, little-endian, data-type-policy=OVERRIDE, i-signal-type=PRIMITIVE, base-type=BT_RGB_Slave_08_TempState, compu {0=Cx0_keine_Temperaturregelung (CM_RGB_Slave_08_TempState_Cx0_keine_Temperaturregelung), 1=Cx1_Regelstufe_1 (CM_RGB_Slave_08_TempState_Cx1_Regelstufe_1), 2=Cx2_Regelstufe_2 (CM_RGB_Slave_08_TempState_Cx2_Regelstufe_2), 3=Cx3_Regelstufe_3 (CM_RGB_Slave_08_TempState_Cx3_Regelstufe_3), 4=Cx4_Regelstufe_4 (CM_RGB_Slave_08_TempState_Cx4_Regelstufe_4), 5=Cx5_Regelstufe_5 (CM_RGB_Slave_08_TempState_Cx5_Regelstufe_5), 6=Cx6_Regelstufe_6 (CM_RGB_Slave_08_TempState_Cx6_Regelstufe_6), 7=Cx7_Regelstufe_7 (CM_RGB_Slave_08_TempState_Cx7_Regelstufe_7)}, range raw 0..7, transfer-property=PENDING, to SAM(timeout 3.5 s)  # Status Temperaturregelung
            signal RGB_Slave_08_IntErrorRam_XIX_RGBs_Slave_08_XIX_E3V_SAM_LIN5: start 24, 2 bit, little-endian, data-type-policy=OVERRIDE, i-signal-type=PRIMITIVE, init-value=0, base-type=BT_RGB_Slave_08_IntErrorRam, invalid-value=Invalid_RGB_Slave_08_IntErrorRam_XIX_RGBs_Slave_08_XIX_E3V_SAM_LIN5:3, compu {0=Cx0_Init (CM_RGB_Slave_08_IntErrorRam_Cx0_Init), 1=Cx1_nicht_erlaubt (CM_RGB_Slave_08_IntErrorRam_Cx1_nicht_erlaubt), 2=Cx2_kein_Fehler (CM_RGB_Slave_08_IntErrorRam_Cx2_kein_Fehler), 3=Cx3_Fehler (CM_RGB_Slave_08_IntErrorRam_Cx3_Fehler)}, range raw 0..3, transfer-property=PENDING, to SAM(timeout 3.5 s)  # Fehler im RAM
            signal RGB_Slave_08_IntErrorRom_XIX_RGBs_Slave_08_XIX_E3V_SAM_LIN5: start 26, 2 bit, little-endian, data-type-policy=OVERRIDE, i-signal-type=PRIMITIVE, init-value=0, base-type=BT_RGB_Slave_08_IntErrorRom, invalid-value=Invalid_RGB_Slave_08_IntErrorRom_XIX_RGBs_Slave_08_XIX_E3V_SAM_LIN5:3, compu {0=Cx0_Init (CM_RGB_Slave_08_IntErrorRom_Cx0_Init), 1=Cx1_nicht_erlaubt (CM_RGB_Slave_08_IntErrorRom_Cx1_nicht_erlaubt), 2=Cx2_kein_Fehler (CM_RGB_Slave_08_IntErrorRom_Cx2_kein_Fehler), 3=Cx3_Fehler (CM_RGB_Slave_08_IntErrorRom_Cx3_Fehler)}, range raw 0..3, transfer-property=PENDING, to SAM(timeout 3.5 s)  # Fehler im ROM
            signal RGB_Slave_08_IntErrorNvm_XIX_RGBs_Slave_08_XIX_E3V_SAM_LIN5: start 28, 2 bit, little-endian, data-type-policy=OVERRIDE, i-signal-type=PRIMITIVE, init-value=0, base-type=BT_RGB_Slave_08_IntErrorNvm, invalid-value=Invalid_RGB_Slave_08_IntErrorNvm_XIX_RGBs_Slave_08_XIX_E3V_SAM_LIN5:3, compu {0=Cx0_Init (CM_RGB_Slave_08_IntErrorNvm_Cx0_Init), 1=Cx1_nicht_erlaubt (CM_RGB_Slave_08_IntErrorNvm_Cx1_nicht_erlaubt), 2=Cx2_kein_Fehler (CM_RGB_Slave_08_IntErrorNvm_Cx2_kein_Fehler), 3=Cx3_Fehler (CM_RGB_Slave_08_IntErrorNvm_Cx3_Fehler)}, range raw 0..3, transfer-property=PENDING, to SAM(timeout 3.5 s)  # Fehler im NVM
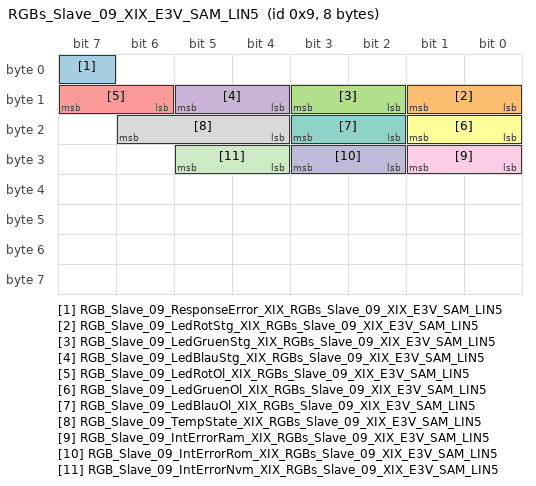
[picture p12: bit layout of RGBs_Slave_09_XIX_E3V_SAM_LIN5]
        frame RGBs_Slave_09_XIX_E3V_SAM_LIN5: id 0x9, to SAM, frame-length=8, lin-checksum=ENHANCED
          pdu RGBs_Slave_09_XIX_E3V_SAM_LIN5: length=8, unused-bit-pattern=0
            signal RGB_Slave_09_ResponseError_XIX_RGBs_Slave_09_XIX_E3V_SAM_LIN5: start 7, 1 bit, little-endian, data-type-policy=OVERRIDE, i-signal-type=PRIMITIVE, init-value=0, base-type=BT_RGB_Slave_09_ResponseError, invalid-value=Invalid_RGB_Slave_09_ResponseError_XIX_RGBs_Slave_09_XIX_E3V_SAM_LIN5:1, compu {0=Cx0_normal (CM_RGB_Slave_09_ResponseError_Cx0_normal), 1=Cx1_Fehler (CM_RGB_Slave_09_ResponseError_Cx1_Fehler)}, range raw 0..1, transfer-property=PENDING, to SAM(timeout 3.5 s)  # siehe LIN2.0-Specification (Darf nicht über ein Fehlergueltigkeitsbit abgesichtert werden!)
            signal RGB_Slave_09_LedRotStg_XIX_RGBs_Slave_09_XIX_E3V_SAM_LIN5: start 8, 2 bit, little-endian, data-type-policy=OVERRIDE, i-signal-type=PRIMITIVE, init-value=0, base-type=BT_RGB_Slave_09_LedRotStg, invalid-value=Invalid_RGB_Slave_09_LedRotStg_XIX_RGBs_Slave_09_XIX_E3V_SAM_LIN5:3, compu {0=Cx0_Init (CM_RGB_Slave_09_LedRotStg_Cx0_Init), 1=Cx1_nicht_erlaubt (CM_RGB_Slave_09_LedRotStg_Cx1_nicht_erlaubt), 2=Cx2_kein_Fehler (CM_RGB_Slave_09_LedRotStg_Cx2_kein_Fehler), 3=Cx3_Fehler (CM_RGB_Slave_09_LedRotStg_Cx3_Fehler)}, range raw 0..3, transfer-property=PENDING, to SAM(timeout 3.5 s)  # Short To Ground für Rote LED
            signal RGB_Slave_09_LedGruenStg_XIX_RGBs_Slave_09_XIX_E3V_SAM_LIN5: start 10, 2 bit, little-endian, data-type-policy=OVERRIDE, i-signal-type=PRIMITIVE, init-value=0, base-type=BT_RGB_Slave_09_LedGruenStg, invalid-value=Invalid_RGB_Slave_09_LedGruenStg_XIX_RGBs_Slave_09_XIX_E3V_SAM_LIN5:3, compu {0=Cx0_Init (CM_RGB_Slave_09_LedGruenStg_Cx0_Init), 1=Cx1_nicht_erlaubt (CM_RGB_Slave_09_LedGruenStg_Cx1_nicht_erlaubt), 2=Cx2_kein_Fehler (CM_RGB_Slave_09_LedGruenStg_Cx2_kein_Fehler), 3=Cx3_Fehler (CM_RGB_Slave_09_LedGruenStg_Cx3_Fehler)}, range raw 0..3, transfer-property=PENDING, to SAM(timeout 3.5 s)  # Short To Ground für Grüne LED
            signal RGB_Slave_09_LedBlauStg_XIX_RGBs_Slave_09_XIX_E3V_SAM_LIN5: start 12, 2 bit, little-endian, data-type-policy=OVERRIDE, i-signal-type=PRIMITIVE, init-value=0, base-type=BT_RGB_Slave_09_LedBlauStg, invalid-value=Invalid_RGB_Slave_09_LedBlauStg_XIX_RGBs_Slave_09_XIX_E3V_SAM_LIN5:3, compu {0=Cx0_Init (CM_RGB_Slave_09_LedBlauStg_Cx0_Init), 1=Cx1_nicht_erlaubt (CM_RGB_Slave_09_LedBlauStg_Cx1_nicht_erlaubt), 2=Cx2_kein_Fehler (CM_RGB_Slave_09_LedBlauStg_Cx2_kein_Fehler), 3=Cx3_Fehler (CM_RGB_Slave_09_LedBlauStg_Cx3_Fehler)}, range raw 0..3, transfer-property=PENDING, to SAM(timeout 3.5 s)  # Short To Ground für Blaue LED
            signal RGB_Slave_09_LedRotOl_XIX_RGBs_Slave_09_XIX_E3V_SAM_LIN5: start 14, 2 bit, little-endian, data-type-policy=OVERRIDE, i-signal-type=PRIMITIVE, init-value=0, base-type=BT_RGB_Slave_09_LedRotOl, invalid-value=Invalid_RGB_Slave_09_LedRotOl_XIX_RGBs_Slave_09_XIX_E3V_SAM_LIN5:3, compu {0=Cx0_Init (CM_RGB_Slave_09_LedRotOl_Cx0_Init), 1=Cx1_nicht_erlaubt (CM_RGB_Slave_09_LedRotOl_Cx1_nicht_erlaubt), 2=Cx2_kein_Fehler (CM_RGB_Slave_09_LedRotOl_Cx2_kein_Fehler), 3=Cx3_Fehler (CM_RGB_Slave_09_LedRotOl_Cx3_Fehler)}, range raw 0..3, transfer-property=PENDING, to SAM(timeout 3.5 s)  # OpenLoad für Rote LED
            signal RGB_Slave_09_LedGruenOl_XIX_RGBs_Slave_09_XIX_E3V_SAM_LIN5: start 16, 2 bit, little-endian, data-type-policy=OVERRIDE, i-signal-type=PRIMITIVE, init-value=0, base-type=BT_RGB_Slave_09_LedGruenOl, invalid-value=Invalid_RGB_Slave_09_LedGruenOl_XIX_RGBs_Slave_09_XIX_E3V_SAM_LIN5:3, compu {0=Cx0_Init (CM_RGB_Slave_09_LedGruenOl_Cx0_Init), 1=Cx1_nicht_erlaubt (CM_RGB_Slave_09_LedGruenOl_Cx1_nicht_erlaubt), 2=Cx2_kein_Fehler (CM_RGB_Slave_09_LedGruenOl_Cx2_kein_Fehler), 3=Cx3_Fehler (CM_RGB_Slave_09_LedGruenOl_Cx3_Fehler)}, range raw 0..3, transfer-property=PENDING, to SAM(timeout 3.5 s)  # OpenLoad für Rote LED
            signal RGB_Slave_09_LedBlauOl_XIX_RGBs_Slave_09_XIX_E3V_SAM_LIN5: start 18, 2 bit, little-endian, data-type-policy=OVERRIDE, i-signal-type=PRIMITIVE, init-value=0, base-type=BT_RGB_Slave_09_LedBlauOl, invalid-value=Invalid_RGB_Slave_09_LedBlauOl_XIX_RGBs_Slave_09_XIX_E3V_SAM_LIN5:3, compu {0=Cx0_Init (CM_RGB_Slave_09_LedBlauOl_Cx0_Init), 1=Cx1_nicht_erlaubt (CM_RGB_Slave_09_LedBlauOl_Cx1_nicht_erlaubt), 2=Cx2_kein_Fehler (CM_RGB_Slave_09_LedBlauOl_Cx2_kein_Fehler), 3=Cx3_Fehler (CM_RGB_Slave_09_LedBlauOl_Cx3_Fehler)}, range raw 0..3, transfer-property=PENDING, to SAM(timeout 3.5 s)  # OpenLoad für Blaue LED
            signal RGB_Slave_09_TempState_XIX_RGBs_Slave_09_XIX_E3V_SAM_LIN5: start 20, 3 bit, little-endian, data-type-policy=OVERRIDE, i-signal-type=PRIMITIVE, base-type=BT_RGB_Slave_09_TempState, compu {0=Cx0_keine_Temperaturregelung (CM_RGB_Slave_09_TempState_Cx0_keine_Temperaturregelung), 1=Cx1_Regelstufe_1 (CM_RGB_Slave_09_TempState_Cx1_Regelstufe_1), 2=Cx2_Regelstufe_2 (CM_RGB_Slave_09_TempState_Cx2_Regelstufe_2), 3=Cx3_Regelstufe_3 (CM_RGB_Slave_09_TempState_Cx3_Regelstufe_3), 4=Cx4_Regelstufe_4 (CM_RGB_Slave_09_TempState_Cx4_Regelstufe_4), 5=Cx5_Regelstufe_5 (CM_RGB_Slave_09_TempState_Cx5_Regelstufe_5), 6=Cx6_Regelstufe_6 (CM_RGB_Slave_09_TempState_Cx6_Regelstufe_6), 7=Cx7_Regelstufe_7 (CM_RGB_Slave_09_TempState_Cx7_Regelstufe_7)}, range raw 0..7, transfer-property=PENDING, to SAM(timeout 3.5 s)  # Status Temperaturregelung
            signal RGB_Slave_09_IntErrorRam_XIX_RGBs_Slave_09_XIX_E3V_SAM_LIN5: start 24, 2 bit, little-endian, data-type-policy=OVERRIDE, i-signal-type=PRIMITIVE, init-value=0, base-type=BT_RGB_Slave_09_IntErrorRam, invalid-value=Invalid_RGB_Slave_09_IntErrorRam_XIX_RGBs_Slave_09_XIX_E3V_SAM_LIN5:3, compu {0=Cx0_Init (CM_RGB_Slave_09_IntErrorRam_Cx0_Init), 1=Cx1_nicht_erlaubt (CM_RGB_Slave_09_IntErrorRam_Cx1_nicht_erlaubt), 2=Cx2_kein_Fehler (CM_RGB_Slave_09_IntErrorRam_Cx2_kein_Fehler), 3=Cx3_Fehler (CM_RGB_Slave_09_IntErrorRam_Cx3_Fehler)}, range raw 0..3, transfer-property=PENDING, to SAM(timeout 3.5 s)  # Fehler im RAM
            signal RGB_Slave_09_IntErrorRom_XIX_RGBs_Slave_09_XIX_E3V_SAM_LIN5: start 26, 2 bit, little-endian, data-type-policy=OVERRIDE, i-signal-type=PRIMITIVE, init-value=0, base-type=BT_RGB_Slave_09_IntErrorRom, invalid-value=Invalid_RGB_Slave_09_IntErrorRom_XIX_RGBs_Slave_09_XIX_E3V_SAM_LIN5:3, compu {0=Cx0_Init (CM_RGB_Slave_09_IntErrorRom_Cx0_Init), 1=Cx1_nicht_erlaubt (CM_RGB_Slave_09_IntErrorRom_Cx1_nicht_erlaubt), 2=Cx2_kein_Fehler (CM_RGB_Slave_09_IntErrorRom_Cx2_kein_Fehler), 3=Cx3_Fehler (CM_RGB_Slave_09_IntErrorRom_Cx3_Fehler)}, range raw 0..3, transfer-property=PENDING, to SAM(timeout 3.5 s)  # Fehler im ROM
            signal RGB_Slave_09_IntErrorNvm_XIX_RGBs_Slave_09_XIX_E3V_SAM_LIN5: start 28, 2 bit, little-endian, data-type-policy=OVERRIDE, i-signal-type=PRIMITIVE, init-value=0, base-type=BT_RGB_Slave_09_IntErrorNvm, invalid-value=Invalid_RGB_Slave_09_IntErrorNvm_XIX_RGBs_Slave_09_XIX_E3V_SAM_LIN5:3, compu {0=Cx0_Init (CM_RGB_Slave_09_IntErrorNvm_Cx0_Init), 1=Cx1_nicht_erlaubt (CM_RGB_Slave_09_IntErrorNvm_Cx1_nicht_erlaubt), 2=Cx2_kein_Fehler (CM_RGB_Slave_09_IntErrorNvm_Cx2_kein_Fehler), 3=Cx3_Fehler (CM_RGB_Slave_09_IntErrorNvm_Cx3_Fehler)}, range raw 0..3, transfer-property=PENDING, to SAM(timeout 3.5 s)  # Fehler im NVM
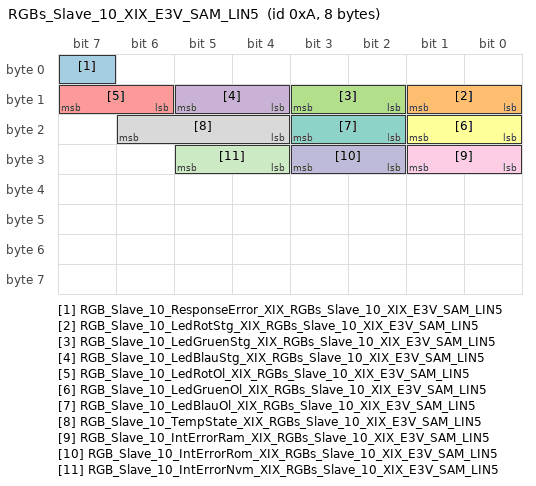
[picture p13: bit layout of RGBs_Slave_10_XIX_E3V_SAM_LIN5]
        frame RGBs_Slave_10_XIX_E3V_SAM_LIN5: id 0xA, to SAM, frame-length=8, lin-checksum=ENHANCED
          pdu RGBs_Slave_10_XIX_E3V_SAM_LIN5: length=8, unused-bit-pattern=0
            signal RGB_Slave_10_ResponseError_XIX_RGBs_Slave_10_XIX_E3V_SAM_LIN5: start 7, 1 bit, little-endian, data-type-policy=OVERRIDE, i-signal-type=PRIMITIVE, init-value=0, base-type=BT_RGB_Slave_10_ResponseError, invalid-value=Invalid_RGB_Slave_10_ResponseError_XIX_RGBs_Slave_10_XIX_E3V_SAM_LIN5:1, compu {0=Cx0_normal (CM_RGB_Slave_10_ResponseError_Cx0_normal), 1=Cx1_Fehler (CM_RGB_Slave_10_ResponseError_Cx1_Fehler)}, range raw 0..1, transfer-property=PENDING, to SAM(timeout 3.5 s)  # siehe LIN2.0-Specification (Darf nicht über ein Fehlergueltigkeitsbit abgesichtert werden!)
            signal RGB_Slave_10_LedRotStg_XIX_RGBs_Slave_10_XIX_E3V_SAM_LIN5: start 8, 2 bit, little-endian, data-type-policy=OVERRIDE, i-signal-type=PRIMITIVE, init-value=0, base-type=BT_RGB_Slave_10_LedRotStg, invalid-value=Invalid_RGB_Slave_10_LedRotStg_XIX_RGBs_Slave_10_XIX_E3V_SAM_LIN5:3, compu {0=Cx0_Init (CM_RGB_Slave_10_LedRotStg_Cx0_Init), 1=Cx1_nicht_erlaubt (CM_RGB_Slave_10_LedRotStg_Cx1_nicht_erlaubt), 2=Cx2_kein_Fehler (CM_RGB_Slave_10_LedRotStg_Cx2_kein_Fehler), 3=Cx3_Fehler (CM_RGB_Slave_10_LedRotStg_Cx3_Fehler)}, range raw 0..3, transfer-property=PENDING, to SAM(timeout 3.5 s)  # Short To Ground für Rote LED
            signal RGB_Slave_10_LedGruenStg_XIX_RGBs_Slave_10_XIX_E3V_SAM_LIN5: start 10, 2 bit, little-endian, data-type-policy=OVERRIDE, i-signal-type=PRIMITIVE, init-value=0, base-type=BT_RGB_Slave_10_LedGruenStg, invalid-value=Invalid_RGB_Slave_10_LedGruenStg_XIX_RGBs_Slave_10_XIX_E3V_SAM_LIN5:3, compu {0=Cx0_Init (CM_RGB_Slave_10_LedGruenStg_Cx0_Init), 1=Cx1_nicht_erlaubt (CM_RGB_Slave_10_LedGruenStg_Cx1_nicht_erlaubt), 2=Cx2_kein_Fehler (CM_RGB_Slave_10_LedGruenStg_Cx2_kein_Fehler), 3=Cx3_Fehler (CM_RGB_Slave_10_LedGruenStg_Cx3_Fehler)}, range raw 0..3, transfer-property=PENDING, to SAM(timeout 3.5 s)  # Short To Ground für Grüne LED
            signal RGB_Slave_10_LedBlauStg_XIX_RGBs_Slave_10_XIX_E3V_SAM_LIN5: start 12, 2 bit, little-endian, data-type-policy=OVERRIDE, i-signal-type=PRIMITIVE, init-value=0, base-type=BT_RGB_Slave_10_LedBlauStg, invalid-value=Invalid_RGB_Slave_10_LedBlauStg_XIX_RGBs_Slave_10_XIX_E3V_SAM_LIN5:3, compu {0=Cx0_Init (CM_RGB_Slave_10_LedBlauStg_Cx0_Init), 1=Cx1_nicht_erlaubt (CM_RGB_Slave_10_LedBlauStg_Cx1_nicht_erlaubt), 2=Cx2_kein_Fehler (CM_RGB_Slave_10_LedBlauStg_Cx2_kein_Fehler), 3=Cx3_Fehler (CM_RGB_Slave_10_LedBlauStg_Cx3_Fehler)}, range raw 0..3, transfer-property=PENDING, to SAM(timeout 3.5 s)  # Short To Ground für Blaue LED
            signal RGB_Slave_10_LedRotOl_XIX_RGBs_Slave_10_XIX_E3V_SAM_LIN5: start 14, 2 bit, little-endian, data-type-policy=OVERRIDE, i-signal-type=PRIMITIVE, init-value=0, base-type=BT_RGB_Slave_10_LedRotOl, invalid-value=Invalid_RGB_Slave_10_LedRotOl_XIX_RGBs_Slave_10_XIX_E3V_SAM_LIN5:3, compu {0=Cx0_Init (CM_RGB_Slave_10_LedRotOl_Cx0_Init), 1=Cx1_nicht_erlaubt (CM_RGB_Slave_10_LedRotOl_Cx1_nicht_erlaubt), 2=Cx2_kein_Fehler (CM_RGB_Slave_10_LedRotOl_Cx2_kein_Fehler), 3=Cx3_Fehler (CM_RGB_Slave_10_LedRotOl_Cx3_Fehler)}, range raw 0..3, transfer-property=PENDING, to SAM(timeout 3.5 s)  # OpenLoad für Rote LED
            signal RGB_Slave_10_LedGruenOl_XIX_RGBs_Slave_10_XIX_E3V_SAM_LIN5: start 16, 2 bit, little-endian, data-type-policy=OVERRIDE, i-signal-type=PRIMITIVE, init-value=0, base-type=BT_RGB_Slave_10_LedGruenOl, invalid-value=Invalid_RGB_Slave_10_LedGruenOl_XIX_RGBs_Slave_10_XIX_E3V_SAM_LIN5:3, compu {0=Cx0_Init (CM_RGB_Slave_10_LedGruenOl_Cx0_Init), 1=Cx1_nicht_erlaubt (CM_RGB_Slave_10_LedGruenOl_Cx1_nicht_erlaubt), 2=Cx2_kein_Fehler (CM_RGB_Slave_10_LedGruenOl_Cx2_kein_Fehler), 3=Cx3_Fehler (CM_RGB_Slave_10_LedGruenOl_Cx3_Fehler)}, range raw 0..3, transfer-property=PENDING, to SAM(timeout 3.5 s)  # OpenLoad für Rote LED
            signal RGB_Slave_10_LedBlauOl_XIX_RGBs_Slave_10_XIX_E3V_SAM_LIN5: start 18, 2 bit, little-endian, data-type-policy=OVERRIDE, i-signal-type=PRIMITIVE, init-value=0, base-type=BT_RGB_Slave_10_LedBlauOl, invalid-value=Invalid_RGB_Slave_10_LedBlauOl_XIX_RGBs_Slave_10_XIX_E3V_SAM_LIN5:3, compu {0=Cx0_Init (CM_RGB_Slave_10_LedBlauOl_Cx0_Init), 1=Cx1_nicht_erlaubt (CM_RGB_Slave_10_LedBlauOl_Cx1_nicht_erlaubt), 2=Cx2_kein_Fehler (CM_RGB_Slave_10_LedBlauOl_Cx2_kein_Fehler), 3=Cx3_Fehler (CM_RGB_Slave_10_LedBlauOl_Cx3_Fehler)}, range raw 0..3, transfer-property=PENDING, to SAM(timeout 3.5 s)  # OpenLoad für Blaue LED
            signal RGB_Slave_10_TempState_XIX_RGBs_Slave_10_XIX_E3V_SAM_LIN5: start 20, 3 bit, little-endian, data-type-policy=OVERRIDE, i-signal-type=PRIMITIVE, base-type=BT_RGB_Slave_10_TempState, compu {0=Cx0_keine_Temperaturregelung (CM_RGB_Slave_10_TempState_Cx0_keine_Temperaturregelung), 1=Cx1_Regelstufe_1 (CM_RGB_Slave_10_TempState_Cx1_Regelstufe_1), 2=Cx2_Regelstufe_2 (CM_RGB_Slave_10_TempState_Cx2_Regelstufe_2), 3=Cx3_Regelstufe_3 (CM_RGB_Slave_10_TempState_Cx3_Regelstufe_3), 4=Cx4_Regelstufe_4 (CM_RGB_Slave_10_TempState_Cx4_Regelstufe_4), 5=Cx5_Regelstufe_5 (CM_RGB_Slave_10_TempState_Cx5_Regelstufe_5), 6=Cx6_Regelstufe_6 (CM_RGB_Slave_10_TempState_Cx6_Regelstufe_6), 7=Cx7_Regelstufe_7 (CM_RGB_Slave_10_TempState_Cx7_Regelstufe_7)}, range raw 0..7, transfer-property=PENDING, to SAM(timeout 3.5 s)  # Status Temperaturregelung
            signal RGB_Slave_10_IntErrorRam_XIX_RGBs_Slave_10_XIX_E3V_SAM_LIN5: start 24, 2 bit, little-endian, data-type-policy=OVERRIDE, i-signal-type=PRIMITIVE, init-value=0, base-type=BT_RGB_Slave_10_IntErrorRam, invalid-value=Invalid_RGB_Slave_10_IntErrorRam_XIX_RGBs_Slave_10_XIX_E3V_SAM_LIN5:3, compu {0=Cx0_Init (CM_RGB_Slave_10_IntErrorRam_Cx0_Init), 1=Cx1_nicht_erlaubt (CM_RGB_Slave_10_IntErrorRam_Cx1_nicht_erlaubt), 2=Cx2_kein_Fehler (CM_RGB_Slave_10_IntErrorRam_Cx2_kein_Fehler), 3=Cx3_Fehler (CM_RGB_Slave_10_IntErrorRam_Cx3_Fehler)}, range raw 0..3, transfer-property=PENDING, to SAM(timeout 3.5 s)  # Fehler im RAM
            signal RGB_Slave_10_IntErrorRom_XIX_RGBs_Slave_10_XIX_E3V_SAM_LIN5: start 26, 2 bit, little-endian, data-type-policy=OVERRIDE, i-signal-type=PRIMITIVE, init-value=0, base-type=BT_RGB_Slave_10_IntErrorRom, invalid-value=Invalid_RGB_Slave_10_IntErrorRom_XIX_RGBs_Slave_10_XIX_E3V_SAM_LIN5:3, compu {0=Cx0_Init (CM_RGB_Slave_10_IntErrorRom_Cx0_Init), 1=Cx1_nicht_erlaubt (CM_RGB_Slave_10_IntErrorRom_Cx1_nicht_erlaubt), 2=Cx2_kein_Fehler (CM_RGB_Slave_10_IntErrorRom_Cx2_kein_Fehler), 3=Cx3_Fehler (CM_RGB_Slave_10_IntErrorRom_Cx3_Fehler)}, range raw 0..3, transfer-property=PENDING, to SAM(timeout 3.5 s)  # Fehler im ROM
            signal RGB_Slave_10_IntErrorNvm_XIX_RGBs_Slave_10_XIX_E3V_SAM_LIN5: start 28, 2 bit, little-endian, data-type-policy=OVERRIDE, i-signal-type=PRIMITIVE, init-value=0, base-type=BT_RGB_Slave_10_IntErrorNvm, invalid-value=Invalid_RGB_Slave_10_IntErrorNvm_XIX_RGBs_Slave_10_XIX_E3V_SAM_LIN5:3, compu {0=Cx0_Init (CM_RGB_Slave_10_IntErrorNvm_Cx0_Init), 1=Cx1_nicht_erlaubt (CM_RGB_Slave_10_IntErrorNvm_Cx1_nicht_erlaubt), 2=Cx2_kein_Fehler (CM_RGB_Slave_10_IntErrorNvm_Cx2_kein_Fehler), 3=Cx3_Fehler (CM_RGB_Slave_10_IntErrorNvm_Cx3_Fehler)}, range raw 0..3, transfer-property=PENDING, to SAM(timeout 3.5 s)  # Fehler im NVM
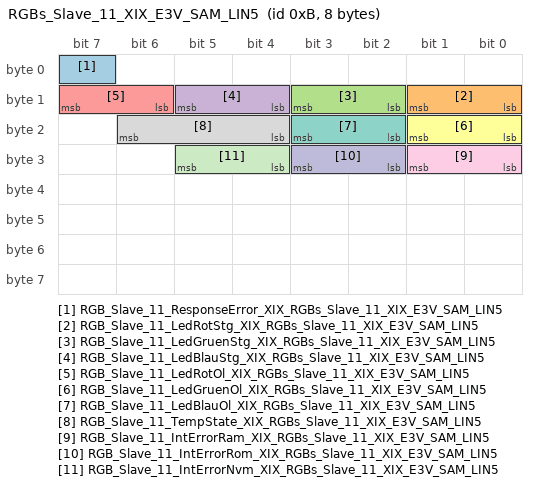
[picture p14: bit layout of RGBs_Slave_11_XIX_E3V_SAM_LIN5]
        frame RGBs_Slave_11_XIX_E3V_SAM_LIN5: id 0xB, to SAM, frame-length=8, lin-checksum=ENHANCED
          pdu RGBs_Slave_11_XIX_E3V_SAM_LIN5: length=8, unused-bit-pattern=0
            signal RGB_Slave_11_ResponseError_XIX_RGBs_Slave_11_XIX_E3V_SAM_LIN5: start 7, 1 bit, little-endian, data-type-policy=OVERRIDE, i-signal-type=PRIMITIVE, init-value=0, base-type=BT_RGB_Slave_11_ResponseError, invalid-value=Invalid_RGB_Slave_11_ResponseError_XIX_RGBs_Slave_11_XIX_E3V_SAM_LIN5:1, compu {0=Cx0_normal (CM_RGB_Slave_11_ResponseError_Cx0_normal), 1=Cx1_Fehler (CM_RGB_Slave_11_ResponseError_Cx1_Fehler)}, range raw 0..1, transfer-property=PENDING, to SAM(timeout 3.5 s)  # siehe LIN2.0-Specification (Darf nicht über ein Fehlergueltigkeitsbit abgesichtert werden!)
            signal RGB_Slave_11_LedRotStg_XIX_RGBs_Slave_11_XIX_E3V_SAM_LIN5: start 8, 2 bit, little-endian, data-type-policy=OVERRIDE, i-signal-type=PRIMITIVE, init-value=0, base-type=BT_RGB_Slave_11_LedRotStg, invalid-value=Invalid_RGB_Slave_11_LedRotStg_XIX_RGBs_Slave_11_XIX_E3V_SAM_LIN5:3, compu {0=Cx0_Init (CM_RGB_Slave_11_LedRotStg_Cx0_Init), 1=Cx1_nicht_erlaubt (CM_RGB_Slave_11_LedRotStg_Cx1_nicht_erlaubt), 2=Cx2_kein_Fehler (CM_RGB_Slave_11_LedRotStg_Cx2_kein_Fehler), 3=Cx3_Fehler (CM_RGB_Slave_11_LedRotStg_Cx3_Fehler)}, range raw 0..3, transfer-property=PENDING, to SAM(timeout 3.5 s)  # Short To Ground für Rote LED
            signal RGB_Slave_11_LedGruenStg_XIX_RGBs_Slave_11_XIX_E3V_SAM_LIN5: start 10, 2 bit, little-endian, data-type-policy=OVERRIDE, i-signal-type=PRIMITIVE, init-value=0, base-type=BT_RGB_Slave_11_LedGruenStg, invalid-value=Invalid_RGB_Slave_11_LedGruenStg_XIX_RGBs_Slave_11_XIX_E3V_SAM_LIN5:3, compu {0=Cx0_Init (CM_RGB_Slave_11_LedGruenStg_Cx0_Init), 1=Cx1_nicht_erlaubt (CM_RGB_Slave_11_LedGruenStg_Cx1_nicht_erlaubt), 2=Cx2_kein_Fehler (CM_RGB_Slave_11_LedGruenStg_Cx2_kein_Fehler), 3=Cx3_Fehler (CM_RGB_Slave_11_LedGruenStg_Cx3_Fehler)}, range raw 0..3, transfer-property=PENDING, to SAM(timeout 3.5 s)  # Short To Ground für Grüne LED
            signal RGB_Slave_11_LedBlauStg_XIX_RGBs_Slave_11_XIX_E3V_SAM_LIN5: start 12, 2 bit, little-endian, data-type-policy=OVERRIDE, i-signal-type=PRIMITIVE, init-value=0, base-type=BT_RGB_Slave_11_LedBlauStg, invalid-value=Invalid_RGB_Slave_11_LedBlauStg_XIX_RGBs_Slave_11_XIX_E3V_SAM_LIN5:3, compu {0=Cx0_Init (CM_RGB_Slave_11_LedBlauStg_Cx0_Init), 1=Cx1_nicht_erlaubt (CM_RGB_Slave_11_LedBlauStg_Cx1_nicht_erlaubt), 2=Cx2_kein_Fehler (CM_RGB_Slave_11_LedBlauStg_Cx2_kein_Fehler), 3=Cx3_Fehler (CM_RGB_Slave_11_LedBlauStg_Cx3_Fehler)}, range raw 0..3, transfer-property=PENDING, to SAM(timeout 3.5 s)  # Short To Ground für Blaue LED
            signal RGB_Slave_11_LedRotOl_XIX_RGBs_Slave_11_XIX_E3V_SAM_LIN5: start 14, 2 bit, little-endian, data-type-policy=OVERRIDE, i-signal-type=PRIMITIVE, init-value=0, base-type=BT_RGB_Slave_11_LedRotOl, invalid-value=Invalid_RGB_Slave_11_LedRotOl_XIX_RGBs_Slave_11_XIX_E3V_SAM_LIN5:3, compu {0=Cx0_Init (CM_RGB_Slave_11_LedRotOl_Cx0_Init), 1=Cx1_nicht_erlaubt (CM_RGB_Slave_11_LedRotOl_Cx1_nicht_erlaubt), 2=Cx2_kein_Fehler (CM_RGB_Slave_11_LedRotOl_Cx2_kein_Fehler), 3=Cx3_Fehler (CM_RGB_Slave_11_LedRotOl_Cx3_Fehler)}, range raw 0..3, transfer-property=PENDING, to SAM(timeout 3.5 s)  # OpenLoad für Rote LED
            signal RGB_Slave_11_LedGruenOl_XIX_RGBs_Slave_11_XIX_E3V_SAM_LIN5: start 16, 2 bit, little-endian, data-type-policy=OVERRIDE, i-signal-type=PRIMITIVE, init-value=0, base-type=BT_RGB_Slave_11_LedGruenOl, invalid-value=Invalid_RGB_Slave_11_LedGruenOl_XIX_RGBs_Slave_11_XIX_E3V_SAM_LIN5:3, compu {0=Cx0_Init (CM_RGB_Slave_11_LedGruenOl_Cx0_Init), 1=Cx1_nicht_erlaubt (CM_RGB_Slave_11_LedGruenOl_Cx1_nicht_erlaubt), 2=Cx2_kein_Fehler (CM_RGB_Slave_11_LedGruenOl_Cx2_kein_Fehler), 3=Cx3_Fehler (CM_RGB_Slave_11_LedGruenOl_Cx3_Fehler)}, range raw 0..3, transfer-property=PENDING, to SAM(timeout 3.5 s)  # OpenLoad für Rote LED
            signal RGB_Slave_11_LedBlauOl_XIX_RGBs_Slave_11_XIX_E3V_SAM_LIN5: start 18, 2 bit, little-endian, data-type-policy=OVERRIDE, i-signal-type=PRIMITIVE, init-value=0, base-type=BT_RGB_Slave_11_LedBlauOl, invalid-value=Invalid_RGB_Slave_11_LedBlauOl_XIX_RGBs_Slave_11_XIX_E3V_SAM_LIN5:3, compu {0=Cx0_Init (CM_RGB_Slave_11_LedBlauOl_Cx0_Init), 1=Cx1_nicht_erlaubt (CM_RGB_Slave_11_LedBlauOl_Cx1_nicht_erlaubt), 2=Cx2_kein_Fehler (CM_RGB_Slave_11_LedBlauOl_Cx2_kein_Fehler), 3=Cx3_Fehler (CM_RGB_Slave_11_LedBlauOl_Cx3_Fehler)}, range raw 0..3, transfer-property=PENDING, to SAM(timeout 3.5 s)  # OpenLoad für Blaue LED
            signal RGB_Slave_11_TempState_XIX_RGBs_Slave_11_XIX_E3V_SAM_LIN5: start 20, 3 bit, little-endian, data-type-policy=OVERRIDE, i-signal-type=PRIMITIVE, base-type=BT_RGB_Slave_11_TempState, compu {0=Cx0_keine_Temperaturregelung (CM_RGB_Slave_11_TempState_Cx0_keine_Temperaturregelung), 1=Cx1_Regelstufe_1 (CM_RGB_Slave_11_TempState_Cx1_Regelstufe_1), 2=Cx2_Regelstufe_2 (CM_RGB_Slave_11_TempState_Cx2_Regelstufe_2), 3=Cx3_Regelstufe_3 (CM_RGB_Slave_11_TempState_Cx3_Regelstufe_3), 4=Cx4_Regelstufe_4 (CM_RGB_Slave_11_TempState_Cx4_Regelstufe_4), 5=Cx5_Regelstufe_5 (CM_RGB_Slave_11_TempState_Cx5_Regelstufe_5), 6=Cx6_Regelstufe_6 (CM_RGB_Slave_11_TempState_Cx6_Regelstufe_6), 7=Cx7_Regelstufe_7 (CM_RGB_Slave_11_TempState_Cx7_Regelstufe_7)}, range raw 0..7, transfer-property=PENDING, to SAM(timeout 3.5 s)  # Status Temperaturregelung
            signal RGB_Slave_11_IntErrorRam_XIX_RGBs_Slave_11_XIX_E3V_SAM_LIN5: start 24, 2 bit, little-endian, data-type-policy=OVERRIDE, i-signal-type=PRIMITIVE, init-value=0, base-type=BT_RGB_Slave_11_IntErrorRam, invalid-value=Invalid_RGB_Slave_11_IntErrorRam_XIX_RGBs_Slave_11_XIX_E3V_SAM_LIN5:3, compu {0=Cx0_Init (CM_RGB_Slave_11_IntErrorRam_Cx0_Init), 1=Cx1_nicht_erlaubt (CM_RGB_Slave_11_IntErrorRam_Cx1_nicht_erlaubt), 2=Cx2_kein_Fehler (CM_RGB_Slave_11_IntErrorRam_Cx2_kein_Fehler), 3=Cx3_Fehler (CM_RGB_Slave_11_IntErrorRam_Cx3_Fehler)}, range raw 0..3, transfer-property=PENDING, to SAM(timeout 3.5 s)  # Fehler im RAM
            signal RGB_Slave_11_IntErrorRom_XIX_RGBs_Slave_11_XIX_E3V_SAM_LIN5: start 26, 2 bit, little-endian, data-type-policy=OVERRIDE, i-signal-type=PRIMITIVE, init-value=0, base-type=BT_RGB_Slave_11_IntErrorRom, invalid-value=Invalid_RGB_Slave_11_IntErrorRom_XIX_RGBs_Slave_11_XIX_E3V_SAM_LIN5:3, compu {0=Cx0_Init (CM_RGB_Slave_11_IntErrorRom_Cx0_Init), 1=Cx1_nicht_erlaubt (CM_RGB_Slave_11_IntErrorRom_Cx1_nicht_erlaubt), 2=Cx2_kein_Fehler (CM_RGB_Slave_11_IntErrorRom_Cx2_kein_Fehler), 3=Cx3_Fehler (CM_RGB_Slave_11_IntErrorRom_Cx3_Fehler)}, range raw 0..3, transfer-property=PENDING, to SAM(timeout 3.5 s)  # Fehler im ROM
            signal RGB_Slave_11_IntErrorNvm_XIX_RGBs_Slave_11_XIX_E3V_SAM_LIN5: start 28, 2 bit, little-endian, data-type-policy=OVERRIDE, i-signal-type=PRIMITIVE, init-value=0, base-type=BT_RGB_Slave_11_IntErrorNvm, invalid-value=Invalid_RGB_Slave_11_IntErrorNvm_XIX_RGBs_Slave_11_XIX_E3V_SAM_LIN5:3, compu {0=Cx0_Init (CM_RGB_Slave_11_IntErrorNvm_Cx0_Init), 1=Cx1_nicht_erlaubt (CM_RGB_Slave_11_IntErrorNvm_Cx1_nicht_erlaubt), 2=Cx2_kein_Fehler (CM_RGB_Slave_11_IntErrorNvm_Cx2_kein_Fehler), 3=Cx3_Fehler (CM_RGB_Slave_11_IntErrorNvm_Cx3_Fehler)}, range raw 0..3, transfer-property=PENDING, to SAM(timeout 3.5 s)  # Fehler im NVM
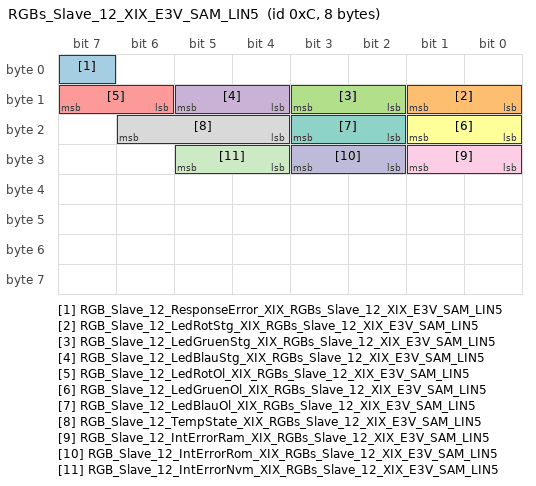
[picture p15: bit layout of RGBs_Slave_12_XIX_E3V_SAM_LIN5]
        frame RGBs_Slave_12_XIX_E3V_SAM_LIN5: id 0xC, to SAM, frame-length=8, lin-checksum=ENHANCED
          pdu RGBs_Slave_12_XIX_E3V_SAM_LIN5: length=8, unused-bit-pattern=0
            signal RGB_Slave_12_ResponseError_XIX_RGBs_Slave_12_XIX_E3V_SAM_LIN5: start 7, 1 bit, little-endian, data-type-policy=OVERRIDE, i-signal-type=PRIMITIVE, init-value=0, base-type=BT_RGB_Slave_12_ResponseError, invalid-value=Invalid_RGB_Slave_12_ResponseError_XIX_RGBs_Slave_12_XIX_E3V_SAM_LIN5:1, compu {0=Cx0_normal (CM_RGB_Slave_12_ResponseError_Cx0_normal), 1=Cx1_Fehler (CM_RGB_Slave_12_ResponseError_Cx1_Fehler)}, range raw 0..1, transfer-property=PENDING, to SAM(timeout 3.5 s)  # siehe LIN2.0-Specification (Darf nicht über ein Fehlergueltigkeitsbit abgesichtert werden!)
            signal RGB_Slave_12_LedRotStg_XIX_RGBs_Slave_12_XIX_E3V_SAM_LIN5: start 8, 2 bit, little-endian, data-type-policy=OVERRIDE, i-signal-type=PRIMITIVE, init-value=0, base-type=BT_RGB_Slave_12_LedRotStg, invalid-value=Invalid_RGB_Slave_12_LedRotStg_XIX_RGBs_Slave_12_XIX_E3V_SAM_LIN5:3, compu {0=Cx0_Init (CM_RGB_Slave_12_LedRotStg_Cx0_Init), 1=Cx1_nicht_erlaubt (CM_RGB_Slave_12_LedRotStg_Cx1_nicht_erlaubt), 2=Cx2_kein_Fehler (CM_RGB_Slave_12_LedRotStg_Cx2_kein_Fehler), 3=Cx3_Fehler (CM_RGB_Slave_12_LedRotStg_Cx3_Fehler)}, range raw 0..3, transfer-property=PENDING, to SAM(timeout 3.5 s)  # Short To Ground für Rote LED
            signal RGB_Slave_12_LedGruenStg_XIX_RGBs_Slave_12_XIX_E3V_SAM_LIN5: start 10, 2 bit, little-endian, data-type-policy=OVERRIDE, i-signal-type=PRIMITIVE, init-value=0, base-type=BT_RGB_Slave_12_LedGruenStg, invalid-value=Invalid_RGB_Slave_12_LedGruenStg_XIX_RGBs_Slave_12_XIX_E3V_SAM_LIN5:3, compu {0=Cx0_Init (CM_RGB_Slave_12_LedGruenStg_Cx0_Init), 1=Cx1_nicht_erlaubt (CM_RGB_Slave_12_LedGruenStg_Cx1_nicht_erlaubt), 2=Cx2_kein_Fehler (CM_RGB_Slave_12_LedGruenStg_Cx2_kein_Fehler), 3=Cx3_Fehler (CM_RGB_Slave_12_LedGruenStg_Cx3_Fehler)}, range raw 0..3, transfer-property=PENDING, to SAM(timeout 3.5 s)  # Short To Ground für Grüne LED
            signal RGB_Slave_12_LedBlauStg_XIX_RGBs_Slave_12_XIX_E3V_SAM_LIN5: start 12, 2 bit, little-endian, data-type-policy=OVERRIDE, i-signal-type=PRIMITIVE, init-value=0, base-type=BT_RGB_Slave_12_LedBlauStg, invalid-value=Invalid_RGB_Slave_12_LedBlauStg_XIX_RGBs_Slave_12_XIX_E3V_SAM_LIN5:3, compu {0=Cx0_Init (CM_RGB_Slave_12_LedBlauStg_Cx0_Init), 1=Cx1_nicht_erlaubt (CM_RGB_Slave_12_LedBlauStg_Cx1_nicht_erlaubt), 2=Cx2_kein_Fehler (CM_RGB_Slave_12_LedBlauStg_Cx2_kein_Fehler), 3=Cx3_Fehler (CM_RGB_Slave_12_LedBlauStg_Cx3_Fehler)}, range raw 0..3, transfer-property=PENDING, to SAM(timeout 3.5 s)  # Short To Ground für Blaue LED
            signal RGB_Slave_12_LedRotOl_XIX_RGBs_Slave_12_XIX_E3V_SAM_LIN5: start 14, 2 bit, little-endian, data-type-policy=OVERRIDE, i-signal-type=PRIMITIVE, init-value=0, base-type=BT_RGB_Slave_12_LedRotOl, invalid-value=Invalid_RGB_Slave_12_LedRotOl_XIX_RGBs_Slave_12_XIX_E3V_SAM_LIN5:3, compu {0=Cx0_Init (CM_RGB_Slave_12_LedRotOl_Cx0_Init), 1=Cx1_nicht_erlaubt (CM_RGB_Slave_12_LedRotOl_Cx1_nicht_erlaubt), 2=Cx2_kein_Fehler (CM_RGB_Slave_12_LedRotOl_Cx2_kein_Fehler), 3=Cx3_Fehler (CM_RGB_Slave_12_LedRotOl_Cx3_Fehler)}, range raw 0..3, transfer-property=PENDING, to SAM(timeout 3.5 s)  # OpenLoad für Rote LED
            signal RGB_Slave_12_LedGruenOl_XIX_RGBs_Slave_12_XIX_E3V_SAM_LIN5: start 16, 2 bit, little-endian, data-type-policy=OVERRIDE, i-signal-type=PRIMITIVE, init-value=0, base-type=BT_RGB_Slave_12_LedGruenOl, invalid-value=Invalid_RGB_Slave_12_LedGruenOl_XIX_RGBs_Slave_12_XIX_E3V_SAM_LIN5:3, compu {0=Cx0_Init (CM_RGB_Slave_12_LedGruenOl_Cx0_Init), 1=Cx1_nicht_erlaubt (CM_RGB_Slave_12_LedGruenOl_Cx1_nicht_erlaubt), 2=Cx2_kein_Fehler (CM_RGB_Slave_12_LedGruenOl_Cx2_kein_Fehler), 3=Cx3_Fehler (CM_RGB_Slave_12_LedGruenOl_Cx3_Fehler)}, range raw 0..3, transfer-property=PENDING, to SAM(timeout 3.5 s)  # OpenLoad für Rote LED
            signal RGB_Slave_12_LedBlauOl_XIX_RGBs_Slave_12_XIX_E3V_SAM_LIN5: start 18, 2 bit, little-endian, data-type-policy=OVERRIDE, i-signal-type=PRIMITIVE, init-value=0, base-type=BT_RGB_Slave_12_LedBlauOl, invalid-value=Invalid_RGB_Slave_12_LedBlauOl_XIX_RGBs_Slave_12_XIX_E3V_SAM_LIN5:3, compu {0=Cx0_Init (CM_RGB_Slave_12_LedBlauOl_Cx0_Init), 1=Cx1_nicht_erlaubt (CM_RGB_Slave_12_LedBlauOl_Cx1_nicht_erlaubt), 2=Cx2_kein_Fehler (CM_RGB_Slave_12_LedBlauOl_Cx2_kein_Fehler), 3=Cx3_Fehler (CM_RGB_Slave_12_LedBlauOl_Cx3_Fehler)}, range raw 0..3, transfer-property=PENDING, to SAM(timeout 3.5 s)  # OpenLoad für Blaue LED
            signal RGB_Slave_12_TempState_XIX_RGBs_Slave_12_XIX_E3V_SAM_LIN5: start 20, 3 bit, little-endian, data-type-policy=OVERRIDE, i-signal-type=PRIMITIVE, base-type=BT_RGB_Slave_12_TempState, compu {0=Cx0_keine_Temperaturregelung (CM_RGB_Slave_12_TempState_Cx0_keine_Temperaturregelung), 1=Cx1_Regelstufe_1 (CM_RGB_Slave_12_TempState_Cx1_Regelstufe_1), 2=Cx2_Regelstufe_2 (CM_RGB_Slave_12_TempState_Cx2_Regelstufe_2), 3=Cx3_Regelstufe_3 (CM_RGB_Slave_12_TempState_Cx3_Regelstufe_3), 4=Cx4_Regelstufe_4 (CM_RGB_Slave_12_TempState_Cx4_Regelstufe_4), 5=Cx5_Regelstufe_5 (CM_RGB_Slave_12_TempState_Cx5_Regelstufe_5), 6=Cx6_Regelstufe_6 (CM_RGB_Slave_12_TempState_Cx6_Regelstufe_6), 7=Cx7_Regelstufe_7 (CM_RGB_Slave_12_TempState_Cx7_Regelstufe_7)}, range raw 0..7, transfer-property=PENDING, to SAM(timeout 3.5 s)  # Status Temperaturregelung
            signal RGB_Slave_12_IntErrorRam_XIX_RGBs_Slave_12_XIX_E3V_SAM_LIN5: start 24, 2 bit, little-endian, data-type-policy=OVERRIDE, i-signal-type=PRIMITIVE, init-value=0, base-type=BT_RGB_Slave_12_IntErrorRam, invalid-value=Invalid_RGB_Slave_12_IntErrorRam_XIX_RGBs_Slave_12_XIX_E3V_SAM_LIN5:3, compu {0=Cx0_Init (CM_RGB_Slave_12_IntErrorRam_Cx0_Init), 1=Cx1_nicht_erlaubt (CM_RGB_Slave_12_IntErrorRam_Cx1_nicht_erlaubt), 2=Cx2_kein_Fehler (CM_RGB_Slave_12_IntErrorRam_Cx2_kein_Fehler), 3=Cx3_Fehler (CM_RGB_Slave_12_IntErrorRam_Cx3_Fehler)}, range raw 0..3, transfer-property=PENDING, to SAM(timeout 3.5 s)  # Fehler im RAM
            signal RGB_Slave_12_IntErrorRom_XIX_RGBs_Slave_12_XIX_E3V_SAM_LIN5: start 26, 2 bit, little-endian, data-type-policy=OVERRIDE, i-signal-type=PRIMITIVE, init-value=0, base-type=BT_RGB_Slave_12_IntErrorRom, invalid-value=Invalid_RGB_Slave_12_IntErrorRom_XIX_RGBs_Slave_12_XIX_E3V_SAM_LIN5:3, compu {0=Cx0_Init (CM_RGB_Slave_12_IntErrorRom_Cx0_Init), 1=Cx1_nicht_erlaubt (CM_RGB_Slave_12_IntErrorRom_Cx1_nicht_erlaubt), 2=Cx2_kein_Fehler (CM_RGB_Slave_12_IntErrorRom_Cx2_kein_Fehler), 3=Cx3_Fehler (CM_RGB_Slave_12_IntErrorRom_Cx3_Fehler)}, range raw 0..3, transfer-property=PENDING, to SAM(timeout 3.5 s)  # Fehler im ROM
            signal RGB_Slave_12_IntErrorNvm_XIX_RGBs_Slave_12_XIX_E3V_SAM_LIN5: start 28, 2 bit, little-endian, data-type-policy=OVERRIDE, i-signal-type=PRIMITIVE, init-value=0, base-type=BT_RGB_Slave_12_IntErrorNvm, invalid-value=Invalid_RGB_Slave_12_IntErrorNvm_XIX_RGBs_Slave_12_XIX_E3V_SAM_LIN5:3, compu {0=Cx0_Init (CM_RGB_Slave_12_IntErrorNvm_Cx0_Init), 1=Cx1_nicht_erlaubt (CM_RGB_Slave_12_IntErrorNvm_Cx1_nicht_erlaubt), 2=Cx2_kein_Fehler (CM_RGB_Slave_12_IntErrorNvm_Cx2_kein_Fehler), 3=Cx3_Fehler (CM_RGB_Slave_12_IntErrorNvm_Cx3_Fehler)}, range raw 0..3, transfer-property=PENDING, to SAM(timeout 3.5 s)  # Fehler im NVM
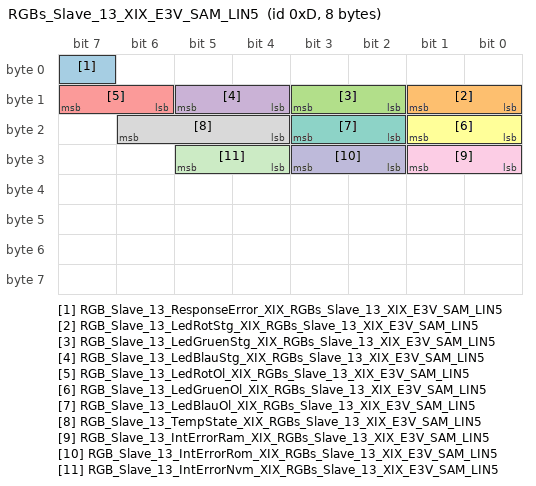
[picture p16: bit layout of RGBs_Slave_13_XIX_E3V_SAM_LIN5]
        frame RGBs_Slave_13_XIX_E3V_SAM_LIN5: id 0xD, to SAM, frame-length=8, lin-checksum=ENHANCED
          pdu RGBs_Slave_13_XIX_E3V_SAM_LIN5: length=8, unused-bit-pattern=0
            signal RGB_Slave_13_ResponseError_XIX_RGBs_Slave_13_XIX_E3V_SAM_LIN5: start 7, 1 bit, little-endian, data-type-policy=OVERRIDE, i-signal-type=PRIMITIVE, init-value=0, base-type=BT_RGB_Slave_13_ResponseError, invalid-value=Invalid_RGB_Slave_13_ResponseError_XIX_RGBs_Slave_13_XIX_E3V_SAM_LIN5:1, compu {0=Cx0_normal (CM_RGB_Slave_13_ResponseError_Cx0_normal), 1=Cx1_Fehler (CM_RGB_Slave_13_ResponseError_Cx1_Fehler)}, range raw 0..1, transfer-property=PENDING, to SAM(timeout 3.5 s)  # siehe LIN2.0-Specification (Darf nicht über ein Fehlergueltigkeitsbit abgesichtert werden!)
            signal RGB_Slave_13_LedRotStg_XIX_RGBs_Slave_13_XIX_E3V_SAM_LIN5: start 8, 2 bit, little-endian, data-type-policy=OVERRIDE, i-signal-type=PRIMITIVE, init-value=0, base-type=BT_RGB_Slave_13_LedRotStg, invalid-value=Invalid_RGB_Slave_13_LedRotStg_XIX_RGBs_Slave_13_XIX_E3V_SAM_LIN5:3, compu {0=Cx0_Init (CM_RGB_Slave_13_LedRotStg_Cx0_Init), 1=Cx1_nicht_erlaubt (CM_RGB_Slave_13_LedRotStg_Cx1_nicht_erlaubt), 2=Cx2_kein_Fehler (CM_RGB_Slave_13_LedRotStg_Cx2_kein_Fehler), 3=Cx3_Fehler (CM_RGB_Slave_13_LedRotStg_Cx3_Fehler)}, range raw 0..3, transfer-property=PENDING, to SAM(timeout 3.5 s)  # Short To Ground für Rote LED
            signal RGB_Slave_13_LedGruenStg_XIX_RGBs_Slave_13_XIX_E3V_SAM_LIN5: start 10, 2 bit, little-endian, data-type-policy=OVERRIDE, i-signal-type=PRIMITIVE, init-value=0, base-type=BT_RGB_Slave_13_LedGruenStg, invalid-value=Invalid_RGB_Slave_13_LedGruenStg_XIX_RGBs_Slave_13_XIX_E3V_SAM_LIN5:3, compu {0=Cx0_Init (CM_RGB_Slave_13_LedGruenStg_Cx0_Init), 1=Cx1_nicht_erlaubt (CM_RGB_Slave_13_LedGruenStg_Cx1_nicht_erlaubt), 2=Cx2_kein_Fehler (CM_RGB_Slave_13_LedGruenStg_Cx2_kein_Fehler), 3=Cx3_Fehler (CM_RGB_Slave_13_LedGruenStg_Cx3_Fehler)}, range raw 0..3, transfer-property=PENDING, to SAM(timeout 3.5 s)  # Short To Ground für Grüne LED
            signal RGB_Slave_13_LedBlauStg_XIX_RGBs_Slave_13_XIX_E3V_SAM_LIN5: start 12, 2 bit, little-endian, data-type-policy=OVERRIDE, i-signal-type=PRIMITIVE, init-value=0, base-type=BT_RGB_Slave_13_LedBlauStg, invalid-value=Invalid_RGB_Slave_13_LedBlauStg_XIX_RGBs_Slave_13_XIX_E3V_SAM_LIN5:3, compu {0=Cx0_Init (CM_RGB_Slave_13_LedBlauStg_Cx0_Init), 1=Cx1_nicht_erlaubt (CM_RGB_Slave_13_LedBlauStg_Cx1_nicht_erlaubt), 2=Cx2_kein_Fehler (CM_RGB_Slave_13_LedBlauStg_Cx2_kein_Fehler), 3=Cx3_Fehler (CM_RGB_Slave_13_LedBlauStg_Cx3_Fehler)}, range raw 0..3, transfer-property=PENDING, to SAM(timeout 3.5 s)  # Short To Ground für Blaue LED
            signal RGB_Slave_13_LedRotOl_XIX_RGBs_Slave_13_XIX_E3V_SAM_LIN5: start 14, 2 bit, little-endian, data-type-policy=OVERRIDE, i-signal-type=PRIMITIVE, init-value=0, base-type=BT_RGB_Slave_13_LedRotOl, invalid-value=Invalid_RGB_Slave_13_LedRotOl_XIX_RGBs_Slave_13_XIX_E3V_SAM_LIN5:3, compu {0=Cx0_Init (CM_RGB_Slave_13_LedRotOl_Cx0_Init), 1=Cx1_nicht_erlaubt (CM_RGB_Slave_13_LedRotOl_Cx1_nicht_erlaubt), 2=Cx2_kein_Fehler (CM_RGB_Slave_13_LedRotOl_Cx2_kein_Fehler), 3=Cx3_Fehler (CM_RGB_Slave_13_LedRotOl_Cx3_Fehler)}, range raw 0..3, transfer-property=PENDING, to SAM(timeout 3.5 s)  # OpenLoad für Rote LED
            signal RGB_Slave_13_LedGruenOl_XIX_RGBs_Slave_13_XIX_E3V_SAM_LIN5: start 16, 2 bit, little-endian, data-type-policy=OVERRIDE, i-signal-type=PRIMITIVE, init-value=0, base-type=BT_RGB_Slave_13_LedGruenOl, invalid-value=Invalid_RGB_Slave_13_LedGruenOl_XIX_RGBs_Slave_13_XIX_E3V_SAM_LIN5:3, compu {0=Cx0_Init (CM_RGB_Slave_13_LedGruenOl_Cx0_Init), 1=Cx1_nicht_erlaubt (CM_RGB_Slave_13_LedGruenOl_Cx1_nicht_erlaubt), 2=Cx2_kein_Fehler (CM_RGB_Slave_13_LedGruenOl_Cx2_kein_Fehler), 3=Cx3_Fehler (CM_RGB_Slave_13_LedGruenOl_Cx3_Fehler)}, range raw 0..3, transfer-property=PENDING, to SAM(timeout 3.5 s)  # OpenLoad für Rote LED
            signal RGB_Slave_13_LedBlauOl_XIX_RGBs_Slave_13_XIX_E3V_SAM_LIN5: start 18, 2 bit, little-endian, data-type-policy=OVERRIDE, i-signal-type=PRIMITIVE, init-value=0, base-type=BT_RGB_Slave_13_LedBlauOl, invalid-value=Invalid_RGB_Slave_13_LedBlauOl_XIX_RGBs_Slave_13_XIX_E3V_SAM_LIN5:3, compu {0=Cx0_Init (CM_RGB_Slave_13_LedBlauOl_Cx0_Init), 1=Cx1_nicht_erlaubt (CM_RGB_Slave_13_LedBlauOl_Cx1_nicht_erlaubt), 2=Cx2_kein_Fehler (CM_RGB_Slave_13_LedBlauOl_Cx2_kein_Fehler), 3=Cx3_Fehler (CM_RGB_Slave_13_LedBlauOl_Cx3_Fehler)}, range raw 0..3, transfer-property=PENDING, to SAM(timeout 3.5 s)  # OpenLoad für Blaue LED
            signal RGB_Slave_13_TempState_XIX_RGBs_Slave_13_XIX_E3V_SAM_LIN5: start 20, 3 bit, little-endian, data-type-policy=OVERRIDE, i-signal-type=PRIMITIVE, base-type=BT_RGB_Slave_13_TempState, compu {0=Cx0_keine_Temperaturregelung (CM_RGB_Slave_13_TempState_Cx0_keine_Temperaturregelung), 1=Cx1_Regelstufe_1 (CM_RGB_Slave_13_TempState_Cx1_Regelstufe_1), 2=Cx2_Regelstufe_2 (CM_RGB_Slave_13_TempState_Cx2_Regelstufe_2), 3=Cx3_Regelstufe_3 (CM_RGB_Slave_13_TempState_Cx3_Regelstufe_3), 4=Cx4_Regelstufe_4 (CM_RGB_Slave_13_TempState_Cx4_Regelstufe_4), 5=Cx5_Regelstufe_5 (CM_RGB_Slave_13_TempState_Cx5_Regelstufe_5), 6=Cx6_Regelstufe_6 (CM_RGB_Slave_13_TempState_Cx6_Regelstufe_6), 7=Cx7_Regelstufe_7 (CM_RGB_Slave_13_TempState_Cx7_Regelstufe_7)}, range raw 0..7, transfer-property=PENDING, to SAM(timeout 3.5 s)  # Status Temperaturregelung
            signal RGB_Slave_13_IntErrorRam_XIX_RGBs_Slave_13_XIX_E3V_SAM_LIN5: start 24, 2 bit, little-endian, data-type-policy=OVERRIDE, i-signal-type=PRIMITIVE, init-value=0, base-type=BT_RGB_Slave_13_IntErrorRam, invalid-value=Invalid_RGB_Slave_13_IntErrorRam_XIX_RGBs_Slave_13_XIX_E3V_SAM_LIN5:3, compu {0=Cx0_Init (CM_RGB_Slave_13_IntErrorRam_Cx0_Init), 1=Cx1_nicht_erlaubt (CM_RGB_Slave_13_IntErrorRam_Cx1_nicht_erlaubt), 2=Cx2_kein_Fehler (CM_RGB_Slave_13_IntErrorRam_Cx2_kein_Fehler), 3=Cx3_Fehler (CM_RGB_Slave_13_IntErrorRam_Cx3_Fehler)}, range raw 0..3, transfer-property=PENDING, to SAM(timeout 3.5 s)  # Fehler im RAM
            signal RGB_Slave_13_IntErrorRom_XIX_RGBs_Slave_13_XIX_E3V_SAM_LIN5: start 26, 2 bit, little-endian, data-type-policy=OVERRIDE, i-signal-type=PRIMITIVE, init-value=0, base-type=BT_RGB_Slave_13_IntErrorRom, invalid-value=Invalid_RGB_Slave_13_IntErrorRom_XIX_RGBs_Slave_13_XIX_E3V_SAM_LIN5:3, compu {0=Cx0_Init (CM_RGB_Slave_13_IntErrorRom_Cx0_Init), 1=Cx1_nicht_erlaubt (CM_RGB_Slave_13_IntErrorRom_Cx1_nicht_erlaubt), 2=Cx2_kein_Fehler (CM_RGB_Slave_13_IntErrorRom_Cx2_kein_Fehler), 3=Cx3_Fehler (CM_RGB_Slave_13_IntErrorRom_Cx3_Fehler)}, range raw 0..3, transfer-property=PENDING, to SAM(timeout 3.5 s)  # Fehler im ROM
            signal RGB_Slave_13_IntErrorNvm_XIX_RGBs_Slave_13_XIX_E3V_SAM_LIN5: start 28, 2 bit, little-endian, data-type-policy=OVERRIDE, i-signal-type=PRIMITIVE, init-value=0, base-type=BT_RGB_Slave_13_IntErrorNvm, invalid-value=Invalid_RGB_Slave_13_IntErrorNvm_XIX_RGBs_Slave_13_XIX_E3V_SAM_LIN5:3, compu {0=Cx0_Init (CM_RGB_Slave_13_IntErrorNvm_Cx0_Init), 1=Cx1_nicht_erlaubt (CM_RGB_Slave_13_IntErrorNvm_Cx1_nicht_erlaubt), 2=Cx2_kein_Fehler (CM_RGB_Slave_13_IntErrorNvm_Cx2_kein_Fehler), 3=Cx3_Fehler (CM_RGB_Slave_13_IntErrorNvm_Cx3_Fehler)}, range raw 0..3, transfer-property=PENDING, to SAM(timeout 3.5 s)  # Fehler im NVM
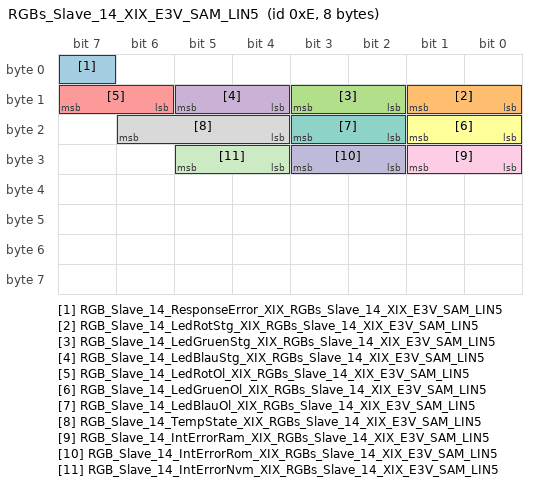
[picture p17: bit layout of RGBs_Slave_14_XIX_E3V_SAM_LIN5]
        frame RGBs_Slave_14_XIX_E3V_SAM_LIN5: id 0xE, to SAM, frame-length=8, lin-checksum=ENHANCED
          pdu RGBs_Slave_14_XIX_E3V_SAM_LIN5: length=8, unused-bit-pattern=0
            signal RGB_Slave_14_ResponseError_XIX_RGBs_Slave_14_XIX_E3V_SAM_LIN5: start 7, 1 bit, little-endian, data-type-policy=OVERRIDE, i-signal-type=PRIMITIVE, init-value=0, base-type=BT_RGB_Slave_14_ResponseError, invalid-value=Invalid_RGB_Slave_14_ResponseError_XIX_RGBs_Slave_14_XIX_E3V_SAM_LIN5:1, compu {0=Cx0_normal (CM_RGB_Slave_14_ResponseError_Cx0_normal), 1=Cx1_Fehler (CM_RGB_Slave_14_ResponseError_Cx1_Fehler)}, range raw 0..1, transfer-property=PENDING, to SAM(timeout 3.5 s)  # siehe LIN2.0-Specification (Darf nicht über ein Fehlergueltigkeitsbit abgesichtert werden!)
            signal RGB_Slave_14_LedRotStg_XIX_RGBs_Slave_14_XIX_E3V_SAM_LIN5: start 8, 2 bit, little-endian, data-type-policy=OVERRIDE, i-signal-type=PRIMITIVE, init-value=0, base-type=BT_RGB_Slave_14_LedRotStg, invalid-value=Invalid_RGB_Slave_14_LedRotStg_XIX_RGBs_Slave_14_XIX_E3V_SAM_LIN5:3, compu {0=Cx0_Init (CM_RGB_Slave_14_LedRotStg_Cx0_Init), 1=Cx1_nicht_erlaubt (CM_RGB_Slave_14_LedRotStg_Cx1_nicht_erlaubt), 2=Cx2_kein_Fehler (CM_RGB_Slave_14_LedRotStg_Cx2_kein_Fehler), 3=Cx3_Fehler (CM_RGB_Slave_14_LedRotStg_Cx3_Fehler)}, range raw 0..3, transfer-property=PENDING, to SAM(timeout 3.5 s)  # Short To Ground für Rote LED
            signal RGB_Slave_14_LedGruenStg_XIX_RGBs_Slave_14_XIX_E3V_SAM_LIN5: start 10, 2 bit, little-endian, data-type-policy=OVERRIDE, i-signal-type=PRIMITIVE, init-value=0, base-type=BT_RGB_Slave_14_LedGruenStg, invalid-value=Invalid_RGB_Slave_14_LedGruenStg_XIX_RGBs_Slave_14_XIX_E3V_SAM_LIN5:3, compu {0=Cx0_Init (CM_RGB_Slave_14_LedGruenStg_Cx0_Init), 1=Cx1_nicht_erlaubt (CM_RGB_Slave_14_LedGruenStg_Cx1_nicht_erlaubt), 2=Cx2_kein_Fehler (CM_RGB_Slave_14_LedGruenStg_Cx2_kein_Fehler), 3=Cx3_Fehler (CM_RGB_Slave_14_LedGruenStg_Cx3_Fehler)}, range raw 0..3, transfer-property=PENDING, to SAM(timeout 3.5 s)  # Short To Ground für Grüne LED
            signal RGB_Slave_14_LedBlauStg_XIX_RGBs_Slave_14_XIX_E3V_SAM_LIN5: start 12, 2 bit, little-endian, data-type-policy=OVERRIDE, i-signal-type=PRIMITIVE, init-value=0, base-type=BT_RGB_Slave_14_LedBlauStg, invalid-value=Invalid_RGB_Slave_14_LedBlauStg_XIX_RGBs_Slave_14_XIX_E3V_SAM_LIN5:3, compu {0=Cx0_Init (CM_RGB_Slave_14_LedBlauStg_Cx0_Init), 1=Cx1_nicht_erlaubt (CM_RGB_Slave_14_LedBlauStg_Cx1_nicht_erlaubt), 2=Cx2_kein_Fehler (CM_RGB_Slave_14_LedBlauStg_Cx2_kein_Fehler), 3=Cx3_Fehler (CM_RGB_Slave_14_LedBlauStg_Cx3_Fehler)}, range raw 0..3, transfer-property=PENDING, to SAM(timeout 3.5 s)  # Short To Ground für Blaue LED
            signal RGB_Slave_14_LedRotOl_XIX_RGBs_Slave_14_XIX_E3V_SAM_LIN5: start 14, 2 bit, little-endian, data-type-policy=OVERRIDE, i-signal-type=PRIMITIVE, init-value=0, base-type=BT_RGB_Slave_14_LedRotOl, invalid-value=Invalid_RGB_Slave_14_LedRotOl_XIX_RGBs_Slave_14_XIX_E3V_SAM_LIN5:3, compu {0=Cx0_Init (CM_RGB_Slave_14_LedRotOl_Cx0_Init), 1=Cx1_nicht_erlaubt (CM_RGB_Slave_14_LedRotOl_Cx1_nicht_erlaubt), 2=Cx2_kein_Fehler (CM_RGB_Slave_14_LedRotOl_Cx2_kein_Fehler), 3=Cx3_Fehler (CM_RGB_Slave_14_LedRotOl_Cx3_Fehler)}, range raw 0..3, transfer-property=PENDING, to SAM(timeout 3.5 s)  # OpenLoad für Rote LED
            signal RGB_Slave_14_LedGruenOl_XIX_RGBs_Slave_14_XIX_E3V_SAM_LIN5: start 16, 2 bit, little-endian, data-type-policy=OVERRIDE, i-signal-type=PRIMITIVE, init-value=0, base-type=BT_RGB_Slave_14_LedGruenOl, invalid-value=Invalid_RGB_Slave_14_LedGruenOl_XIX_RGBs_Slave_14_XIX_E3V_SAM_LIN5:3, compu {0=Cx0_Init (CM_RGB_Slave_14_LedGruenOl_Cx0_Init), 1=Cx1_nicht_erlaubt (CM_RGB_Slave_14_LedGruenOl_Cx1_nicht_erlaubt), 2=Cx2_kein_Fehler (CM_RGB_Slave_14_LedGruenOl_Cx2_kein_Fehler), 3=Cx3_Fehler (CM_RGB_Slave_14_LedGruenOl_Cx3_Fehler)}, range raw 0..3, transfer-property=PENDING, to SAM(timeout 3.5 s)  # OpenLoad für Rote LED
            signal RGB_Slave_14_LedBlauOl_XIX_RGBs_Slave_14_XIX_E3V_SAM_LIN5: start 18, 2 bit, little-endian, data-type-policy=OVERRIDE, i-signal-type=PRIMITIVE, init-value=0, base-type=BT_RGB_Slave_14_LedBlauOl, invalid-value=Invalid_RGB_Slave_14_LedBlauOl_XIX_RGBs_Slave_14_XIX_E3V_SAM_LIN5:3, compu {0=Cx0_Init (CM_RGB_Slave_14_LedBlauOl_Cx0_Init), 1=Cx1_nicht_erlaubt (CM_RGB_Slave_14_LedBlauOl_Cx1_nicht_erlaubt), 2=Cx2_kein_Fehler (CM_RGB_Slave_14_LedBlauOl_Cx2_kein_Fehler), 3=Cx3_Fehler (CM_RGB_Slave_14_LedBlauOl_Cx3_Fehler)}, range raw 0..3, transfer-property=PENDING, to SAM(timeout 3.5 s)  # OpenLoad für Blaue LED
            signal RGB_Slave_14_TempState_XIX_RGBs_Slave_14_XIX_E3V_SAM_LIN5: start 20, 3 bit, little-endian, data-type-policy=OVERRIDE, i-signal-type=PRIMITIVE, base-type=BT_RGB_Slave_14_TempState, compu {0=Cx0_keine_Temperaturregelung (CM_RGB_Slave_14_TempState_Cx0_keine_Temperaturregelung), 1=Cx1_Regelstufe_1 (CM_RGB_Slave_14_TempState_Cx1_Regelstufe_1), 2=Cx2_Regelstufe_2 (CM_RGB_Slave_14_TempState_Cx2_Regelstufe_2), 3=Cx3_Regelstufe_3 (CM_RGB_Slave_14_TempState_Cx3_Regelstufe_3), 4=Cx4_Regelstufe_4 (CM_RGB_Slave_14_TempState_Cx4_Regelstufe_4), 5=Cx5_Regelstufe_5 (CM_RGB_Slave_14_TempState_Cx5_Regelstufe_5), 6=Cx6_Regelstufe_6 (CM_RGB_Slave_14_TempState_Cx6_Regelstufe_6), 7=Cx7_Regelstufe_7 (CM_RGB_Slave_14_TempState_Cx7_Regelstufe_7)}, range raw 0..7, transfer-property=PENDING, to SAM(timeout 3.5 s)  # Status Temperaturregelung
            signal RGB_Slave_14_IntErrorRam_XIX_RGBs_Slave_14_XIX_E3V_SAM_LIN5: start 24, 2 bit, little-endian, data-type-policy=OVERRIDE, i-signal-type=PRIMITIVE, init-value=0, base-type=BT_RGB_Slave_14_IntErrorRam, invalid-value=Invalid_RGB_Slave_14_IntErrorRam_XIX_RGBs_Slave_14_XIX_E3V_SAM_LIN5:3, compu {0=Cx0_Init (CM_RGB_Slave_14_IntErrorRam_Cx0_Init), 1=Cx1_nicht_erlaubt (CM_RGB_Slave_14_IntErrorRam_Cx1_nicht_erlaubt), 2=Cx2_kein_Fehler (CM_RGB_Slave_14_IntErrorRam_Cx2_kein_Fehler), 3=Cx3_Fehler (CM_RGB_Slave_14_IntErrorRam_Cx3_Fehler)}, range raw 0..3, transfer-property=PENDING, to SAM(timeout 3.5 s)  # Fehler im RAM
            signal RGB_Slave_14_IntErrorRom_XIX_RGBs_Slave_14_XIX_E3V_SAM_LIN5: start 26, 2 bit, little-endian, data-type-policy=OVERRIDE, i-signal-type=PRIMITIVE, init-value=0, base-type=BT_RGB_Slave_14_IntErrorRom, invalid-value=Invalid_RGB_Slave_14_IntErrorRom_XIX_RGBs_Slave_14_XIX_E3V_SAM_LIN5:3, compu {0=Cx0_Init (CM_RGB_Slave_14_IntErrorRom_Cx0_Init), 1=Cx1_nicht_erlaubt (CM_RGB_Slave_14_IntErrorRom_Cx1_nicht_erlaubt), 2=Cx2_kein_Fehler (CM_RGB_Slave_14_IntErrorRom_Cx2_kein_Fehler), 3=Cx3_Fehler (CM_RGB_Slave_14_IntErrorRom_Cx3_Fehler)}, range raw 0..3, transfer-property=PENDING, to SAM(timeout 3.5 s)  # Fehler im ROM
            signal RGB_Slave_14_IntErrorNvm_XIX_RGBs_Slave_14_XIX_E3V_SAM_LIN5: start 28, 2 bit, little-endian, data-type-policy=OVERRIDE, i-signal-type=PRIMITIVE, init-value=0, base-type=BT_RGB_Slave_14_IntErrorNvm, invalid-value=Invalid_RGB_Slave_14_IntErrorNvm_XIX_RGBs_Slave_14_XIX_E3V_SAM_LIN5:3, compu {0=Cx0_Init (CM_RGB_Slave_14_IntErrorNvm_Cx0_Init), 1=Cx1_nicht_erlaubt (CM_RGB_Slave_14_IntErrorNvm_Cx1_nicht_erlaubt), 2=Cx2_kein_Fehler (CM_RGB_Slave_14_IntErrorNvm_Cx2_kein_Fehler), 3=Cx3_Fehler (CM_RGB_Slave_14_IntErrorNvm_Cx3_Fehler)}, range raw 0..3, transfer-property=PENDING, to SAM(timeout 3.5 s)  # Fehler im NVM
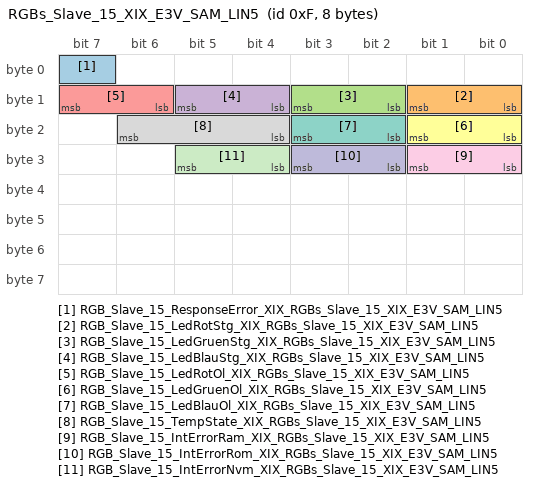
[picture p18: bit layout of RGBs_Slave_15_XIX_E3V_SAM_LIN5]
        frame RGBs_Slave_15_XIX_E3V_SAM_LIN5: id 0xF, to SAM, frame-length=8, lin-checksum=ENHANCED
          pdu RGBs_Slave_15_XIX_E3V_SAM_LIN5: length=8, unused-bit-pattern=0
            signal RGB_Slave_15_ResponseError_XIX_RGBs_Slave_15_XIX_E3V_SAM_LIN5: start 7, 1 bit, little-endian, data-type-policy=OVERRIDE, i-signal-type=PRIMITIVE, init-value=0, base-type=BT_RGB_Slave_15_ResponseError, invalid-value=Invalid_RGB_Slave_15_ResponseError_XIX_RGBs_Slave_15_XIX_E3V_SAM_LIN5:1, compu {0=Cx0_normal (CM_RGB_Slave_15_ResponseError_Cx0_normal), 1=Cx1_Fehler (CM_RGB_Slave_15_ResponseError_Cx1_Fehler)}, range raw 0..1, transfer-property=PENDING, to SAM(timeout 3.5 s)  # siehe LIN2.0-Specification (Darf nicht über ein Fehlergueltigkeitsbit abgesichtert werden!)
            signal RGB_Slave_15_LedRotStg_XIX_RGBs_Slave_15_XIX_E3V_SAM_LIN5: start 8, 2 bit, little-endian, data-type-policy=OVERRIDE, i-signal-type=PRIMITIVE, init-value=0, base-type=BT_RGB_Slave_15_LedRotStg, invalid-value=Invalid_RGB_Slave_15_LedRotStg_XIX_RGBs_Slave_15_XIX_E3V_SAM_LIN5:3, compu {0=Cx0_Init (CM_RGB_Slave_15_LedRotStg_Cx0_Init), 1=Cx1_nicht_erlaubt (CM_RGB_Slave_15_LedRotStg_Cx1_nicht_erlaubt), 2=Cx2_kein_Fehler (CM_RGB_Slave_15_LedRotStg_Cx2_kein_Fehler), 3=Cx3_Fehler (CM_RGB_Slave_15_LedRotStg_Cx3_Fehler)}, range raw 0..3, transfer-property=PENDING, to SAM(timeout 3.5 s)  # Short To Ground für Rote LED
            signal RGB_Slave_15_LedGruenStg_XIX_RGBs_Slave_15_XIX_E3V_SAM_LIN5: start 10, 2 bit, little-endian, data-type-policy=OVERRIDE, i-signal-type=PRIMITIVE, init-value=0, base-type=BT_RGB_Slave_15_LedGruenStg, invalid-value=Invalid_RGB_Slave_15_LedGruenStg_XIX_RGBs_Slave_15_XIX_E3V_SAM_LIN5:3, compu {0=Cx0_Init (CM_RGB_Slave_15_LedGruenStg_Cx0_Init), 1=Cx1_nicht_erlaubt (CM_RGB_Slave_15_LedGruenStg_Cx1_nicht_erlaubt), 2=Cx2_kein_Fehler (CM_RGB_Slave_15_LedGruenStg_Cx2_kein_Fehler), 3=Cx3_Fehler (CM_RGB_Slave_15_LedGruenStg_Cx3_Fehler)}, range raw 0..3, transfer-property=PENDING, to SAM(timeout 3.5 s)  # Short To Ground für Grüne LED
            signal RGB_Slave_15_LedBlauStg_XIX_RGBs_Slave_15_XIX_E3V_SAM_LIN5: start 12, 2 bit, little-endian, data-type-policy=OVERRIDE, i-signal-type=PRIMITIVE, init-value=0, base-type=BT_RGB_Slave_15_LedBlauStg, invalid-value=Invalid_RGB_Slave_15_LedBlauStg_XIX_RGBs_Slave_15_XIX_E3V_SAM_LIN5:3, compu {0=Cx0_Init (CM_RGB_Slave_15_LedBlauStg_Cx0_Init), 1=Cx1_nicht_erlaubt (CM_RGB_Slave_15_LedBlauStg_Cx1_nicht_erlaubt), 2=Cx2_kein_Fehler (CM_RGB_Slave_15_LedBlauStg_Cx2_kein_Fehler), 3=Cx3_Fehler (CM_RGB_Slave_15_LedBlauStg_Cx3_Fehler)}, range raw 0..3, transfer-property=PENDING, to SAM(timeout 3.5 s)  # Short To Ground für Blaue LED
            signal RGB_Slave_15_LedRotOl_XIX_RGBs_Slave_15_XIX_E3V_SAM_LIN5: start 14, 2 bit, little-endian, data-type-policy=OVERRIDE, i-signal-type=PRIMITIVE, init-value=0, base-type=BT_RGB_Slave_15_LedRotOl, invalid-value=Invalid_RGB_Slave_15_LedRotOl_XIX_RGBs_Slave_15_XIX_E3V_SAM_LIN5:3, compu {0=Cx0_Init (CM_RGB_Slave_15_LedRotOl_Cx0_Init), 1=Cx1_nicht_erlaubt (CM_RGB_Slave_15_LedRotOl_Cx1_nicht_erlaubt), 2=Cx2_kein_Fehler (CM_RGB_Slave_15_LedRotOl_Cx2_kein_Fehler), 3=Cx3_Fehler (CM_RGB_Slave_15_LedRotOl_Cx3_Fehler)}, range raw 0..3, transfer-property=PENDING, to SAM(timeout 3.5 s)  # OpenLoad für Rote LED
            signal RGB_Slave_15_LedGruenOl_XIX_RGBs_Slave_15_XIX_E3V_SAM_LIN5: start 16, 2 bit, little-endian, data-type-policy=OVERRIDE, i-signal-type=PRIMITIVE, init-value=0, base-type=BT_RGB_Slave_15_LedGruenOl, invalid-value=Invalid_RGB_Slave_15_LedGruenOl_XIX_RGBs_Slave_15_XIX_E3V_SAM_LIN5:3, compu {0=Cx0_Init (CM_RGB_Slave_15_LedGruenOl_Cx0_Init), 1=Cx1_nicht_erlaubt (CM_RGB_Slave_15_LedGruenOl_Cx1_nicht_erlaubt), 2=Cx2_kein_Fehler (CM_RGB_Slave_15_LedGruenOl_Cx2_kein_Fehler), 3=Cx3_Fehler (CM_RGB_Slave_15_LedGruenOl_Cx3_Fehler)}, range raw 0..3, transfer-property=PENDING, to SAM(timeout 3.5 s)  # OpenLoad für Rote LED
            signal RGB_Slave_15_LedBlauOl_XIX_RGBs_Slave_15_XIX_E3V_SAM_LIN5: start 18, 2 bit, little-endian, data-type-policy=OVERRIDE, i-signal-type=PRIMITIVE, init-value=0, base-type=BT_RGB_Slave_15_LedBlauOl, invalid-value=Invalid_RGB_Slave_15_LedBlauOl_XIX_RGBs_Slave_15_XIX_E3V_SAM_LIN5:3, compu {0=Cx0_Init (CM_RGB_Slave_15_LedBlauOl_Cx0_Init), 1=Cx1_nicht_erlaubt (CM_RGB_Slave_15_LedBlauOl_Cx1_nicht_erlaubt), 2=Cx2_kein_Fehler (CM_RGB_Slave_15_LedBlauOl_Cx2_kein_Fehler), 3=Cx3_Fehler (CM_RGB_Slave_15_LedBlauOl_Cx3_Fehler)}, range raw 0..3, transfer-property=PENDING, to SAM(timeout 3.5 s)  # OpenLoad für Blaue LED
            signal RGB_Slave_15_TempState_XIX_RGBs_Slave_15_XIX_E3V_SAM_LIN5: start 20, 3 bit, little-endian, data-type-policy=OVERRIDE, i-signal-type=PRIMITIVE, base-type=BT_RGB_Slave_15_TempState, compu {0=Cx0_keine_Temperaturregelung (CM_RGB_Slave_15_TempState_Cx0_keine_Temperaturregelung), 1=Cx1_Regelstufe_1 (CM_RGB_Slave_15_TempState_Cx1_Regelstufe_1), 2=Cx2_Regelstufe_2 (CM_RGB_Slave_15_TempState_Cx2_Regelstufe_2), 3=Cx3_Regelstufe_3 (CM_RGB_Slave_15_TempState_Cx3_Regelstufe_3), 4=Cx4_Regelstufe_4 (CM_RGB_Slave_15_TempState_Cx4_Regelstufe_4), 5=Cx5_Regelstufe_5 (CM_RGB_Slave_15_TempState_Cx5_Regelstufe_5), 6=Cx6_Regelstufe_6 (CM_RGB_Slave_15_TempState_Cx6_Regelstufe_6), 7=Cx7_Regelstufe_7 (CM_RGB_Slave_15_TempState_Cx7_Regelstufe_7)}, range raw 0..7, transfer-property=PENDING, to SAM(timeout 3.5 s)  # Status Temperaturregelung
            signal RGB_Slave_15_IntErrorRam_XIX_RGBs_Slave_15_XIX_E3V_SAM_LIN5: start 24, 2 bit, little-endian, data-type-policy=OVERRIDE, i-signal-type=PRIMITIVE, init-value=0, base-type=BT_RGB_Slave_15_IntErrorRam, invalid-value=Invalid_RGB_Slave_15_IntErrorRam_XIX_RGBs_Slave_15_XIX_E3V_SAM_LIN5:3, compu {0=Cx0_Init (CM_RGB_Slave_15_IntErrorRam_Cx0_Init), 1=Cx1_nicht_erlaubt (CM_RGB_Slave_15_IntErrorRam_Cx1_nicht_erlaubt), 2=Cx2_kein_Fehler (CM_RGB_Slave_15_IntErrorRam_Cx2_kein_Fehler), 3=Cx3_Fehler (CM_RGB_Slave_15_IntErrorRam_Cx3_Fehler)}, range raw 0..3, transfer-property=PENDING, to SAM(timeout 3.5 s)  # Fehler im RAM
            signal RGB_Slave_15_IntErrorRom_XIX_RGBs_Slave_15_XIX_E3V_SAM_LIN5: start 26, 2 bit, little-endian, data-type-policy=OVERRIDE, i-signal-type=PRIMITIVE, init-value=0, base-type=BT_RGB_Slave_15_IntErrorRom, invalid-value=Invalid_RGB_Slave_15_IntErrorRom_XIX_RGBs_Slave_15_XIX_E3V_SAM_LIN5:3, compu {0=Cx0_Init (CM_RGB_Slave_15_IntErrorRom_Cx0_Init), 1=Cx1_nicht_erlaubt (CM_RGB_Slave_15_IntErrorRom_Cx1_nicht_erlaubt), 2=Cx2_kein_Fehler (CM_RGB_Slave_15_IntErrorRom_Cx2_kein_Fehler), 3=Cx3_Fehler (CM_RGB_Slave_15_IntErrorRom_Cx3_Fehler)}, range raw 0..3, transfer-property=PENDING, to SAM(timeout 3.5 s)  # Fehler im ROM
            signal RGB_Slave_15_IntErrorNvm_XIX_RGBs_Slave_15_XIX_E3V_SAM_LIN5: start 28, 2 bit, little-endian, data-type-policy=OVERRIDE, i-signal-type=PRIMITIVE, init-value=0, base-type=BT_RGB_Slave_15_IntErrorNvm, invalid-value=Invalid_RGB_Slave_15_IntErrorNvm_XIX_RGBs_Slave_15_XIX_E3V_SAM_LIN5:3, compu {0=Cx0_Init (CM_RGB_Slave_15_IntErrorNvm_Cx0_Init), 1=Cx1_nicht_erlaubt (CM_RGB_Slave_15_IntErrorNvm_Cx1_nicht_erlaubt), 2=Cx2_kein_Fehler (CM_RGB_Slave_15_IntErrorNvm_Cx2_kein_Fehler), 3=Cx3_Fehler (CM_RGB_Slave_15_IntErrorNvm_Cx3_Fehler)}, range raw 0..3, transfer-property=PENDING, to SAM(timeout 3.5 s)  # Fehler im NVM
        frame SlaveResp_XIX_E3V_SAM_LIN5: id 0x3D, to SAM, frame-length=8, lin-checksum=CLASSIC
          n pdu SlaveResp_XIX_E3V_SAM_LIN5: length=8
        lin schedule table DiagRequest: resume-position=CONTINUE-AT-IT-POSITION, run-mode=RUN-ONCE, application-entry{delay=0.01, position-in-table=0, frame-triggering=CHNL/FT_MasterReq}
        lin schedule table DiagResponse: resume-position=CONTINUE-AT-IT-POSITION, run-mode=RUN-ONCE, application-entry{delay=0.01, position-in-table=0, frame-triggering=CHNL/FT_SlaveResp}
        lin schedule table ST1: resume-position=CONTINUE-AT-IT-POSITION, run-mode=RUN-CONTINUOUS
          table-entrys:
            delay=0.01, position-in-table={0..8}, frame-triggering=CHNL/FT_RGBe_Slave
            delay=0.01, position-in-table=9, frame-triggering=CHNL/FT_RGBs_Slave_01
            delay=0.01, position-in-table={10..18}, frame-triggering=CHNL/FT_RGBe_Slave
            delay=0.01, position-in-table=19, frame-triggering=CHNL/FT_RGBs_Slave_02
            delay=0.01, position-in-table={20..28}, frame-triggering=CHNL/FT_RGBe_Slave
            delay=0.01, position-in-table=29, frame-triggering=CHNL/FT_RGBs_Slave_03
            delay=0.01, position-in-table={30..38}, frame-triggering=CHNL/FT_RGBe_Slave
            delay=0.01, position-in-table=39, frame-triggering=CHNL/FT_RGBs_Slave_04
            delay=0.01, position-in-table={40..48}, frame-triggering=CHNL/FT_RGBe_Slave
            delay=0.01, position-in-table=49, frame-triggering=CHNL/FT_RGBs_Slave_05
            delay=0.01, position-in-table={50..58}, frame-triggering=CHNL/FT_RGBe_Slave
            delay=0.01, position-in-table=59, frame-triggering=CHNL/FT_RGBs_Slave_06
            delay=0.01, position-in-table={60..68}, frame-triggering=CHNL/FT_RGBe_Slave
            delay=0.01, position-in-table=69, frame-triggering=CHNL/FT_RGBs_Slave_07
            delay=0.01, position-in-table={70..78}, frame-triggering=CHNL/FT_RGBe_Slave
            delay=0.01, position-in-table=79, frame-triggering=CHNL/FT_RGBs_Slave_08
            delay=0.01, position-in-table={80..88}, frame-triggering=CHNL/FT_RGBe_Slave
            delay=0.01, position-in-table=89, frame-triggering=CHNL/FT_RGBs_Slave_09
            delay=0.01, position-in-table={90..98}, frame-triggering=CHNL/FT_RGBe_Slave
            delay=0.01, position-in-table=99, frame-triggering=CHNL/FT_RGBs_Slave_10
            delay=0.01, position-in-table={100..108}, frame-triggering=CHNL/FT_RGBe_Slave
            delay=0.01, position-in-table=109, frame-triggering=CHNL/FT_RGBs_Slave_11
            delay=0.01, position-in-table={110..118}, frame-triggering=CHNL/FT_RGBe_Slave
            delay=0.01, position-in-table=119, frame-triggering=CHNL/FT_RGBs_Slave_12
            delay=0.01, position-in-table={120..128}, frame-triggering=CHNL/FT_RGBe_Slave
            delay=0.01, position-in-table=129, frame-triggering=CHNL/FT_RGBs_Slave_13
            delay=0.01, position-in-table={130..138}, frame-triggering=CHNL/FT_RGBe_Slave
            delay=0.01, position-in-table=139, frame-triggering=CHNL/FT_RGBs_Slave_14
            delay=0.01, position-in-table={140..148}, frame-triggering=CHNL/FT_RGBe_Slave
            delay=0.01, position-in-table=149, frame-triggering=CHNL/FT_RGBs_Slave_15
